VERSION "HNNBNNNYNNNNNNNNNNNNNNNNNNNNNNNNNNNNNNNNNN/4/%%%/4/'%**4NNN///"

NS_ :

BS_:

BU_: BAP_Tester BMS_NV_12V Gateway_Max Klima

BO_ 64 Airbag_01: 8 Gateway_Max
 SG_ Airbag_01_CRC : 0|8@1+ (1,0) [0|255] ""  Klima
 SG_ Airbag_01_BZ : 8|4@1+ (1,0) [0|15] ""  Klima
 SG_ AB_RGS_Anst : 12|4@1+ (1.0,0.0) [0.0|15] ""  Vector__XXX
 SG_ AB_Front_Crash : 16|1@1+ (1.0,0.0) [0.0|1] ""  Vector__XXX
 SG_ AB_Heck_Crash : 17|1@1+ (1.0,0.0) [0.0|1] ""  Vector__XXX
 SG_ AB_SF_Crash : 18|1@1+ (1.0,0.0) [0.0|1] ""  Vector__XXX
 SG_ AB_SB_Crash : 19|1@1+ (1.0,0.0) [0.0|1] ""  Vector__XXX
 SG_ AB_Rollover_Crash : 20|1@1+ (1.0,0.0) [0.0|1] ""  Vector__XXX
 SG_ AB_Crash_Int : 21|3@1+ (1.0,0.0) [0.0|7] ""  Klima
 SG_ AB_Lampe : 24|1@1+ (1.0,0.0) [0.0|1] ""  Vector__XXX
 SG_ AB_Deaktiviert : 25|1@1+ (1.0,0.0) [0.0|1] ""  Vector__XXX
 SG_ AB_VB_deaktiviert : 26|1@1+ (1.0,0.0) [0.0|1] ""  Vector__XXX
 SG_ AB_Systemfehler : 27|1@1+ (1.0,0.0) [0.0|1] ""  Vector__XXX
 SG_ AB_Diagnose : 28|1@1+ (1.0,0.0) [0.0|1] ""  Vector__XXX
 SG_ AB_Stellgliedtest : 29|1@1+ (1.0,0.0) [0.0|1] ""  Klima
 SG_ AB_Erh_Auf_VB : 30|2@1+ (1.0,0.0) [0.0|3] ""  Vector__XXX
 SG_ AB_Gurtwarn_VF : 32|1@1+ (1.0,0.0) [0.0|1] ""  Vector__XXX
 SG_ AB_Gurtwarn_VB : 33|1@1+ (1.0,0.0) [0.0|1] ""  Vector__XXX
 SG_ AB_Anzeige_Fussg : 34|2@1+ (1.0,0.0) [0.0|3] ""  Vector__XXX
 SG_ AB_Texte_AKS : 36|2@1+ (1.0,0.0) [0.0|3] ""  Vector__XXX
 SG_ AB_PAO_Leuchte_Anf : 38|1@1+ (1.0,0.0) [0.0|1] ""  Vector__XXX
 SG_ AB_MKB_gueltig : 39|1@1+ (1.0,0.0) [0.0|1] ""  Vector__XXX
 SG_ AB_MKB_Anforderung : 40|1@1+ (1.0,0.0) [0.0|1] ""  Vector__XXX
 SG_ AB_Versorgungsspannung : 41|1@1+ (1.0,0.0) [0.0|1] ""  Vector__XXX
 SG_ AB_Deaktivierung_HV : 42|3@1+ (1.0,0.0) [0.0|7] ""  Klima
 SG_ AB_EDR_Trigger : 45|2@1+ (1.0,0.0) [0.0|3] ""  Vector__XXX
 SG_ AB_Belegung_VF : 47|2@1+ (1.0,0.0) [0.0|3] ""  Klima
 SG_ AB_Gurtschloss_FA_ext : 49|3@1+ (1.0,0.0) [0.0|7] ""  Vector__XXX
 SG_ AB_Gurtschloss_FA_ext_aktiv : 52|1@1+ (1.0,0.0) [0.0|1] ""  Vector__XXX
 SG_ AB_eCS_Error : 53|1@1+ (1.0,0.0) [0.0|1] ""  Vector__XXX
 SG_ ASM_Masterzeit_02 : 56|8@1+ (0.04,0) [0.00|10.16] "Unit_Secon"  Vector__XXX

BO_ 1312 Airbag_02: 8 Gateway_Max
 SG_ Airbag_02_CRC : 0|8@1+ (1,0) [0|255] ""  Vector__XXX
 SG_ Airbag_02_BZ : 8|4@1+ (1,0) [0|15] ""  Vector__XXX
 SG_ LoGeWa_Event_Kombiwarnung : 12|4@1+ (1.0,0.0) [0.0|15] ""  Vector__XXX
 SG_ AB_Anforderung_eCall : 16|1@1+ (1.0,0.0) [0.0|1] ""  Vector__XXX
 SG_ AB_Anprall_Seite_Beifahrer : 17|1@1+ (1.0,0.0) [0.0|1] ""  Vector__XXX
 SG_ AB_Anprall_Rollover : 18|1@1+ (1.0,0.0) [0.0|1] ""  Vector__XXX
 SG_ AB_Anprall_FGS : 19|1@1+ (1.0,0.0) [0.0|1] ""  Vector__XXX
 SG_ AB_Anprall_Front_Beifahrer : 20|1@1+ (1.0,0.0) [0.0|1] ""  Vector__XXX
 SG_ AB_Anprall_Front_Fahrer : 21|1@1+ (1.0,0.0) [0.0|1] ""  Vector__XXX
 SG_ AB_Anprall_Heck_Beifahrer : 22|1@1+ (1.0,0.0) [0.0|1] ""  Vector__XXX
 SG_ AB_Anprall_Heck_Fahrer : 23|1@1+ (1.0,0.0) [0.0|1] ""  Vector__XXX
 SG_ AB_Wickelklappung_Reihe2_MI : 24|2@1+ (1.0,0.0) [0.0|3] ""  Vector__XXX
 SG_ AB_Belegung_VB : 26|2@1+ (1.0,0.0) [0.0|3] ""  Klima
 SG_ AB_Abschaltanf_SIH_BF : 28|1@1+ (1.0,0.0) [0.0|1] ""  Klima
 SG_ AB_Anprall_Seite_Fahrer : 29|1@1+ (1.0,0.0) [0.0|1] ""  Vector__XXX
 SG_ SC_PAO_Schriftzug_Anf : 30|2@1+ (1.0,0.0) [0.0|3] ""  Vector__XXX
 SG_ SC_PAO_ON_Anf : 32|2@1+ (1.0,0.0) [0.0|3] ""  Vector__XXX
 SG_ SC_PAO_OFF_Anf : 34|2@1+ (1.0,0.0) [0.0|3] ""  Vector__XXX
 SG_ AB_Crashschwere : 36|3@1+ (1.0,0.0) [0.0|7] ""  Vector__XXX
 SG_ AB_Anforderung_USM : 39|1@1+ (1.0,0.0) [0.0|1] ""  Vector__XXX
 SG_ AB_Gurtschloss_FA : 40|2@1+ (1.0,0.0) [0.0|3] ""  Klima
 SG_ AB_Gurtschloss_BF : 42|2@1+ (1.0,0.0) [0.0|3] ""  Klima
 SG_ AB_Gurtschloss_Reihe2_FA : 44|2@1+ (1.0,0.0) [0.0|3] ""  Klima
 SG_ AB_Gurtschloss_Reihe2_MI : 46|2@1+ (1.0,0.0) [0.0|3] ""  Klima
 SG_ AB_Gurtschloss_Reihe2_BF : 48|2@1+ (1.0,0.0) [0.0|3] ""  Klima
 SG_ AB_Gurtschloss_Reihe3_FA : 50|2@1+ (1.0,0.0) [0.0|3] ""  Klima
 SG_ AB_Gurtschloss_Reihe3_MI : 52|2@1+ (1.0,0.0) [0.0|3] ""  Klima
 SG_ AB_Gurtschloss_Reihe3_BF : 54|2@1+ (1.0,0.0) [0.0|3] ""  Klima
 SG_ AB_Sitzpos_Sens_FA : 56|2@1+ (1.0,0.0) [0.0|3] ""  Vector__XXX
 SG_ AB_Sitzpos_Sens_BF : 58|2@1+ (1.0,0.0) [0.0|3] ""  Vector__XXX
 SG_ AB_Wickelklappung_Reihe2_BF : 60|2@1+ (1.0,0.0) [0.0|3] ""  Vector__XXX
 SG_ AB_Wickelklappung_Reihe2_FA : 62|2@1+ (1.0,0.0) [0.0|3] ""  Vector__XXX

BO_ 1349 Airbag_04: 8 Gateway_Max
 SG_ Airbag_04_CRC : 0|8@1+ (1,0) [0|255] ""  Vector__XXX
 SG_ Airbag_04_BZ : 8|4@1+ (1,0) [0|15] ""  Vector__XXX
 SG_ AB_Anprall_Front : 12|1@1+ (1.0,0.0) [0.0|1] ""  Vector__XXX
 SG_ AB_Anprall_Heck : 13|1@1+ (1.0,0.0) [0.0|1] ""  Vector__XXX
 SG_ AB_Gurtwarn_Reihe4_FA : 14|2@1+ (1.0,0.0) [0.0|3] ""  Vector__XXX
 SG_ AB_Gurtwarn_Reihe4_BF : 16|2@1+ (1.0,0.0) [0.0|3] ""  Vector__XXX
 SG_ AB_Gurtwarn_Reihe4_MI : 18|2@1+ (1.0,0.0) [0.0|3] ""  Vector__XXX
 SG_ AB_Gurtwarn_Reihe2_FA : 20|2@1+ (1.0,0.0) [0.0|3] ""  Klima
 SG_ AB_Gurtwarn_Reihe2_BF : 22|2@1+ (1.0,0.0) [0.0|3] ""  Klima
 SG_ AbstWarn_MV_FAS_Fkt_Status : 24|2@1+ (1.0,0.0) [0.0|3] ""  Vector__XXX
 SG_ WarnBrems_Charisma_Status : 26|2@1+ (1.0,0.0) [0.0|3] ""  Vector__XXX
 SG_ WarnBrems_Charisma_FahrPr : 28|4@1+ (1.0,0.0) [0.0|15] ""  Vector__XXX
 SG_ AB_Gurtwarn_Reihe2_MI : 32|2@1+ (1.0,0.0) [0.0|3] ""  Klima
 SG_ AB_Gurtwarn_Reihe3_FA : 34|2@1+ (1.0,0.0) [0.0|3] ""  Vector__XXX
 SG_ AB_Gurtwarn_Reihe3_MI : 36|2@1+ (1.0,0.0) [0.0|3] ""  Vector__XXX
 SG_ AB_Gurtwarn_Reihe3_BF : 38|2@1+ (1.0,0.0) [0.0|3] ""  Vector__XXX
 SG_ LGI_FAS_Fkt_Status : 40|2@1+ (1.0,0.0) [0.0|3] ""  Vector__XXX
 SG_ PreCrash_FAS_Fkt_Status : 42|3@1+ (1.0,0.0) [0.0|7] ""  Vector__XXX
 SG_ AB_Belegung_VF_ext : 45|3@1+ (1.0,0.0) [0.0|7] ""  Klima
 SG_ AB_SBR_hinten_verbau : 48|2@1+ (1.0,0.0) [0.0|3] ""  Klima
 SG_ AB_Belegung_VF_ext_aktiv : 50|1@1+ (1.0,0.0) [0.0|1] ""  Vector__XXX
 SG_ AWV_Einstellung_System_ASG : 51|1@1+ (1.0,0.0) [0.0|1] ""  Vector__XXX
 SG_ AWV_Einstellung_Warnung_ASG : 52|3@1+ (1.0,0.0) [0.0|7] ""  Vector__XXX
 SG_ SC_PreSense_Modus_Warnung_NV : 55|3@1+ (1.0,0.0) [0.0|7] ""  Vector__XXX
 SG_ SC_PreSense_Modus_Warnung_MV : 58|3@1+ (1.0,0.0) [0.0|7] ""  Vector__XXX
 SG_ SC_PreSense_Modus_System_MV : 61|1@1+ (1.0,0.0) [0.0|1] ""  Vector__XXX
 SG_ SC_PreSense_Modus_System_NV : 62|1@1+ (1.0,0.0) [0.0|1] ""  Vector__XXX
 SG_ SC_PreSense_Modus_System_KAS : 63|1@1+ (1.0,0.0) [0.0|1] ""  Vector__XXX

BO_ 2536726528 BAP_ClimateDiag_ASG_01: 8 Gateway_Max
 SG_ BAP_ClimateDiag_ASG_01_Header : 0|64@1+ (1.0,0.0) [0.0|18446744073709551615] ""  Klima

BO_ 2536726544 BAP_ClimateDiag_FSG_01: 8 Klima
 SG_ BAP_ClimateDiag_FSG_01_Header : 0|64@1+ (1.0,0.0) [0.0|18446744073709551615] ""  Gateway_Max

BO_ 2536767264 BAP_Debug_Cmd: 8 BAP_Tester
 SG_ BAP_Debug_Cmd : 0|16@1+ (1.0,0.0) [0.0|65535] ""  Klima

BO_ 2536767280 BAP_Debug_Data: 8 Klima
 SG_ BAP_Debug_Data : 0|64@1+ (1.0,0.0) [0.0|18446744073709551615] ""  BAP_Tester

BO_ 2536702208 BAP_Klima1_ASG_01: 8 Gateway_Max
 SG_ BAP_Klima1_ASG_01_Header : 0|64@1+ (1.0,0.0) [0.0|18446744073709551615] ""  Klima

BO_ 2536702224 BAP_Klima1_FSG_01: 8 Klima
 SG_ BAP_Klima1_FSG_01_Header : 0|64@1+ (1.0,0.0) [0.0|18446744073709551615] ""  Gateway_Max

BO_ 2536702464 BAP_Klima2_ASG_01: 8 Gateway_Max
 SG_ BAP_Klima2_ASG_01_Header : 0|64@1+ (1.0,0.0) [0.0|18446744073709551615] ""  Klima

BO_ 2536702466 BAP_Klima2_ASG_03: 8 Gateway_Max
 SG_ BAP_Klima2_ASG_03_Header : 0|8@1+ (1.0,0.0) [0.0|255] ""  Klima

BO_ 2536702468 BAP_Klima2_ASG_05: 8 Gateway_Max
 SG_ BAP_Klima2_ASG_05_Header : 0|64@1+ (1.0,0.0) [0.0|18446744073709551615] ""  Klima

BO_ 2536702480 BAP_Klima2_FSG_01: 8 Klima
 SG_ BAP_Klima2_FSG_01_Header : 0|8@1+ (1.0,0.0) [0.0|255] ""  Gateway_Max

BO_ 2536718848 BAP_KlimaMaster_ASG_01: 8 Gateway_Max
 SG_ BAP_KlimaMaster_ASG_01_Header : 0|8@1+ (1,0) [0|255] "Unit_None"  Klima

BO_ 2536718849 BAP_KlimaMaster_ASG_02: 8 Gateway_Max
 SG_ BAP_KlimaMaster_ASG_02_Header : 0|8@1+ (1,0) [0|255] "Unit_None"  Klima

BO_ 2536718850 BAP_KlimaMaster_ASG_03: 8 Gateway_Max
 SG_ BAP_KlimaMaster_ASG_03_Header : 0|8@1+ (1,0) [0|255] "Unit_None"  Klima

BO_ 2536718851 BAP_KlimaMaster_ASG_04: 8 Gateway_Max
 SG_ BAP_KlimaMaster_ASG_04_Header : 0|8@1+ (1,0) [0|255] "Unit_None"  Klima

BO_ 2536718864 BAP_KlimaMaster_FSG_01: 8 Klima
 SG_ BAP_KlimaMaster_FSG_01_Header : 0|8@1+ (1,0) [0|255] "Unit_None"  Gateway_Max

BO_ 1626 BCM_01: 8 Gateway_Max
 SG_ BCM_Bremsbelag_Sensor : 12|1@1+ (1.0,0.0) [0.0|1] ""  Vector__XXX
 SG_ BCM_Bremsfluessigkeit_Sensor : 13|1@1+ (1.0,0.0) [0.0|1] ""  Vector__XXX
 SG_ BCM1_Licht_Warn : 14|1@1+ (1.0,0.0) [0.0|1] ""  Vector__XXX
 SG_ BCM_Waschwasser_Sensor : 15|1@1+ (1.0,0.0) [0.0|1] ""  Vector__XXX
 SG_ BCM_Kuehlmittel_Sensor : 16|1@1+ (1.0,0.0) [0.0|1] ""  Vector__XXX
 SG_ BCM1_Kl_15_HW_erkannt : 17|1@1+ (1.0,0.0) [0.0|1] ""  Vector__XXX
 SG_ BCM1_Kl_15_Sig_HW_erkannt : 18|1@1+ (1.0,0.0) [0.0|1] ""  Vector__XXX
 SG_ BCM_Kuehlmittel_Sensor_02 : 19|1@1+ (1.0,0.0) [0.0|1] ""  Vector__XXX
 SG_ BCM1_Hinweis_Lichtnachlauf : 20|1@1+ (1.0,0.0) [0.0|1] ""  Vector__XXX
 SG_ BCM_Offroad_Taste : 21|1@1+ (1.0,0.0) [0.0|1] ""  Vector__XXX
 SG_ BCM_Charisma_Taste2 : 22|1@1+ (1.0,0.0) [0.0|1] ""  Vector__XXX
 SG_ BCM_Hybrid_StSt_Taste_Fehler : 23|1@1+ (1.0,0.0) [0.0|1] ""  Vector__XXX
 SG_ BCM_Hybrid_StartStopp_Taste : 24|1@1+ (1.0,0.0) [0.0|1] ""  Vector__XXX
 SG_ BCM1_Warnblink_Taster : 25|1@1+ (1.0,0.0) [0.0|1] ""  Vector__XXX
 SG_ BCM1_Valet_Parking_Taster : 26|1@1+ (1.0,0.0) [0.0|1] ""  Vector__XXX
 SG_ BCM1_LDS_Stellung : 27|3@1+ (1.0,0.0) [0.0|7] ""  Vector__XXX
 SG_ BCM1_Rueckfahrlicht_Schalter : 30|1@1+ (1.0,0.0) [0.0|1] ""  Klima
 SG_ BCM1_MH_Schalter : 31|1@1+ (1.0,0.0) [0.0|1] ""  Vector__XXX
 SG_ BCM1_MH_WIV_Schalter : 32|1@1+ (1.0,0.0) [0.0|1] ""  Vector__XXX
 SG_ BCM_Eco_Charisma_Taste : 33|1@1+ (1.0,0.0) [0.0|1] ""  Vector__XXX
 SG_ BCM1_NV_Taster : 34|1@1+ (1.0,0.0) [0.0|1] ""  Vector__XXX
 SG_ BCM1_AFS_Lampe : 35|1@1+ (1.0,0.0) [0.0|1] ""  Vector__XXX
 SG_ BCM1_Reisemodus_Texte : 36|2@1+ (1.0,0.0) [0.0|3] ""  Vector__XXX
 SG_ BCM1_Lichtwarn_Texte : 38|2@1+ (1.0,0.0) [0.0|3] ""  Vector__XXX
 SG_ Gong_TFL_Umschaltung : 40|1@1+ (1.0,0.0) [0.0|1] ""  Vector__XXX
 SG_ BCM_ValetTaster_Fkts_LED : 42|1@1+ (1.0,0.0) [0.0|1] ""  Vector__XXX
 SG_ LRH_Taster : 43|1@1+ (1.0,0.0) [0.0|1] ""  Vector__XXX
 SG_ APS_Tongeber_defekt : 44|1@1+ (1.0,0.0) [0.0|1] ""  Vector__XXX
 SG_ BCM1_EasyEntry_Status : 45|1@1+ (1.0,0.0) [0.0|1] ""  Vector__XXX
 SG_ BCM1_Lenksaeule_aktiv : 46|1@1+ (1.0,0.0) [0.0|1] ""  Vector__XXX
 SG_ BCM1_Spannungs_Anf : 47|2@1+ (1.0,0.0) [0.0|3] ""  Vector__XXX
 SG_ DWA_Alarmquelle : 49|5@1+ (1.0,0.0) [0.0|31] ""  Vector__XXX
 SG_ DWA_Einschraenkung : 54|1@1+ (1.0,0.0) [0.0|1] ""  Vector__XXX
 SG_ BCM_HBFS_EOE_aktiv : 56|1@1+ (1.0,0.0) [0.0|1] ""  Vector__XXX
 SG_ BCM_HFS_EOE_aktiv : 57|1@1+ (1.0,0.0) [0.0|1] ""  Vector__XXX
 SG_ BCM_Anf_AAW_MoLaWa : 58|2@1+ (1.0,0.0) [0.0|3] ""  Vector__XXX
 SG_ BCM_Handbremse_Hinweis : 60|1@1+ (1.0,0.0) [0.0|1] ""  Vector__XXX
 SG_ BCM_Waehlhebel_P_Hinweis : 61|1@1+ (1.0,0.0) [0.0|1] ""  Vector__XXX
 SG_ BCM1_Fahrlicht_Hinweis : 62|1@1+ (1.0,0.0) [0.0|1] ""  Vector__XXX
 SG_ BCM_HDF_betaetigt : 63|1@1+ (1.0,0.0) [0.0|1] ""  Vector__XXX

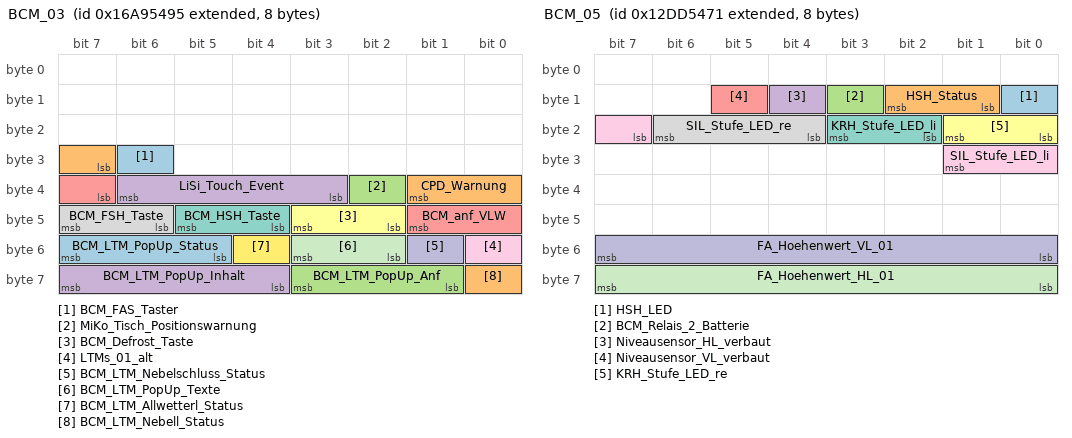
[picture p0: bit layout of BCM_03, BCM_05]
BO_ 2527679637 BCM_03: 8 Gateway_Max
 SG_ BCM_FAS_Taster : 30|1@1+ (1.0,0.0) [0.0|1] ""  Vector__XXX
 SG_ CPD_Warnung : 31|3@1+ (1.0,0.0) [0.0|7] ""  Vector__XXX
 SG_ MiKo_Tisch_Positionswarnung : 34|1@1+ (1.0,0.0) [0.0|1] ""  Vector__XXX
 SG_ LiSi_Touch_Event : 35|4@1+ (1.0,0.0) [0.0|15] ""  Vector__XXX
 SG_ BCM_anf_VLW : 39|3@1+ (1.0,0.0) [0.0|7] ""  Vector__XXX
 SG_ BCM_Defrost_Taste : 42|2@1+ (1.0,0.0) [0.0|3] ""  Klima
 SG_ BCM_HSH_Taste : 44|2@1+ (1.0,0.0) [0.0|3] ""  Klima
 SG_ BCM_FSH_Taste : 46|2@1+ (1.0,0.0) [0.0|3] ""  Klima
 SG_ LTMs_01_alt : 48|1@1+ (1.0,0.0) [0.0|1] ""  Klima
 SG_ BCM_LTM_Nebelschluss_Status : 49|1@1+ (1.0,0.0) [0.0|1] ""  Vector__XXX
 SG_ BCM_LTM_PopUp_Texte : 50|2@1+ (1.0,0.0) [0.0|3] ""  Vector__XXX
 SG_ BCM_LTM_Allwetterl_Status : 52|1@1+ (1.0,0.0) [0.0|1] ""  Vector__XXX
 SG_ BCM_LTM_PopUp_Status : 53|3@1+ (1.0,0.0) [0.0|7] ""  Vector__XXX
 SG_ BCM_LTM_Nebell_Status : 56|1@1+ (1.0,0.0) [0.0|1] ""  Vector__XXX
 SG_ BCM_LTM_PopUp_Anf : 57|3@1+ (1.0,0.0) [0.0|7] ""  Vector__XXX
 SG_ BCM_LTM_PopUp_Inhalt : 60|4@1+ (1.0,0.0) [0.0|15] ""  Vector__XXX

BO_ 2463978609 BCM_05: 8 Gateway_Max
 SG_ HSH_LED : 8|1@1+ (1.0,0.0) [0.0|1] ""  Vector__XXX
 SG_ HSH_Status : 9|2@1+ (1.0,0.0) [0.0|3] ""  Klima
 SG_ BCM_Relais_2_Batterie : 11|1@1+ (1.0,0.0) [0.0|1] ""  Vector__XXX
 SG_ Niveausensor_HL_verbaut : 12|1@1+ (1.0,0.0) [0.0|1] ""  Vector__XXX
 SG_ Niveausensor_VL_verbaut : 13|1@1+ (1.0,0.0) [0.0|1] ""  Vector__XXX
 SG_ KRH_Stufe_LED_re : 16|2@1+ (1.0,0.0) [0.0|3] ""  Klima
 SG_ KRH_Stufe_LED_li : 18|2@1+ (1.0,0.0) [0.0|3] ""  Klima
 SG_ SIL_Stufe_LED_re : 20|3@1+ (1.0,0.0) [0.0|7] ""  Klima
 SG_ SIL_Stufe_LED_li : 23|3@1+ (1.0,0.0) [0.0|7] ""  Klima
 SG_ FA_Hoehenwert_VL_01 : 48|8@1+ (0.4,0) [0.0|100.0] "Unit_PerCent"  Vector__XXX
 SG_ FA_Hoehenwert_HL_01 : 56|8@1+ (0.4,0) [0.0|100.0] "Unit_PerCent"  Vector__XXX

BO_ 1635 BEM_02: 8 Gateway_Max
 SG_ NVEM_Abschaltstufe : 0|2@1+ (1.0,0.0) [0.0|3] ""  Klima
 SG_ BEM_STH_Zielzeit : 3|4@1+ (5,0) [0|60] "Unit_Minut"  Klima
 SG_ BEM_MMI_Vorwarnung : 7|1@1+ (1.0,0.0) [0.0|1] ""  Vector__XXX
 SG_ BEM_HL_Kontingentierung : 8|6@1+ (50,-1000) [-1000|1000] "Unit_Watt"  Vector__XXX
 SG_ NVEM_Freigabe_ZusBatt_Laden : 14|1@1+ (1.0,0.0) [0.0|1] ""  Vector__XXX
 SG_ NVEM_Anf_SD_schalten : 15|1@1+ (1.0,0.0) [0.0|1] ""  Vector__XXX
 SG_ BEM_Generatordiagnose : 16|2@1+ (1.0,0.0) [0.0|3] ""  Vector__XXX
 SG_ BEM_Red_Innengeblaese : 18|2@1+ (1.0,0.0) [0.0|3] ""  Klima
 SG_ BEM_STH_Einschaltverbot : 20|1@1+ (1.0,0.0) [0.0|1] ""  Klima
 SG_ BEM_HL_Regelung_Status : 21|3@1+ (1.0,0.0) [0.0|7] ""  Vector__XXX
 SG_ BEM_Ladezustand : 24|4@1+ (10,0) [0|100] "Unit_PerCent"  Vector__XXX
 SG_ BEM_Batteriediagnose : 28|3@1+ (1.0,0.0) [0.0|7] ""  Vector__XXX
 SG_ MIB_Stromsparmodus : 31|1@1+ (1.0,0.0) [0.0|1] ""  Vector__XXX
 SG_ BEM_DFM : 32|5@1+ (3.225,0.025) [0.025|100.000] ""  Vector__XXX
 SG_ BEM_REK_aktiv : 37|1@1+ (1.0,0.0) [0.0|1] ""  Vector__XXX
 SG_ BEM_EMLIN_ungueltig : 38|1@1+ (1.0,0.0) [0.0|1] ""  Vector__XXX
 SG_ BEM_Batt_Ab : 39|1@1+ (1.0,0.0) [0.0|1] ""  Vector__XXX
 SG_ BEM_UBDM : 40|8@1+ (0.05,5) [5.05|17.70] "Unit_Volt"  Vector__XXX
 SG_ BEM_UGenSoll : 48|6@1+ (0.1,10.6) [10.6|16.0] "Unit_Volt"  Vector__XXX
 SG_ BEM_Anf_KL15_schalten : 54|2@1+ (1.0,0.0) [0.0|3] ""  Vector__XXX
 SG_ NVEM_Batterie_Service : 56|2@1+ (1.0,0.0) [0.0|3] ""  Vector__XXX
 SG_ NVEM_Freigabe_OnlineUpdate : 58|1@1+ (1.0,0.0) [0.0|1] ""  Vector__XXX
 SG_ NVEM_Freigabe_ORU4 : 59|2@1+ (1.0,0.0) [0.0|3] ""  Vector__XXX
 SG_ NVEM_Verbraucherabsch_Anz : 61|1@1+ (1.0,0.0) [0.0|1] ""  Vector__XXX

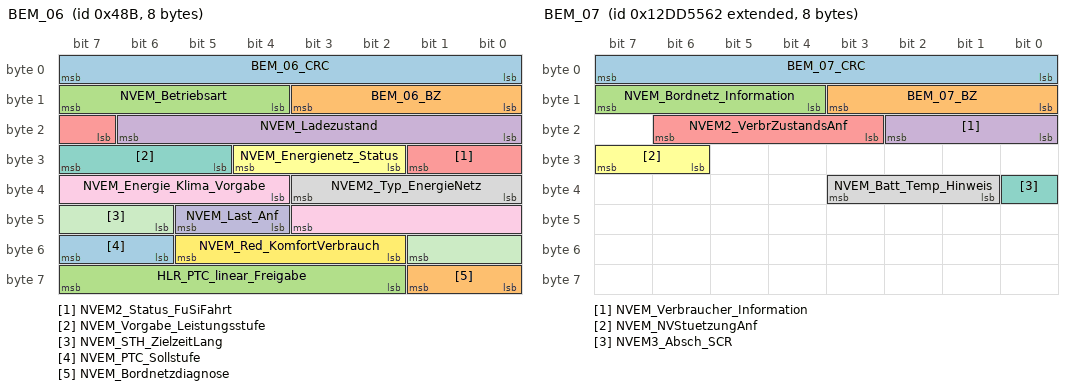
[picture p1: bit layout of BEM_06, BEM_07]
BO_ 1163 BEM_06: 8 Gateway_Max
 SG_ BEM_06_CRC : 0|8@1+ (1,0) [0|255] ""  Vector__XXX
 SG_ BEM_06_BZ : 8|4@1+ (1,0) [0|15] ""  Vector__XXX
 SG_ NVEM_Betriebsart : 12|4@1+ (1.0,0.0) [0.0|15] ""  Vector__XXX
 SG_ NVEM_Ladezustand : 16|7@1+ (1,0) [0|100] "Unit_PerCent"  Vector__XXX
 SG_ NVEM2_Status_FuSiFahrt : 23|3@1+ (1.0,0.0) [0.0|7] ""  Vector__XXX
 SG_ NVEM_Energienetz_Status : 26|3@1+ (1.0,0.0) [0.0|7] ""  Vector__XXX
 SG_ NVEM_Vorgabe_Leistungsstufe : 29|3@1+ (1.0,0.0) [0.0|7] ""  Vector__XXX
 SG_ NVEM2_Typ_EnergieNetz : 32|4@1+ (1.0,0.0) [0.0|15] ""  Vector__XXX
 SG_ NVEM_Energie_Klima_Vorgabe : 36|8@1+ (10,0) [0|2530] "Unit_WattHour"  Vector__XXX
 SG_ NVEM_Last_Anf : 44|2@1+ (1.0,0.0) [0.0|3] ""  Klima
 SG_ NVEM_STH_ZielzeitLang : 46|4@1+ (10,0) [0|120] "Unit_Minut"  Klima
 SG_ NVEM_Red_KomfortVerbrauch : 50|4@1+ (1.0,0.0) [0.0|15] ""  Vector__XXX
 SG_ NVEM_PTC_Sollstufe : 54|2@1+ (1.0,0.0) [0.0|3] ""  Vector__XXX
 SG_ NVEM_Bordnetzdiagnose : 56|2@1+ (1.0,0.0) [0.0|3] ""  Vector__XXX
 SG_ HLR_PTC_linear_Freigabe : 58|6@1+ (50,0) [0|3100] "Unit_Watt"  Vector__XXX

BO_ 2463978850 BEM_07: 8 Gateway_Max
 SG_ BEM_07_CRC : 0|8@1+ (1,0) [0|255] ""  Vector__XXX
 SG_ BEM_07_BZ : 8|4@1+ (1,0) [0|15] ""  Vector__XXX
 SG_ NVEM_Bordnetz_Information : 12|4@1+ (1.0,0.0) [0.0|15] ""  Vector__XXX
 SG_ NVEM_Verbraucher_Information : 16|3@1+ (1.0,0.0) [0.0|7] ""  Vector__XXX
 SG_ NVEM2_VerbrZustandsAnf : 19|4@1+ (1.0,0.0) [0.0|15] ""  Klima
 SG_ NVEM_NVStuetzungAnf : 30|2@1+ (1.0,0.0) [0.0|3] ""  Vector__XXX
 SG_ NVEM3_Absch_SCR : 32|1@1+ (1.0,0.0) [0.0|1] ""  Vector__XXX
 SG_ NVEM_Batt_Temp_Hinweis : 33|3@1+ (1.0,0.0) [0.0|7] ""  Vector__XXX

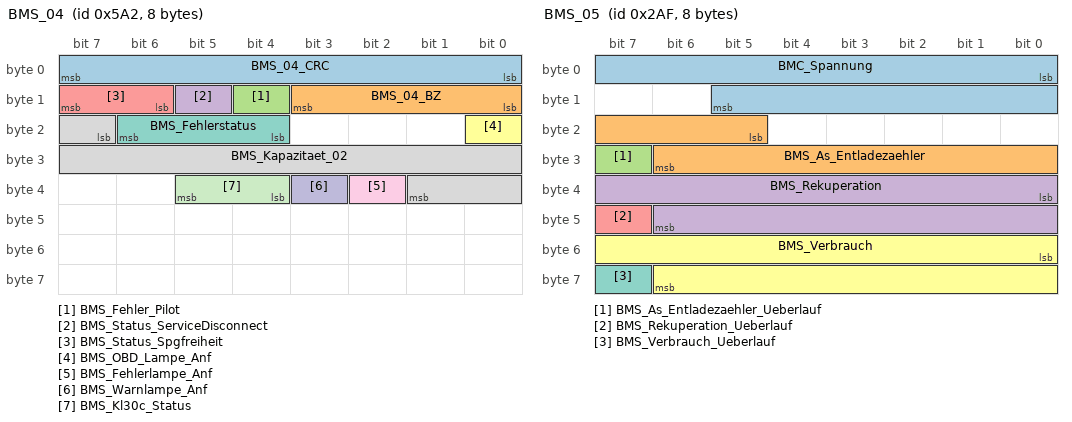
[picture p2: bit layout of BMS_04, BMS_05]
BO_ 1442 BMS_04: 8 Vector__XXX
 SG_ BMS_04_CRC : 0|8@1+ (1,0) [0|255] ""  Gateway_Max
 SG_ BMS_04_BZ : 8|4@1+ (1,0) [0|15] ""  Gateway_Max
 SG_ BMS_Fehler_Pilot : 12|1@1+ (1.0,0.0) [0.0|1] ""  Gateway_Max
 SG_ BMS_Status_ServiceDisconnect : 13|1@1+ (1.0,0.0) [0.0|1] ""  Gateway_Max
 SG_ BMS_Status_Spgfreiheit : 14|2@1+ (1.0,0.0) [0.0|3] ""  Gateway_Max
 SG_ BMS_OBD_Lampe_Anf : 16|1@1+ (1.0,0.0) [0.0|1] ""  Gateway_Max
 SG_ BMS_Fehlerstatus : 20|3@1+ (1.0,0.0) [0.0|7] ""  Gateway_Max
 SG_ BMS_Kapazitaet_02 : 23|11@1+ (0.2,0) [0.0|409.2] "Unit_AmperHour"  Gateway_Max
 SG_ BMS_Fehlerlampe_Anf : 34|1@1+ (1.0,0.0) [0.0|1] ""  Gateway_Max
 SG_ BMS_Warnlampe_Anf : 35|1@1+ (1.0,0.0) [0.0|1] ""  Gateway_Max
 SG_ BMS_Kl30c_Status : 36|2@1+ (1.0,0.0) [0.0|3] ""  Gateway_Max

BO_ 1450 BMS_04_SOK_Signatur: 8 Vector__XXX
 SG_ SOK_BMS_04_Signatur : 0|64@1+ (1,0) [1|18446744073709551615] "Unit_None"  Gateway_Max

BO_ 687 BMS_05: 8 Vector__XXX
 SG_ BMC_Spannung : 0|14@1+ (0.0625,0) [0.0000|1023.7500] "Unit_Volt"  Gateway_Max
 SG_ BMS_As_Entladezaehler : 21|10@1+ (1,0) [0|1023] "Unit_AmperSecon"  Gateway_Max
 SG_ BMS_As_Entladezaehler_Ueberlauf : 31|1@1+ (1.0,0.0) [0.0|1] ""  Gateway_Max
 SG_ BMS_Rekuperation : 32|15@1+ (10,0) [0|327670] "Unit_WattSecond"  Gateway_Max
 SG_ BMS_Rekuperation_Ueberlauf : 47|1@1+ (1.0,0.0) [0.0|1] ""  Gateway_Max
 SG_ BMS_Verbrauch : 48|15@1+ (10,0) [0|327670] "Unit_WattSecond"  Gateway_Max
 SG_ BMS_Verbrauch_Ueberlauf : 63|1@1+ (1.0,0.0) [0.0|1] ""  Gateway_Max

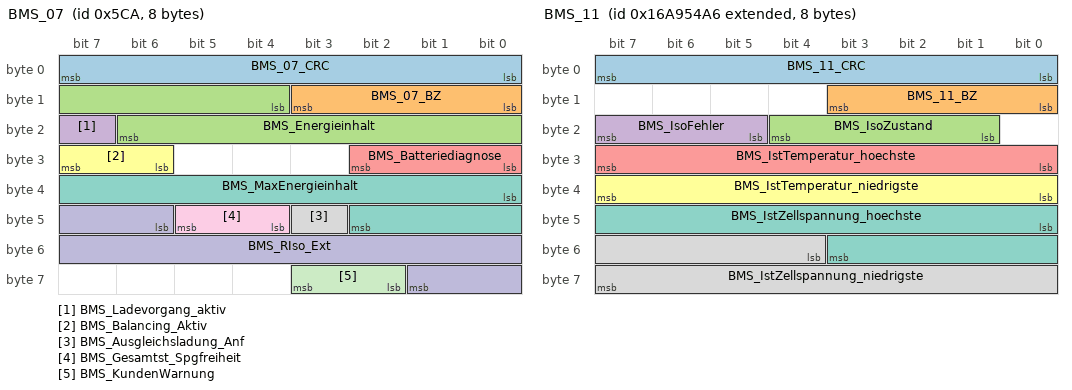
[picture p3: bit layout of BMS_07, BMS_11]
BO_ 1482 BMS_07: 8 Vector__XXX
 SG_ BMS_07_CRC : 0|8@1+ (1,0) [0|255] ""  Gateway_Max
 SG_ BMS_07_BZ : 8|4@1+ (1,0) [0|15] ""  Gateway_Max
 SG_ BMS_Energieinhalt : 12|11@1+ (50,0) [0|102250] "Unit_WattHour"  Gateway_Max
 SG_ BMS_Ladevorgang_aktiv : 23|1@1+ (1.0,0.0) [0.0|1] ""  Gateway_Max
 SG_ BMS_Batteriediagnose : 24|3@1+ (1.0,0.0) [0.0|7] ""  Gateway_Max
 SG_ BMS_Balancing_Aktiv : 30|2@1+ (1.0,0.0) [0.0|3] ""  Gateway_Max
 SG_ BMS_MaxEnergieinhalt : 32|11@1+ (50,0) [0|102250] "Unit_WattHour"  Gateway_Max
 SG_ BMS_Ausgleichsladung_Anf : 43|1@1+ (1.0,0.0) [0.0|1] ""  Gateway_Max
 SG_ BMS_Gesamtst_Spgfreiheit : 44|2@1+ (1.0,0.0) [0.0|3] ""  Gateway_Max
 SG_ BMS_RIso_Ext : 46|12@1+ (5,0) [0|20465] "Unit_KiloOhm"  Gateway_Max
 SG_ BMS_KundenWarnung : 58|2@1+ (1.0,0.0) [0.0|3] ""  Gateway_Max,Klima

BO_ 2527679654 BMS_11: 8 Vector__XXX
 SG_ BMS_11_CRC : 0|8@1+ (1,0) [0|255] ""  Gateway_Max
 SG_ BMS_11_BZ : 8|4@1+ (1,0) [0|15] ""  Gateway_Max
 SG_ BMS_IsoZustand : 17|4@1+ (1.0,0.0) [0.0|15] ""  Gateway_Max
 SG_ BMS_IsoFehler : 21|3@1+ (1.0,0.0) [0.0|7] ""  Gateway_Max
 SG_ BMS_IstTemperatur_hoechste : 24|8@1+ (0.5,-40) [-40.0|86.0] "Unit_DegreCelsi"  Gateway_Max
 SG_ BMS_IstTemperatur_niedrigste : 32|8@1+ (0.5,-40) [-40.0|86.0] "Unit_DegreCelsi"  Gateway_Max
 SG_ BMS_IstZellspannung_hoechste : 40|12@1+ (1,1000) [1000|5091] "Unit_MilliVolt"  Gateway_Max
 SG_ BMS_IstZellspannung_niedrigste : 52|12@1+ (1,1000) [1000|5091] "Unit_MilliVolt"  Gateway_Max

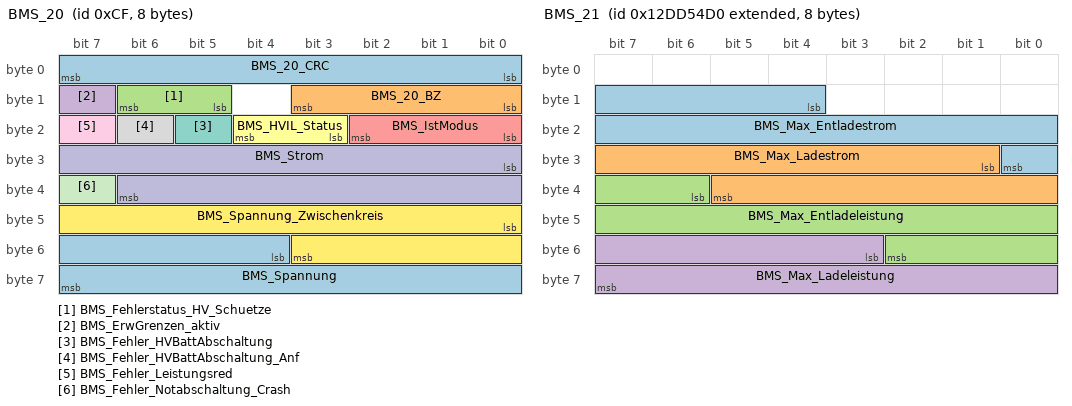
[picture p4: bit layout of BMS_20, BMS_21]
BO_ 207 BMS_20: 8 Vector__XXX
 SG_ BMS_20_CRC : 0|8@1+ (1,0) [0|255] ""  Gateway_Max
 SG_ BMS_20_BZ : 8|4@1+ (1,0) [0|15] ""  Gateway_Max
 SG_ BMS_Fehlerstatus_HV_Schuetze : 13|2@1+ (1.0,0.0) [0.0|3] ""  Gateway_Max
 SG_ BMS_ErwGrenzen_aktiv : 15|1@1+ (1.0,0.0) [0.0|1] ""  Gateway_Max
 SG_ BMS_IstModus : 16|3@1+ (1.0,0.0) [0.0|7] ""  Gateway_Max
 SG_ BMS_HVIL_Status : 19|2@1+ (1.0,0.0) [0.0|3] ""  Gateway_Max
 SG_ BMS_Fehler_HVBattAbschaltung : 21|1@1+ (1.0,0.0) [0.0|1] ""  Gateway_Max
 SG_ BMS_Fehler_HVBattAbschaltung_Anf : 22|1@1+ (1.0,0.0) [0.0|1] ""  Gateway_Max
 SG_ BMS_Fehler_Leistungsred : 23|1@1+ (1.0,0.0) [0.0|1] ""  Gateway_Max
 SG_ BMS_Strom : 24|15@1+ (0.1,-1630) [-1630.0|1630.0] "Unit_Amper"  Gateway_Max
 SG_ BMS_Fehler_Notabschaltung_Crash : 39|1@1+ (1.0,0.0) [0.0|1] ""  Gateway_Max
 SG_ BMS_Spannung_Zwischenkreis : 40|12@1+ (0.5,-1000) [-1000.0|1000.0] "Unit_Volt"  Gateway_Max
 SG_ BMS_Spannung : 52|12@1+ (0.25,0) [0.00|1000.00] "Unit_Volt"  Gateway_Max,Klima

BO_ 2463978704 BMS_21: 8 Vector__XXX
 SG_ BMS_Max_Entladestrom : 12|13@1+ (0.2,0) [0.0|1630.0] "Unit_Amper"  Gateway_Max
 SG_ BMS_Max_Ladestrom : 25|13@1+ (0.2,0) [0.0|1630.0] "Unit_Amper"  Gateway_Max
 SG_ BMS_Max_Entladeleistung : 38|13@1+ (100,0) [0|818000] "Unit_Watt"  Gateway_Max
 SG_ BMS_Max_Ladeleistung : 51|13@1+ (100,0) [0|818000] "Unit_Watt"  Gateway_Max

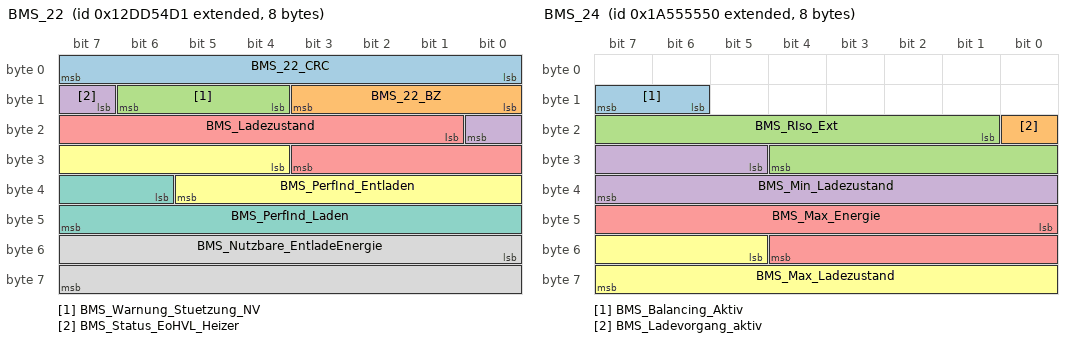
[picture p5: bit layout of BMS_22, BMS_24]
BO_ 2463978705 BMS_22: 8 Vector__XXX
 SG_ BMS_22_CRC : 0|8@1+ (1,0) [0|255] ""  Gateway_Max
 SG_ BMS_22_BZ : 8|4@1+ (1,0) [0|15] ""  Gateway_Max
 SG_ BMS_Warnung_Stuetzung_NV : 12|3@1+ (1.0,0.0) [0.0|7] ""  Gateway_Max
 SG_ BMS_Status_EoHVL_Heizer : 15|2@1+ (1.0,0.0) [0.0|3] ""  Gateway_Max
 SG_ BMS_Ladezustand : 17|11@1+ (0.05,0) [0.00|100.00] "Unit_PerCent"  Gateway_Max
 SG_ BMS_PerfInd_Entladen : 28|10@1+ (0.2,0) [0.0|200.0] "Unit_PerCent"  Gateway_Max
 SG_ BMS_PerfInd_Laden : 38|10@1+ (0.2,0) [0.0|200.0] "Unit_PerCent"  Gateway_Max
 SG_ BMS_Nutzbare_EntladeEnergie : 48|16@1+ (5,0) [0|327400] "Unit_WattHour"  Gateway_Max

BO_ 2589283664 BMS_24: 8 Vector__XXX
 SG_ BMS_Balancing_Aktiv : 14|2@1+ (1.0,0.0) [0.0|3] ""  Gateway_Max
 SG_ BMS_Ladevorgang_aktiv : 16|1@1+ (1.0,0.0) [0.0|1] ""  Gateway_Max
 SG_ BMS_RIso_Ext : 17|12@1+ (5,0) [0|20465] "Unit_KiloOhm"  Gateway_Max
 SG_ BMS_Min_Ladezustand : 29|11@1+ (0.05,0) [0.00|100.00] "Unit_PerCent"  Gateway_Max
 SG_ BMS_Max_Energie : 40|13@1+ (40,0) [0|327400] "Unit_WattHour"  Gateway_Max
 SG_ BMS_Max_Ladezustand : 53|11@1+ (0.05,0) [0.00|100.00] "Unit_PerCent"  Gateway_Max

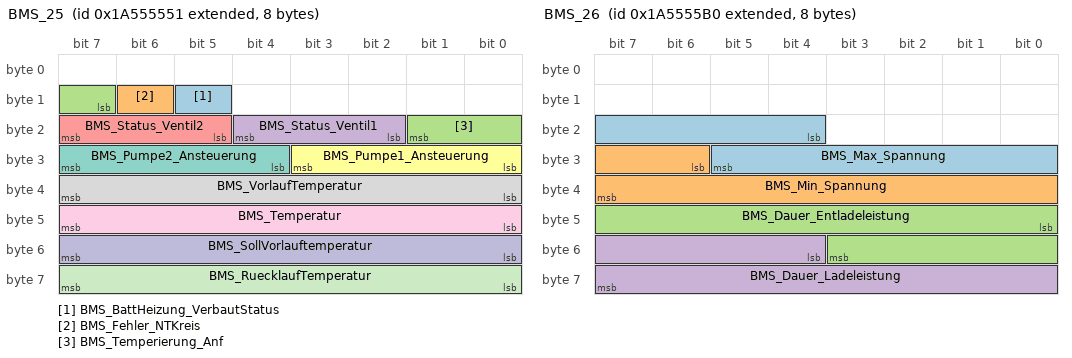
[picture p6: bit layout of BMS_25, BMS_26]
BO_ 2589283665 BMS_25: 8 Vector__XXX
 SG_ BMS_BattHeizung_VerbautStatus : 13|1@1+ (1.0,0.0) [0.0|1] ""  Gateway_Max
 SG_ BMS_Fehler_NTKreis : 14|1@1+ (1.0,0.0) [0.0|1] ""  Gateway_Max
 SG_ BMS_Temperierung_Anf : 15|3@1+ (1.0,0.0) [0.0|7] ""  Gateway_Max,Klima
 SG_ BMS_Status_Ventil1 : 18|3@1+ (1.0,0.0) [0.0|7] ""  Gateway_Max,Klima
 SG_ BMS_Status_Ventil2 : 21|3@1+ (1.0,0.0) [0.0|7] ""  Gateway_Max,Klima
 SG_ BMS_Pumpe1_Ansteuerung : 24|4@1+ (10,0) [0|100] "Unit_PerCent"  Gateway_Max,Klima
 SG_ BMS_Pumpe2_Ansteuerung : 28|4@1+ (10,0) [0|100] "Unit_PerCent"  Gateway_Max,Klima
 SG_ BMS_VorlaufTemperatur : 32|8@1+ (0.5,-40) [-40.0|86.0] "Unit_DegreCelsi"  Gateway_Max,Klima
 SG_ BMS_Temperatur : 40|8@1+ (0.5,-40) [-40.0|86.5] "Unit_DegreCelsi"  Gateway_Max,Klima
 SG_ BMS_SollVorlauftemperatur : 48|8@1+ (0.5,-40) [-40.0|86.5] "Unit_DegreCelsi"  Gateway_Max,Klima
 SG_ BMS_RuecklaufTemperatur : 56|8@1+ (0.5,-40) [-40.0|86.0] "Unit_DegreCelsi"  Gateway_Max,Klima

BO_ 2589283760 BMS_26: 8 Vector__XXX
 SG_ BMS_Max_Spannung : 20|10@1+ (1,0) [0|1000] "Unit_Volt"  Gateway_Max
 SG_ BMS_Min_Spannung : 30|10@1+ (1,0) [0|1000] "Unit_Volt"  Gateway_Max
 SG_ BMS_Dauer_Entladeleistung : 40|12@1+ (200,0) [0|818000] "Unit_Watt"  Gateway_Max
 SG_ BMS_Dauer_Ladeleistung : 52|12@1+ (200,0) [0|818000] "Unit_Watt"  Gateway_Max

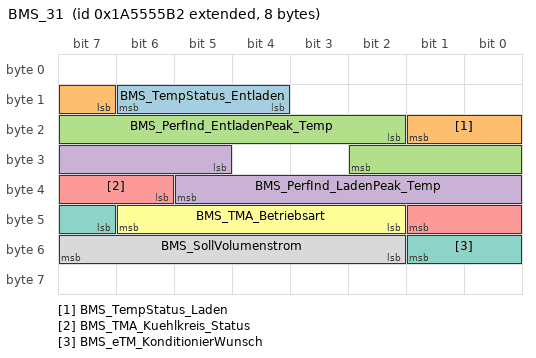
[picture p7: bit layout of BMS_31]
BO_ 2589283762 BMS_31: 8 Vector__XXX
 SG_ BMS_TempStatus_Entladen : 12|3@1+ (1.0,0.0) [0.0|7] ""  Gateway_Max
 SG_ BMS_TempStatus_Laden : 15|3@1+ (1.0,0.0) [0.0|7] ""  Gateway_Max
 SG_ BMS_PerfInd_EntladenPeak_Temp : 18|9@1+ (0.2,0) [0.0|100.0] "Unit_PerCent"  Gateway_Max
 SG_ BMS_PerfInd_LadenPeak_Temp : 29|9@1+ (0.2,0) [0.0|100.0] "Unit_PerCent"  Gateway_Max
 SG_ BMS_TMA_Kuehlkreis_Status : 38|4@1+ (1.0,0.0) [0.0|15] ""  Gateway_Max
 SG_ BMS_TMA_Betriebsart : 42|5@1+ (1.0,0.0) [0.0|31] ""  Gateway_Max
 SG_ BMS_eTM_KonditionierWunsch : 47|3@1+ (1.0,0.0) [0.0|7] ""  Gateway_Max
 SG_ BMS_SollVolumenstrom : 50|6@1+ (1,0) [0|61] "Unit_LiterPerMinut"  Gateway_Max

BO_ 2331595856 BMS_34: 32 Vector__XXX
 SG_ BMS_UBE : 16|16@1+ (5,-7400) [-7400|320000] "Unit_WattHour"  Gateway_Max
 SG_ BMS_UBE_T : 32|16@1+ (5,-7400) [-7400|320000] "Unit_WattHour"  Gateway_Max
 SG_ BMS_Max_UBE : 48|16@1+ (5,-7400) [-7400|320000] "Unit_WattHour"  Gateway_Max
 SG_ BMS_Nennspannung : 64|11@1+ (0.5,0) [0.0|1000.0] "Unit_Volt"  Gateway_Max
 SG_ BMS_DC_Ladeschuetze_Ist : 75|3@1+ (1.0,0.0) [0.0|7] ""  Gateway_Max
 SG_ BMS_Hauptschuetze_Ist : 78|3@1+ (1.0,0.0) [0.0|7] ""  Gateway_Max
 SG_ BMS_UBE_Indikator : 81|11@1+ (0.05,0) [0.00|100.00] "Unit_PerCent"  Gateway_Max
 SG_ BMS_UBE_Indik_last_update_km : 92|20@1+ (1,0) [0|1000000] "Unit_KiloMeter"  Gateway_Max
 SG_ BMS_Last_Chg_adeq_SOCswing_Day : 112|5@1+ (1,0) [1|31] "Unit_Day"  Gateway_Max
 SG_ BMS_Last_Chg_adeq_SOCswing_Month : 117|4@1+ (1,0) [1|12] "Unit_Month"  Gateway_Max
 SG_ BMS_Last_Chg_adeq_SOCswing_Year : 121|7@1+ (1,2000) [2001|2127] "Unit_Year"  Gateway_Max
 SG_ BMS_EnergieVorhalt : 128|16@1+ (0.1,0) [0.0|6400.0] "Unit_KiloWattHour"  Gateway_Max
 SG_ BMS_Range_Indikator : 144|11@1+ (0.05,0) [0.00|100.00] "Unit_PerCent"  Gateway_Max
 SG_ SOK_BMS_34_Signatur : 192|64@1+ (1,0) [1|18446744073709551615] "Unit_None"  Gateway_Max

CM_ "EVCANFD_V14.09F Generated by BusNet_NG_Produktiv 9.25.5";
CM_ BU_ Klima "Klima im MQBw_Baseline";

CM_ BO_ 1635 "DLC=8 ab D4 gültig";

CM_ SG_ 64 AB_Anzeige_Fussg "Anzeige für ausgelöste Fussgängerschutz-Aktuatorik";
CM_ SG_ 64 AB_Belegung_VF "Belegungserkennung vorne Fahrer.";
CM_ SG_ 64 AB_Crash_Int "Crash_Intensität_1 = fahrzeugabhängige Reaktionen im Crash
Crash_Intensität_2 = fahrzeugabhängige Reaktionen im Crash
Crash_Intensität_3 = fahrzeugabhängige Reaktionen im Crash

Die jeweiligen fahrzeugabhängigen Reaktionen im Crash sind in einem separ";
CM_ SG_ 64 AB_Deaktiviert "Airbag oder Gurtstraffer wurden per Anpassung deaktiviert: Aktualisierung erst nach Selbsttest";
CM_ SG_ 64 AB_Deaktivierung_HV "Deaktivierung des HV-Systems und der HV-Teilnehmer im Crash (u.a. Hybrid- und Elektrofahrzeuge)";
CM_ SG_ 64 AB_Diagnose "Airbag in Diagnose";
CM_ SG_ 64 AB_eCS_Error "Signal zur Anforderung der Anzeige von Störungen im System der elektrischen Gurtverriegelung";
CM_ SG_ 64 AB_EDR_Trigger "Triggerbedingung zur dezentralen Aufzeichnung unfallrelevanter Daten im Event Data Recorder";
CM_ SG_ 64 AB_Erh_Auf_VB "Der Fahrer soll bei einem Statuswechsel des Beifahrerairbags (ausgelöst durch die Beifahrerinsassenerkennung oder den Schlüsselschloßschalter) aufmerksam gemacht werden durch eine Anzeige im Kombi. Nur Audi: gültig für: AB2 (4-Türer AU352), B7, C6, D3";
CM_ SG_ 64 AB_Front_Crash "Bit wird bei Überschreitung der Gurtstraffer-, US- und RdW-Schwelle gesetzt";
CM_ SG_ 64 AB_Gurtschloss_FA_ext "Das Ergebnis der Basisfunktion 'Plausibilisierung Gurtschloss' des Verlassenskonzepts wird im Signal dargestellt.";
CM_ SG_ 64 AB_Gurtschloss_FA_ext_aktiv "Über dieses Signal wird signalisiert ob die Erweiterte Gurtdiagnose (Ergebnis wird im Signal AB_Gurtschloss_FA_ext dargestellt) aktiviert oder deaktiviert ist.";
CM_ SG_ 64 AB_Gurtwarn_VB "Beifahrer hat Gurt nicht gesteckt, Anzeige im Kombi";
CM_ SG_ 64 AB_Gurtwarn_VF "Fahrer hat Gurt nicht gesteckt, Anzeige im Kombi";
CM_ SG_ 64 AB_Heck_Crash "Wird für alle neu anlaufenden Projekte umgesetzt: AB8.4, Audi8/VW8";
CM_ SG_ 64 AB_Lampe "Sicherheitswarnlampe im Kombi wird vom Airbag-SG angesteuert; Zustand der Lampe wird auf dem CAN-Bus ausgegeben (auch Blinkinformation).";
CM_ SG_ 64 AB_MKB_Anforderung "Anforderung Multi-Kollisions-Bremsung";
CM_ SG_ 64 AB_MKB_gueltig "Multi-Kollisions-Bremsung im Airbag freigeschaltet";
CM_ SG_ 64 AB_PAO_Leuchte_Anf "Anforderung an die Passenger-Airbag-Off Leuchte in der Dachkonsole (ein / aus), Einsatz nur bei PAG";
CM_ SG_ 64 AB_RGS_Anst "PreCrash-Ansteuerung reversibler Gurtstraffer (Aktivierung und Kraftniveau)

10xx = deaktiviert";
CM_ SG_ 64 AB_Rollover_Crash "Wird im B6/B7 Cabrio und New Beetle Cabrio bedient. ";
CM_ SG_ 64 AB_SB_Crash "Z.Zt. nur in Verbindung mit Crash-Intensität >= 100b (Kraftstoffpumpenabschaltung) verwendet.
";
CM_ SG_ 64 AB_SF_Crash "Z.Zt. nur in Verbindung mit Crash-Intensität >= 100b (Kraftstoffpumpenabschaltung) verwendet.";
CM_ SG_ 64 AB_Stellgliedtest "Information, ob Airbag im Stellgliedtest ist, um eine Notrufauflösung beim Stellgliedtest zu verhindern";
CM_ SG_ 64 AB_Systemfehler "Systemfehler Ggf. wird Warnlampe dauernd eingeschaltet.";
CM_ SG_ 64 AB_Texte_AKS "Textanzeige für pyrotechnische Auslösung der aktiven Kopfstütze (AKS)";
CM_ SG_ 64 AB_VB_deaktiviert "Als Option vorgehalten, Beifahrerairbag wurden per Schlüsselschalter oder Insassenerkennung deaktiviert";
CM_ SG_ 64 AB_Versorgungsspannung "Übertragung der Plausibilitätsinformation Kl.15-Last vs. Kl.15-CAN.
Bedienung im Fall Kl.15-Last 'EIN' und Kl.15-CAN 'AUS' mit Ausgabe Warnung/Akustik im Kombi.";
CM_ SG_ 64 Airbag_01_CRC "Für MLB:
'Berechnung siehe Lastenheft 'Kommunikationsabsicherung für FlexRay und CAN''

Ab MQB und MLBevo:
'Berechnung siehe Lastenheft 'End-to-End Kommunikationsabsicherung''

Endwerte siehe Begleitdokument 'S-PDU Kennungsfolgen'";
CM_ SG_ 64 ASM_Masterzeit_02 "Masterzeit für alle ASM Sender";

CM_ SG_ 1312 AB_Abschaltanf_SIH_BF "Die Insassenerkennung auf der Beifahrerseite fordert bei Übertemperatur eine Abschaltung der Sitzheizung an. Die Übertemperatur kann bei niederohmigen Nebenschlüssen der Sitzheizungsmatte als Folge von zu hohem resultierenden Strom auftreten.";
CM_ SG_ 1312 AB_Anforderung_eCall "Trigger für Car2X Steuergerät das ein eCall Ereignis erkannt wurde.";
CM_ SG_ 1312 AB_Anforderung_USM "Trigger für Gateway (OBDC) und MIB/MMI, dass ein USM-Ereignis erkannt wurde.";
CM_ SG_ 1312 AB_Anprall_FGS "Uebermittlung der Lage einer Kollision, Fussgaengerschutz-Aktorik";
CM_ SG_ 1312 AB_Anprall_Front_Beifahrer "Uebermittlung der Lage einer Kollision, Anprallzone Front Beifahrerseite";
CM_ SG_ 1312 AB_Anprall_Front_Fahrer "Uebermittlung der Lage einer Kollision, Anprallzone Front Fahrerseite";
CM_ SG_ 1312 AB_Anprall_Heck_Beifahrer "Uebermittlung der Lage einer Kollision, Anprallzone Beifahrerseite hinten";
CM_ SG_ 1312 AB_Anprall_Heck_Fahrer "Uebermittlung der Lage einer Kollision, Anprallzone Fahrerseite hinten";
CM_ SG_ 1312 AB_Anprall_Rollover "Uebermittlung der Lage einer Kollision, Rollover erkannt";
CM_ SG_ 1312 AB_Anprall_Seite_Beifahrer "Uebermittlung der Lage einer Kollision, Anprallzone Beifahrerseite Seite";
CM_ SG_ 1312 AB_Anprall_Seite_Fahrer "Uebermittlung der Lage einer Kollision, Anprallzone Fahrerseite Seite";
CM_ SG_ 1312 AB_Belegung_VB "Belegungserkennung vorne Beifahrer. Wird in US-Steuergeräten über Bladder-Matte bedient, optional bei RdW, falls SBE_EuroNCAP entschieden wird.";
CM_ SG_ 1312 AB_Crashschwere "Übermittlung der Crashschwere an das Gateway (OBDC)";
CM_ SG_ 1312 AB_Gurtschloss_BF "Gurtschlossstatus Beifahrerseite";
CM_ SG_ 1312 AB_Gurtschloss_FA "Gurtschlosstatatus Fahrerseite";
CM_ SG_ 1312 AB_Gurtschloss_Reihe2_BF "Gurtschlossstatus 2. Reihe Beifahrerseite,  Mehrausstattung";
CM_ SG_ 1312 AB_Gurtschloss_Reihe2_FA "Gurtschlossstatus 2. Reihe Fahrerseite, Mehrausstattung";
CM_ SG_ 1312 AB_Gurtschloss_Reihe2_MI "Gurtschlossstatus 2. Reihe Mitte,  Mehrausstattung";
CM_ SG_ 1312 AB_Gurtschloss_Reihe3_BF "Gurtschlossstatus 3. Reihe Beifahrerseite,  Mehrausstattung";
CM_ SG_ 1312 AB_Gurtschloss_Reihe3_FA "Gurtschlossstatus 3. Reihe Fahrerseite,  Mehrausstattung";
CM_ SG_ 1312 AB_Gurtschloss_Reihe3_MI "Gurtschlossstatus 3. Reihe Mitte,  Mehrausstattung";
CM_ SG_ 1312 AB_Sitzpos_Sens_BF "Ausgabe Sitzposition Beifahrer";
CM_ SG_ 1312 AB_Sitzpos_Sens_FA "Ausgabe Sitzposition Fahrer";
CM_ SG_ 1312 AB_Wickelklappung_Reihe2_BF "Status Wickelklappung 2. Reihe Beifahrerseite, Mehrausstattung";
CM_ SG_ 1312 AB_Wickelklappung_Reihe2_FA "Status Wickelklappung 2. Reihe Fahrerseite, Mehrausstattung";
CM_ SG_ 1312 AB_Wickelklappung_Reihe2_MI "Status Wickelklappung 2. Reihe Mitte, Mehrausstattung";
CM_ SG_ 1312 Airbag_02_CRC "Für MLB:
'Berechnung siehe Lastenheft 'Kommunikationsabsicherung für FlexRay und CAN''

Ab MQB und MLBevo:
'Berechnung siehe Lastenheft 'End-to-End Kommunikationsabsicherung''

Endwerte siehe Begleitdokument 'S-PDU Kennungsfolgen'";
CM_ SG_ 1312 LoGeWa_Event_Kombiwarnung "Event für Kombiwarnung";
CM_ SG_ 1312 SC_PAO_OFF_Anf "Sollwert für LED 'OFF' in Anzeige Passenger Airbag On/Off";
CM_ SG_ 1312 SC_PAO_ON_Anf "Sollwert für LED 'ON' in Anzeige Passenger Airbag On/Off";
CM_ SG_ 1312 SC_PAO_Schriftzug_Anf "Sollwert für LED 'PASSENGER AIRBAG' in Anzeige Passenger Airbag On/Off";

CM_ SG_ 1349 AB_Anprall_Front "Uebermittlung der Lage einer Kollision, Anprallzone Front";
CM_ SG_ 1349 AB_Anprall_Heck "Uebermittlung der Lage einer Kollision, Anprallzone Heck";
CM_ SG_ 1349 AB_Belegung_VF_ext "Das Signal kommuniziert den Status des Sitzbelegsensors Fahrer incl. dauerhafter Zustände mit Signalqualität ASIL A.";
CM_ SG_ 1349 AB_Belegung_VF_ext_aktiv "Kennzeichnet aktive Funktion 'Erweiterte Sitzbelegdiagnose' für Signal AB_Belegung_VF_ext";
CM_ SG_ 1349 AB_Gurtwarn_Reihe2_BF "Status Gurtwarnung 2. Sitzreihe Beifahrerseite";
CM_ SG_ 1349 AB_Gurtwarn_Reihe2_FA "Status Gurtwarnung 2. Sitzreihe Fahrerseite";
CM_ SG_ 1349 AB_Gurtwarn_Reihe2_MI "Status Gurtwarnung 2. Sitzreihe Mitte";
CM_ SG_ 1349 AB_Gurtwarn_Reihe3_BF "Status Gurtwarnung 3. Sitzreihe Beifahrerseite";
CM_ SG_ 1349 AB_Gurtwarn_Reihe3_FA "Status Gurtwarnung 3. Sitzreihe Fahrerseite";
CM_ SG_ 1349 AB_Gurtwarn_Reihe3_MI "Status Gurtwarnung 3. Sitzreihe Mitte";
CM_ SG_ 1349 AB_Gurtwarn_Reihe4_BF "Status Gurtwarnung 4. Sitzreihe Beifahrerseite";
CM_ SG_ 1349 AB_Gurtwarn_Reihe4_FA "Status Gurtwarnung 4. Sitzreihe Fahrerseite";
CM_ SG_ 1349 AB_Gurtwarn_Reihe4_MI "Status Gurtwarnung 4. Sitzreihe Mitte";
CM_ SG_ 1349 AB_SBR_hinten_verbau "Verbauinformation Sitzbelegungssensor hinten (2. und 3. Sitzreihe)";
CM_ SG_ 1349 AbstWarn_MV_FAS_Fkt_Status "FAS-ProfileMaster Iststatus der Kundenfunktion";
CM_ SG_ 1349 Airbag_04_BZ "4bit Botschaftszähler, wird mit jeder Sendebotschaft inkrementiert";
CM_ SG_ 1349 Airbag_04_CRC "Für MLB:
Berechnung siehe Lastenheft 'Kommunikationsabsicherung für FlexRay und CAN'
Ab MQB und MLBevo:
Berechnung siehe Lastenheft 'End-to-End Kommunikationsabsicherung'

Endwerte siehe Begleitdokument 'S-PDU Kennungsfolgen'";
CM_ SG_ 1349 AWV_Einstellung_System_ASG "Signal zur Realisierung des BAP-Koordinators";
CM_ SG_ 1349 AWV_Einstellung_Warnung_ASG "Signal zur Realisierung des BAP-Koordinators";
CM_ SG_ 1349 LGI_FAS_Fkt_Status "FAS-ProfileMaster Iststatus der Kundenfunktion (LGI: Lokale Gefahreninformation)";
CM_ SG_ 1349 PreCrash_FAS_Fkt_Status "FAS-ProfileMaster Iststatus der Kundenfunktion";
CM_ SG_ 1349 SC_PreSense_Modus_System_KAS "BAP-Kommunikation zum Kreuzungsassistent";
CM_ SG_ 1349 SC_PreSense_Modus_System_MV "Signal zur Realisierung der BAP-Kommunikation für PreSense";
CM_ SG_ 1349 SC_PreSense_Modus_System_NV "Signal zur Realisierung der BAP-Kommunikation für PreSense";
CM_ SG_ 1349 SC_PreSense_Modus_Warnung_MV "Signal zur Realisierung der BAP-Kommunikation für PreSense";
CM_ SG_ 1349 SC_PreSense_Modus_Warnung_NV "Signal zur Realisierung der BAP-Kommunikation für PreSense";
CM_ SG_ 1349 WarnBrems_Charisma_FahrPr "Aktuell eingestelltes Fahrprogramm der Funktion Warn- und/oder Notbremsfunktion";
CM_ SG_ 1349 WarnBrems_Charisma_Status "Verfügbarkeit der Funktion Warn- und/oder Notbremsfunktion für die Ansteuerung durch den Charisma-Koordinator.";

CM_ SG_ 2536726528 BAP_ClimateDiag_ASG_01_Header "Climate-Diagnose Anzeigesteuergerät";

CM_ SG_ 2536726544 BAP_ClimateDiag_FSG_01_Header "Climate-Diagnose Funktionssteuergerät";

CM_ SG_ 2536702208 BAP_Klima1_ASG_01_Header "BAP_Klima1_ASG_01";

CM_ SG_ 2536702224 BAP_Klima1_FSG_01_Header "BAP-Klima1_FSG_01";

CM_ SG_ 2536702464 BAP_Klima2_ASG_01_Header "BAP_Klima2_ASG_01";

CM_ SG_ 2536702468 BAP_Klima2_ASG_05_Header "Klima2 Anzeigesteuergerät 5";

CM_ SG_ 2536718848 BAP_KlimaMaster_ASG_01_Header "KlimaMaster Anzeigesteuergeraet1";

CM_ SG_ 2536718849 BAP_KlimaMaster_ASG_02_Header "KlimaMaster Anzeigesteuergeraet2";

CM_ SG_ 2536718850 BAP_KlimaMaster_ASG_03_Header "KlimaMaster Anzeigesteuergeraet3";

CM_ SG_ 2536718851 BAP_KlimaMaster_ASG_04_Header "KlimaMaster Anzeigesteuergeraet4";

CM_ SG_ 2536718864 BAP_KlimaMaster_FSG_01_Header "KlimaMaster Funktionssteuergeraet";

CM_ SG_ 1626 APS_Tongeber_defekt "Status APS-Tongeber zur HMI-Ansteuerng der RCTA-Funktion";
CM_ SG_ 1626 BCM1_AFS_Lampe "Ansteuerung der AFS-Fehlermeldung im Kombi";
CM_ SG_ 1626 BCM1_EasyEntry_Status "Status EasyEntry für Lenksäule (wird auch von IVB verwendet)";
CM_ SG_ 1626 BCM1_Fahrlicht_Hinweis "Signal zum Kombi um den Hinweis 'Bitte Fahrlicht einschalten' anzufordern";
CM_ SG_ 1626 BCM1_Hinweis_Lichtnachlauf "Signal dient der Anzeige eines aktiven Lichtnachlaufes beim automatischen Abschalten der Klemme S und Klemme 15. Der Lichtnachlauf wird gestartet, wenn die Klemme 15 bei aktivem Fahrlicht deaktiviert wird.";
CM_ SG_ 1626 BCM1_Kl_15_HW_erkannt "Erkennung Klemme 15 (Hardware) vom BCM1
";
CM_ SG_ 1626 BCM1_Kl_15_Sig_HW_erkannt "Erkennung Klemme 15 Signal (Hardware) vom BCM1";
CM_ SG_ 1626 BCM1_LDS_Stellung "Das Signal wird vom AFS / LWR Steuergerät empfangen und dient der Verifizierung der Lichtdrehschalterstellung. Intelligente Lichtfunktionen wie dyn. KL und gleitende Leuchtweite (GLW) nur bei LDS = 'AUTO'.";
CM_ SG_ 1626 BCM1_Lenksaeule_aktiv "Lenksaeulenverstellung aktiv";
CM_ SG_ 1626 BCM1_Licht_Warn "Lichtwarnung";
CM_ SG_ 1626 BCM1_Lichtwarn_Texte "Anforderung von Lichtwarnungen vom BCM1 zum Kombi
MLB: nur Werte 0..2";
CM_ SG_ 1626 BCM1_MH_Schalter "Motorhaubenkontakt";
CM_ SG_ 1626 BCM1_MH_WIV_Schalter "Bewerteter Motorhaubenkontakt fuer WIV";
CM_ SG_ 1626 BCM1_NV_Taster "BCM1_NV_Taster gibt an, ob der NightVision-Taster im Lichtdrehschalter-Modul aktuell betaetigt wird.";
CM_ SG_ 1626 BCM1_Reisemodus_Texte "Ansteuerung der Reisemodus-Texte im Kombi";
CM_ SG_ 1626 BCM1_Rueckfahrlicht_Schalter "Rückfahrlichtschalter
ab MQB/ MLBevo: Die Ganginformation wird unentprellt übertragen, im AT-Getriebe wird evtl. kurzzeitig der R-Gang angezeigt. Eine Entprellung muß im Empfänger erfolgen (typisch 400ms).";
CM_ SG_ 1626 BCM1_Spannungs_Anf "Forderung des BCM1-SG's zur Spannungsanhebung.";
CM_ SG_ 1626 BCM1_Valet_Parking_Taster "Valet Parking Taster ";
CM_ SG_ 1626 BCM1_Warnblink_Taster "Warnblinktaster";
CM_ SG_ 1626 BCM_Anf_AAW_MoLaWa "Signal zur Anforderung der Antrieb-Aktiv-Warnung und Motorlaufwarnung. Die Berechnung erfolgt im BCM. Die Ausgabe der Warnungen wird vom Kombiinstrument realisiert";
CM_ SG_ 1626 BCM_Bremsbelag_Sensor "Sensorsignal der Stromschleife  für Bremsbelagverschleiß aktuell, entstört, unbewertet";
CM_ SG_ 1626 BCM_Bremsfluessigkeit_Sensor "Kontaktsignal des Sensorschalters für die Bremsflüssigkeitsreserve aktuell, entstört, unbewertet";
CM_ SG_ 1626 BCM_Charisma_Taste2 "Betätigung der Charisma-Taste 2";
CM_ SG_ 1626 BCM_Eco_Charisma_Taste "Betätigung Taster ECO alias BlueKey oder Charisma";
CM_ SG_ 1626 BCM_Handbremse_Hinweis "Infotext fuer das Kombiinstrument zur Oeffnung der elektr. Heckklappe.";
CM_ SG_ 1626 BCM_HBFS_EOE_aktiv "Elektrisch-Oeffnen-Motor aktiv";
CM_ SG_ 1626 BCM_HDF_betaetigt "Betätigung Taster für Heckdeckelfernentriegelung in Mittelkonsole";
CM_ SG_ 1626 BCM_HFS_EOE_aktiv "Elektrisch-Oeffnen-Motor aktiv";
CM_ SG_ 1626 BCM_Hybrid_StartStopp_Taste "Betaetigung Taster 'Hybrid' oder alternativ Taster 'Start/Stopp Deaktivierung', je nach Verbau";
CM_ SG_ 1626 BCM_Hybrid_StSt_Taste_Fehler "Fehlerflag, wenn Tasterdiagnose im BCM für den StSt-Taster anschlägt.";
CM_ SG_ 1626 BCM_Kuehlmittel_Sensor "Signal der Sensorelektroden für die Kühlmittelreserve aktuell, entstört, bewertet (OK/Mangel)";
CM_ SG_ 1626 BCM_Kuehlmittel_Sensor_02 "Signal der zweiten Sensorelektroden für die Kühlmittelreserve aktuell, entstört, bewertet (OK/Mangel)";
CM_ SG_ 1626 BCM_Offroad_Taste "Betätigung der Offroad-Taste";
CM_ SG_ 1626 BCM_ValetTaster_Fkts_LED "Im MQB beschreibt das Signal nur den Zustand der Funktion Valet Parking (aktiv/ inaktiv)
Im MLBevo wird über das Signal zusätzlich die ValetTaster_Fkts_LED (an/ aus) gesteuert";
CM_ SG_ 1626 BCM_Waehlhebel_P_Hinweis "Infotext NAR für die Vorbedingung 'Waehlhebel in P' für Öffnen der Heckklappe über den Fahrerrauminnentaster.";
CM_ SG_ 1626 BCM_Waschwasser_Sensor "Signal der Sensorelektroden für die Waschwasserreserve aktuell, entstört, bewertet (OK/Mangel)";
CM_ SG_ 1626 DWA_Alarmquelle "Signalisiert den Auslösegrund der DWA";
CM_ SG_ 1626 DWA_Einschraenkung "Signalisiert Fehler der DWA";
CM_ SG_ 1626 Gong_TFL_Umschaltung "Aktivierung / Deaktivierung des TFL per Affengriff wird mit einem Gong im Kombi quittiert.";
CM_ SG_ 1626 LRH_Taster "Tasterbetätigung Lenkradheizung";

CM_ SG_ 2527679637 BCM_anf_VLW "Über dieses Signal wird die vom BCM errechnete Verlassenswarnung sowie die Meldung eines aktiven Rollfaehigkeitsmodus zur Ausgabe durch das Kombinstrument angefordert.";
CM_ SG_ 2527679637 BCM_Defrost_Taste "Defrost AN/AUS und Status";
CM_ SG_ 2527679637 BCM_FAS_Taster "Betätigung des FAS-Tasters Schalterleiste.";
CM_ SG_ 2527679637 BCM_FSH_Taste "Frontscheibenheizung AN/AUS und Status";
CM_ SG_ 2527679637 BCM_HSH_Taste "Heckscheibenheizung AN/AUS und Status";
CM_ SG_ 2527679637 BCM_LTM_Allwetterl_Status "Allwetterlicht Status zur Anzeige im Allwetterlicht-PopUp";
CM_ SG_ 2527679637 BCM_LTM_Nebell_Status "Nebellicht Status zur Anzeige im Nebellicht-PopUp";
CM_ SG_ 2527679637 BCM_LTM_Nebelschluss_Status "Nebelschlusslicht Status zur Anzeige im Nebelschlusslicht-PopUp";
CM_ SG_ 2527679637 BCM_LTM_PopUp_Anf "Anforderung der entsprechenden Anzeige im Kombi bei Aussenlichtsteuerung über LTM (LichtTastenModul)";
CM_ SG_ 2527679637 BCM_LTM_PopUp_Inhalt "Definition Inhalt des PopUps zur Aussenlichtbedienung";
CM_ SG_ 2527679637 BCM_LTM_PopUp_Status "Auswahl der aktiven Aussenlichtfunktion im LTM PopUp";
CM_ SG_ 2527679637 BCM_LTM_PopUp_Texte "Anforderung Kombi-Texte bei Bedienung Aussenlicht über LTM (LichtTastenModul)";
CM_ SG_ 2527679637 CPD_Warnung "Ansteuerung einer Warnung im Kombi/ iID mit Ton oder ohne Ton durch die Fkt. ChildPresenceDetection";
CM_ SG_ 2527679637 LiSi_Touch_Event "Touch_Events für Informationen einer Funktionsauslösung auf der LiSi, welches dann für bspw. ein akustiches Signal zentral umgesetzt werden können.";
CM_ SG_ 2527679637 LTMs_01_alt "Veraltet-Bit für den LIN-Frame LTMs_01";
CM_ SG_ 2527679637 MiKo_Tisch_Positionswarnung "Positionswarnung des Tisches in der Mittelkonsole";

CM_ SG_ 2463978609 BCM_Relais_2_Batterie "Zeigt den Zustand des vom BCM bzw KFG angesteuerten Laderelais einer verbauten 2. Batterie an";
CM_ SG_ 2463978609 FA_Hoehenwert_HL_01 "Aktueller Höhenwert (Rohwerte) Hinten Links; ungefiltertes Signal
Einheit, Offset und Faktor sind abhänig von 'FA_Hoehenwert_kalibriert'";
CM_ SG_ 2463978609 FA_Hoehenwert_VL_01 "Aktueller Höhenwert (Rohwerte) Vorne Links; ungefiltertes Signal
Einheit, Offset und Faktor sind abhänig von 'FA_Hoehenwert_kalibriert'";
CM_ SG_ 2463978609 HSH_LED "LED Ansteuerung Heckscheibenheizung";
CM_ SG_ 2463978609 HSH_Status "Status Heckscheibenheizung
";
CM_ SG_ 2463978609 KRH_Stufe_LED_li "Statusmeldung Kopfraumheizung links";
CM_ SG_ 2463978609 KRH_Stufe_LED_re "Statusmeldung Kopfraumheizung rechts";
CM_ SG_ 2463978609 Niveausensor_HL_verbaut "Signal wird gesetzt, wenn Niveausensor_hinten codiert wird.";
CM_ SG_ 2463978609 Niveausensor_VL_verbaut "Signal wird gesetzt, wenn Niveausensor_vorne codiert wird.";
CM_ SG_ 2463978609 SIL_Stufe_LED_li "Statusmeldung Sitzlüftung links";
CM_ SG_ 2463978609 SIL_Stufe_LED_re "Statusmeldung Sitzlüftung rechts";

CM_ SG_ 1635 BEM_Anf_KL15_schalten "Abschaltempfehlung bzw. Verhinderung der automatischen Abschaltung Kl15 durch das BCM";
CM_ SG_ 1635 BEM_Batt_Ab "Batterieverbindungskontrolle:
0x0: Batterie am Bordnetz
0x1: Batterie ab erkannt";
CM_ SG_ 1635 BEM_Batteriediagnose "Anzeige von Textwarnungen";
CM_ SG_ 1635 BEM_DFM "Generatorauslastungsgrad, vom Generator über LIN an das Gateway gesandt. Das Motorsteuergerät regelt auf dieses Signal die PTC, das Energiemanagement im BSG/BCM kalkuliert die Bordnetzauslastung";
CM_ SG_ 1635 BEM_EMLIN_ungueltig "Energie-Lin - Signale sind ungültig vom Slave Batteriedatenmodul oder Generator
0 = Signale gültig
1 = Signale ungültig";
CM_ SG_ 1635 BEM_Generatordiagnose "Ansteuerung Generatorwarnleuchte im Kombi
";
CM_ SG_ 1635 BEM_HL_Kontingentierung "Leistungskontingente für Heizsysteme";
CM_ SG_ 1635 BEM_HL_Regelung_Status "Status Regelung Heizleistung
";
CM_ SG_ 1635 BEM_Ladezustand "Ladezustand der Niedervoltbatterie
";
CM_ SG_ 1635 BEM_MMI_Vorwarnung "Anzeige Vorwarnung MMI-Abschaltung (Initialisierungswert aus EEprom)
";
CM_ SG_ 1635 BEM_Red_Innengeblaese "Reduzierung Innengebläse
";
CM_ SG_ 1635 BEM_REK_aktiv "Rekuperationsfreigabe vom Energiemanagement
0x0 = keine Rekuperationsfreigabe
0x1 = Rekuperationsfreigabe";
CM_ SG_ 1635 BEM_STH_Einschaltverbot "Einschränkung Standheizung/-lüftung durch BEM: Setzt der BEM das Bit, dann darf die Standheizung nicht mehr einschalten
(Die Standheizung muss aber nicht abschalten, sondern darf weiterbrennen)
(Initialisierungswert aus EEprom)
";
CM_ SG_ 1635 BEM_STH_Zielzeit "Maximal mögliche Zeit für den Standheizungsbetrieb, um die Startfähigkeit nicht zu gefährden";
CM_ SG_ 1635 BEM_UBDM "Batteriespannung, gemessen vom Batteriedatenmodul";
CM_ SG_ 1635 BEM_UGenSoll "Sollspannungsvorgabe an den Generator, beinhaltet temperaturoptimierte Batterieladung und Rekuperation";
CM_ SG_ 1635 MIB_Stromsparmodus "Signal beschreibt die Aktivierung für den Stromsparmodus beim MIB.
Bei AUS (= 0) gibt es keine weitere Anforderung an die MIB-Komponenten.
Bei EIN (= 1) werden alle MIB Komponenten in einen Stromsparmodus versetzt.";
CM_ SG_ 1635 NVEM_Abschaltstufe "Abschaltstufe aus dem Ruheenergiemanagement
Maßnahmen des Empfängers werden im QLAH Ruhestrommanagement definiert";
CM_ SG_ 1635 NVEM_Anf_SD_schalten "Anforderung Nachlauf für den Steckdosenbetrieb
Initialisierungswert aus EEprom";
CM_ SG_ 1635 NVEM_Batterie_Service "Anforderung einer Batterie-Service - Anzeige / Anforderung an die Werkstatt über MOD";
CM_ SG_ 1635 NVEM_Freigabe_OnlineUpdate "Freigabe für Online-Update durch Energiemanagement";
CM_ SG_ 1635 NVEM_Freigabe_ORU4 "Bestätigung oder Ablehnung eines konkreten, angefragten Online Updates durch das Energiemanagements";
CM_ SG_ 1635 NVEM_Freigabe_ZusBatt_Laden "NVEM gibt die Freigabe zum Schließen des Laderelais im Ruhebetrieb (z.B. bei Verwendung eines Ladegerätes)";
CM_ SG_ 1635 NVEM_Verbraucherabsch_Anz "Information über eine Verbraucherbschaltung durch das Energiemanagement";

CM_ SG_ 1163 BEM_06_BZ "4bit Botschaftszähler, wird mit jeder Sendebotschaft inkrementiert";
CM_ SG_ 1163 BEM_06_CRC "Für MLB:
Berechnung siehe Lastenheft 'Kommunikationsabsicherung für FlexRay und CAN'
Ab MQB und MLBevo:
Berechnung siehe Lastenheft 'End-to-End Kommunikationsabsicherung'

Endwerte siehe Begleitdokument 'S-PDU Kennungsfolgen'";
CM_ SG_ 1163 HLR_PTC_linear_Freigabe "Freigabe des EEM für den linearen PTC-Zuheizer";
CM_ SG_ 1163 NVEM2_Status_FuSiFahrt "Status sicherheitsrelevante Diagnosen NVEM";
CM_ SG_ 1163 NVEM2_Typ_EnergieNetz "Identifizierte NV-Energiearchitektur";
CM_ SG_ 1163 NVEM_Betriebsart "Betriebsart des Niedervolt - Energiemanagements";
CM_ SG_ 1163 NVEM_Bordnetzdiagnose "Wird vom NVEM im NV-Netz ein Bordnetz-Fehler erkannt, so soll dies zu einer mehrstufigen Anzeige führen.";
CM_ SG_ 1163 NVEM_Energie_Klima_Vorgabe "NVEM-Energievorgabe für Klima-Vorkonditionierung";
CM_ SG_ 1163 NVEM_Energienetz_Status "NVEM kommuniziert abgesichert den Zustand des Energienetzes.";
CM_ SG_ 1163 NVEM_Ladezustand "Ladezustand des NV-Hauptspeichers.";
CM_ SG_ 1163 NVEM_Last_Anf "Das NVEM fordert für die Batteriediagnose einen Lastimpuls vom Fahrzeug an, der durch kontrollierte Verbraucherzuschaltungen (z. B. Aktivierung Heckscheibenheizung) generiert wird";
CM_ SG_ 1163 NVEM_PTC_Sollstufe "Vorgabe des BEM an das BCM zur Aktivierung der geforderten PTC - Stufe.
Das MSG kopiert dies auf das Signal MO_PTC_Status";
CM_ SG_ 1163 NVEM_Red_KomfortVerbrauch "Master - SubMaster Kommunikation";
CM_ SG_ 1163 NVEM_STH_ZielzeitLang "Energetisch erlaubte Betriebszeit im Zielzeitkonzept für Standheizungen mit 2 Stunden Laufzeit";
CM_ SG_ 1163 NVEM_Vorgabe_Leistungsstufe "Ermittelte Leistungsstufe der Energiequelle";

CM_ SG_ 2463978850 BEM_07_BZ "4bit Botschaftszähler, wird mit jeder Sendebotschaft inkrementiert";
CM_ SG_ 2463978850 BEM_07_CRC "Für MLB:
Berechnung siehe Lastenheft 'Kommunikationsabsicherung für FlexRay und CAN'
Ab MQB und MLBevo:
Berechnung siehe Lastenheft 'End-to-End Kommunikationsabsicherung'

Endwerte siehe Begleitdokument 'S-PDU Kennungsfolgen'";
CM_ SG_ 2463978850 NVEM2_VerbrZustandsAnf "Dieses Signal soll bei FuSi-relevanten Energienotsituationen die Reaktion bei den Nichtdynamischen Verbrauchern auslösen.";
CM_ SG_ 2463978850 NVEM3_Absch_SCR "Abschaltung der SCR-Heizung durch das NVEM bei energetisch kritischen Zuständen.";
CM_ SG_ 2463978850 NVEM_Batt_Temp_Hinweis "Anforderung Kühlungsunterstützung der NV - Batterie";
CM_ SG_ 2463978850 NVEM_Bordnetz_Information "Informationsanzeigen zum 12V - Bordnetz";
CM_ SG_ 2463978850 NVEM_NVStuetzungAnf "Aktivierung / Deaktivierung Primärenergieversorger";
CM_ SG_ 2463978850 NVEM_Verbraucher_Information "Mit diesem Signal löst Das NVM eine Anzeige bzgl. einer bevorstehenden oder erfolgten Verbraucherabschaltung aus";

CM_ SG_ 1442 BMS_04_CRC "Für MLB:
'Berechnung siehe Lastenheft 'Kommunikationsabsicherung für FlexRay und CAN''

Ab MQB und MLBevo:
'Berechnung siehe Lastenheft 'End-to-End Kommunikationsabsicherung''

Endwerte siehe Begleitdokument 'S-PDU Kennungsfolgen'";
CM_ SG_ 1442 BMS_Fehler_Pilot "Signalisiert den Status der Pilotlinie BMS.";
CM_ SG_ 1442 BMS_Fehlerlampe_Anf "Anforderung der roten Hybrid-Warnlampe im Kombi";
CM_ SG_ 1442 BMS_Fehlerstatus "aktueller Fehlerstatus der Batterie";
CM_ SG_ 1442 BMS_Kapazitaet_02 "Nutzbare Kapazität der Batterie,
oder alterungsabhängige absolute Gesamtkapazität der Batterie.

Projektabhängig kann die Kapazität auf das nutzbare SOC-Fenster (zwischen oberer und unterer SOC-Grenze) bezogen sein, wobei sich dieses SOC-Fenster alteru";
CM_ SG_ 1442 BMS_Kl30c_Status "Stecker-Zustand des Service-Disconnect (Klemme 30c)";
CM_ SG_ 1442 BMS_OBD_Lampe_Anf "Anforderung MIL (MalfunctionIndicationLamp) von BMS (Motorsteuergerät reicht diese Info an Kombi weiter).";
CM_ SG_ 1442 BMS_Status_ServiceDisconnect "Status des Service Disconnect, ob dieser gesteckt oder gezogen ist.
Abhängigkeiten zu anderen Signalen: BMS_Fehler_Sicherung und BMS_Fehler_Pilot";
CM_ SG_ 1442 BMS_Status_Spgfreiheit "0=Init (ohne Funktion)
1=BMS Zwischenkreis spannungsfrei (U_Zwkr < 20V)
2=BMS Zwischenkreis nicht spannungsfrei (U_Zwkr >/= 25V, Hysterese)
3=Fehler (z.B. Fehler in der Sensorik)";
CM_ SG_ 1442 BMS_Warnlampe_Anf "Anforderung der gelben Hybrid-Warnlampe im Kombi";

CM_ SG_ 1450 SOK_BMS_04_Signatur "Signatur im Rahmen der durch SOK geschützen Broadcast-Kommunikation

Geschützte Funktion: OBD-Malfunction Indicator Light (MIL)
Geschützte PDU: BMS_04";

CM_ SG_ 687 BMC_Spannung "actual voltage of the battery / Momentanwert: Batteriespannung";
CM_ SG_ 687 BMS_As_Entladezaehler "Signal zur Berechnung des Lastprofils durch die RWB";
CM_ SG_ 687 BMS_As_Entladezaehler_Ueberlauf "Wird beim ersten Überlauf von BMS_As_Entladezahler auf 1 gesetzt. Reset über KL15-Wechsel";
CM_ SG_ 687 BMS_Rekuperation "Zähler: Anzeigesignal: Energiezufuhr in die HV-Batterie (Reku). Darf nicht durch Laden der Batterie bedatet werden";
CM_ SG_ 687 BMS_Rekuperation_Ueberlauf "Rekuperationleistungssignal BMS_Rekuperation mindest 1x übergelaufen";
CM_ SG_ 687 BMS_Verbrauch "Zähler: Energieentnahme aus der HV-Batterie";
CM_ SG_ 687 BMS_Verbrauch_Ueberlauf "Verbrauchssignal mindest 1x übergelaufen";

CM_ SG_ 1482 BMS_07_CRC "Für MLB:
'Berechnung siehe Lastenheft 'Kommunikationsabsicherung für FlexRay und CAN''

Ab MQB und MLBevo:
'Berechnung siehe Lastenheft 'End-to-End Kommunikationsabsicherung''

Endwerte siehe Begleitdokument 'S-PDU Kennungsfolgen'";
CM_ SG_ 1482 BMS_Ausgleichsladung_Anf "BMS wünscht eine Ausgleichsladung
Flag derzeit ungenutzt, da BalancingModus im Detail noch nicht geklärt.";
CM_ SG_ 1482 BMS_Balancing_Aktiv "Signal zeigt an, ob mindestens eine Zelle der HV Batterie balanciert wird";
CM_ SG_ 1482 BMS_Batteriediagnose "Anzeige von Textwarnungen";
CM_ SG_ 1482 BMS_Energieinhalt "aktuell nutzbarer Energieinhalt der HV-Batterie
(bezogen auf ein definiertes mittleres Belastungsprofil)";
CM_ SG_ 1482 BMS_Gesamtst_Spgfreiheit "0 = Funktion nicht aktiviert
1 = HV-System spannungsfrei (U_Zwkr von BMS, LE und Ladegerät < 20V, DCLadestecker nicht gesteckt und Service Disconnect entriegelt)
2 = HV-System nicht spannungsfrei (U_Zwkr von BMS, LE und Ladegerät >= 20V, Ladestecker ges";
CM_ SG_ 1482 BMS_KundenWarnung "Kundenwarnung und Ersatzreaktionen aufgrund von Batteriebrandgefahr";
CM_ SG_ 1482 BMS_Ladevorgang_aktiv "Signalisiert aktiven Ladevorgang, Ladegerät und DC/DC aktiv.
Signal bleibt nach Kl.15 ein aktiv, bis ESP_Stillstandsflag gelöscht.

Abhängigkeit zu BMS_Energieinhalt";
CM_ SG_ 1482 BMS_MaxEnergieinhalt "maximaler nutzbarer Energieinhalt der HV-Batterie (bezogen auf Last KBI_RWDS_Lastprofil bei SOC=100%)
Abhängig von KBI_RWDS_Lastprofil";
CM_ SG_ 1482 BMS_RIso_Ext "Minimum des Isolationswiderstands zwischen Batteriegehäuse und HV+ bzw. Batteriegehäuse und HV- bei geschlossenen Schützen (externe Iso Messung)";

CM_ SG_ 2527679654 BMS_11_BZ "4bit Botschaftszähler, wird mit jeder Sendebotschaft inkrementiert";
CM_ SG_ 2527679654 BMS_11_CRC "Für MLB:
Berechnung siehe Lastenheft 'Kommunikationsabsicherung für FlexRay und CAN'
Ab MQB und MLBevo:
Berechnung siehe Lastenheft 'End-to-End Kommunikationsabsicherung'

Endwerte siehe Begleitdokument 'S-PDU Kennungsfolgen'";
CM_ SG_ 2527679654 BMS_IsoFehler "Ergebnis der Isolationsmessung des BMS";
CM_ SG_ 2527679654 BMS_IsoZustand "Ergebnis des aktuellen/letzten Isolations-Meßzyklus: Messung läuft; Messung Batterie-intern oder Gesamtsystem; gemessener Wert unterschreitet Schwelle 1 / Schwelle 2.";
CM_ SG_ 2527679654 BMS_IstTemperatur_hoechste "aktuell höchste Temperatur in der Batterie";
CM_ SG_ 2527679654 BMS_IstTemperatur_niedrigste "aktuell niedrigsteTemperatur in der Batterie";
CM_ SG_ 2527679654 BMS_IstZellspannung_hoechste "höchster Wert aller Zellspannungen im BMS";
CM_ SG_ 2527679654 BMS_IstZellspannung_niedrigste "niedrigster Wert aller Zellspannungen im BMS";

CM_ SG_ 207 BMS_20_BZ "4bit Botschaftszähler, wird mit jeder Sendebotschaft inkrementiert";
CM_ SG_ 207 BMS_20_CRC "Für MLB:
Berechnung siehe Lastenheft 'Kommunikationsabsicherung für FlexRay und CAN'
Ab MQB und MLBevo:
Berechnung siehe Lastenheft 'End-to-End Kommunikationsabsicherung'

Endwerte siehe Begleitdokument 'S-PDU Kennungsfolgen'";
CM_ SG_ 207 BMS_ErwGrenzen_aktiv "die aktuellen Stromgrenzen der HV-Batterie sind zum Start des Verbrennungsmotors aufgeweitet / Bestätigung der Anforderung";
CM_ SG_ 207 BMS_Fehler_HVBattAbschaltung "Fehler: Fehlerzustand, erfordert das Öffnen der Batterieschütze
interner Batteriefehler, Batterieschütze ohne Vorankündigung durch das BMS geöffnet";
CM_ SG_ 207 BMS_Fehler_HVBattAbschaltung_Anf "Fehler: Fehlerzustand, erfordert das Öffnen der Batterieschütze
interner Batteriefehler; Vorankündigung eines bevorstehenden Öffnens der Batterieschütze durch das BMS";
CM_ SG_ 207 BMS_Fehler_Leistungsred "Fehler: Leistungsfähigkeit der Batterie ist eingeschränkt (z.B. aufgrund des Ausfalls von Sensoren oder des Lüfters)";
CM_ SG_ 207 BMS_Fehler_Notabschaltung_Crash "Fehler: Sicherheitskritischer Fehler (Crash-Erkennung)
Batterieschütze sind bereits geöffnet / werden sofort geöffnet
Signal wird direkt vom EMS gelesen und initiiert einen AKS des PWR und eine aktive Entladung des Zwischenkreises";
CM_ SG_ 207 BMS_Fehlerstatus_HV_Schuetze "Fehlerstatus der HV-Schütze, Verschweißt-Erkennung";
CM_ SG_ 207 BMS_HVIL_Status "Signalstatus HVIL/Pilotlinie";
CM_ SG_ 207 BMS_IstModus "Aktueller Betriebsmodus der Batterie
0: Standby; Schuetze geoeffnet; Kommunikation aktiv
1: Hauptschuetze geschlossen / HV-Netz aktiviert / normaler Fahrbetrieb
2: projektabhaengig belegt (z.B. Balancing, erweitertes DC-Schnelladen)
3: externes Laden ";
CM_ SG_ 207 BMS_Spannung "Aktuelle Spannung der Batterie.
Innerhalb der Batterie an den Zellmodulen gemessen, also _vor_ den Schützen und der Sicherung.";
CM_ SG_ 207 BMS_Spannung_Zwischenkreis "Aktuelle Spannung an den Batterie-HV-Anschlüssen; Abgang der Batterie zum Zwischenkreis / HV-Bordnetz / zur Leistungselektronik.";
CM_ SG_ 207 BMS_Strom "Aktueller Strom der Batterie.
Stromrichtung: Ladestrom wird mit positiven, Entladestrom mit negativen Werten angegeben.";

CM_ SG_ 2463978704 BMS_Max_Entladeleistung "Maximale Leistung, mit der die Batterie momentan belastet werden darf. 
Kurze Überschwinger aufgrund dynamischen Verhalten des Reglers sind nach Absprache möglich, aber
hierbei muss unbedingt auch der maximale Entladestrom berücksichtigt werden.";
CM_ SG_ 2463978704 BMS_Max_Entladestrom "Zwingend einzuhaltender Grenzwert für den Entladestrom der Batterie.
Darf aus Bauteilschutzgründen nicht überschritten werden.
Aus Lebensdauersicht muss zusätzlich die Leistungsgrenze eingehalten werden.";
CM_ SG_ 2463978704 BMS_Max_Ladeleistung "Maximale Leistung, mit der die Batterie aktuell geladen werden darf. 
Kurze Überschwinger aufgrund dynamischen Verhalten des Reglers sind nach Absprache möglich, aber
hierbei muss unbedingt auch der maximale Ladestrom berücksichtigt werden.";
CM_ SG_ 2463978704 BMS_Max_Ladestrom "Zwingend einzuhaltender Grenzwert für den Ladestrom der Batterie.
Darf aus Bauteilschutzgründen nicht überschritten werden.
Aus Lebensdauersicht muss zusätzlich die Leistungs- und SOC-Grenze eingehalten werden.";

CM_ SG_ 2463978705 BMS_22_BZ "4bit Botschaftszähler, wird mit jeder Sendebotschaft inkrementiert";
CM_ SG_ 2463978705 BMS_22_CRC "Für MLB:
Berechnung siehe Lastenheft 'Kommunikationsabsicherung für FlexRay und CAN'
Ab MQB und MLBevo:
Berechnung siehe Lastenheft 'End-to-End Kommunikationsabsicherung'

Endwerte siehe Begleitdokument 'S-PDU Kennungsfolgen'";
CM_ SG_ 2463978705 BMS_Ladezustand "Aktueller Ladezustand (SOC) der Batterie. 
Es handelt sich NICHT um den dem Fahrer angezeigten Füllstand der Batterie, sondern um den technisch ermittelten, batterie-internen Ladezustand, bezogen auf die Brutto-Kapazität der Batterie.";
CM_ SG_ 2463978705 BMS_Nutzbare_EntladeEnergie "Aktuelle, verbleibende Energiemenge, die noch aus der Batterie entladen werden kann.
Diese hängt in erster Linie vom aktuellen Ladezustand der Batterie ab.

Projektabhängig kann die Energiemenge noch vom variablen SOC-Fenster, dem Alterungszustand, dem";
CM_ SG_ 2463978705 BMS_PerfInd_Entladen "Leistungsindikation in Entladerichtung.
Der Bereich 100...200% beschreibt die verbleibende Reserve, bis ein Derating der maximalen Entladeleistungsgrenze eintritt.
Werte von 0 bis 100% beschreiben, auf welchen Teil der potentiell möglichen maximalen Ent";
CM_ SG_ 2463978705 BMS_PerfInd_Laden "Leistungsindikation in Laderichtung.
Der Bereich 100...200% beschreibt die verbleibende Reserve, bis ein Derating der maximalen Ladeleistungsgrenze eintritt.
Werte von 0 bis 100% beschreiben, auf welchen Teil der potentiell möglichen maximalen Ladeleist";
CM_ SG_ 2463978705 BMS_Status_EoHVL_Heizer "Status Erkennung offener HV-Leitung (EoHVL) / offene Steckverbindung zum HV-Batterieheizer (PTC):
0=Init
1=Keine offene HV-Leitung erkannt
2=offene HV-Leitung erkannt
3=Fehler";
CM_ SG_ 2463978705 BMS_Warnung_Stuetzung_NV "Warnung an das Energiemanagement zur Verfügbarkeit der sicherheitsrelevanten NV-Stützung.

Bei Stuetzung_iO kann die HV-Batterie zum aktuellen Zeitpunkt für die vorgegebene Dauer die notwendige Leistung/Energie zur Stützung des NV-Systems zur Verfügung ";

CM_ SG_ 2589283664 BMS_Balancing_Aktiv "Signal zeigt an, ob mindestens eine Zelle der HV Batterie balanciert wird";
CM_ SG_ 2589283664 BMS_Ladevorgang_aktiv "Signalisiert aktiven Ladevorgang, Ladegerät und DC/DC aktiv.
Signal bleibt nach Kl.15 ein aktiv, bis ESP_Stillstandsflag gelöscht.

Abhängigkeit zu BMS_Energieinhalt";
CM_ SG_ 2589283664 BMS_Max_Energie "Nutzbarer maximaler Entlade-Energieinhalt der vollgeladenen Batterie. 

Projektabhängig kann der Energiewert vom variablen SOC-Fenster (zwischen oberer und unterer SOC-Grenze), dem Alterungszustand, dem aktuellen Lastprofil sowie der Temperatur abhängen";
CM_ SG_ 2589283664 BMS_Max_Ladezustand "Obere Ladezustandsgrenze für das SOC-Fenster in der Betriebsstrategie. 
Der Wert kann sich über Lebensdauer und Alterung des Batteriesystems ändern; 
Erreicht der Wert 'BMS_Ladezustand' den hier übertragenen Wert, darf die Batterie nicht weiter geladen ";
CM_ SG_ 2589283664 BMS_Min_Ladezustand "Untere Ladezustandsgrenze für das SOC-Fenster in der Betriebsstrategie. 
Der Wert kann sich über Lebensdauer und Alterung des Batteriesystems ändern; 
Erreicht der Wert 'BMS_Ladezustand' nach unten hin den hier übertragenen Wert, darf die Batterie nicht";
CM_ SG_ 2589283664 BMS_RIso_Ext "Minimum des Isolationswiderstands zwischen Batteriegehäuse und HV+ bzw. Batteriegehäuse und HV- bei geschlossenen Schützen (externe Iso Messung)";

CM_ SG_ 2589283665 BMS_BattHeizung_VerbautStatus "Verbausignalisierung der optionalen HV-Batterieheizung";
CM_ SG_ 2589283665 BMS_Fehler_NTKreis "Fehler im NTKreis, HV-Batterie wird nicht klimatisiert
(Fehler, Fehlerfrei) ";
CM_ SG_ 2589283665 BMS_Pumpe1_Ansteuerung "Ansteuerung der Batterie-Kühlmittelpumpe.
0% = Pumpe abgeschaltet
100% = Pumpe maximal angesteuert";
CM_ SG_ 2589283665 BMS_Pumpe2_Ansteuerung "Ansteuerung einer zweiten Kühlmittelpumpe.
Projektabhängig für Systeme, die seitens Batterie zwei Pumpen ansteuern.
0% = Pumpe abgeschaltet
100% = Pumpe maximal angesteuert";
CM_ SG_ 2589283665 BMS_RuecklaufTemperatur "Aktueller Messwert der Kühlmittel-Rücklauftemperatur
am Kühlmittel-Auslass des Batteriesystems.";
CM_ SG_ 2589283665 BMS_SollVorlauftemperatur "Soll_Vorlauftemperatur_Kühlmedium in °C";
CM_ SG_ 2589283665 BMS_Status_Ventil1 "Status Ventil; wassergekühltes Batteriesystem.
Batteriekreis-Absperrventil.

nicht-angesteuert = Batterie im kleinen Kühlkreislauf, abgetrennt vom restlichen Kühlsystem
angesteuert = Batterie eingeschleift in großen Kühlkreislauf (Niedertemperatur-Küh";
CM_ SG_ 2589283665 BMS_Status_Ventil2 "Status des zweiten Ventils; wassergekühltes Batteriesystem.
Für Systeme, wo die Batterie ein zweites Ventil ansteuert.
Belegung projektabhängig.

nicht-angesteuert = großer Kühlkreislauf (Niedertemperatur-Kühlkreis) abgetrennt vom Batteriesystem oder ";
CM_ SG_ 2589283665 BMS_Temperatur "battery temperature / Momentanwert: Temperatur der Traktionsbatterie";
CM_ SG_ 2589283665 BMS_Temperierung_Anf "Temperierungsbedarf der HV-Batterie";
CM_ SG_ 2589283665 BMS_VorlaufTemperatur "Aktueller Messwert der Kühlmittel-Vorlauftemperatur
am Kühlmittel-Einlass des Batteriesystems.";

CM_ SG_ 2589283760 BMS_Dauer_Entladeleistung "ist die aktuelle Dauer-Leistungsfähigkeit der Batterie. 
Wenn dieser Wert überschritten wird, kann ein zeitliches Derating der maximalen Leistungsgrenzen stattfindet. Die Dauerleistung ändert sich mit Batterietemperatur und Ladezustand.";
CM_ SG_ 2589283760 BMS_Dauer_Ladeleistung "ist die aktuelle Dauer-Leistungsfähigkeit der Batterie. 
Wenn dieser Wert überschritten wird, kann ein zeitliches Derating der maximalen Leistungsgrenzen stattfindet. Die Dauerleistung ändert sich mit Batterietemperatur und Ladezustand.";
CM_ SG_ 2589283760 BMS_Max_Spannung "Maximal erlaubte Batteriespannung, zwingend einzuhaltender Grenzwert";
CM_ SG_ 2589283760 BMS_Min_Spannung "Minimal erlaubte Batteriespannung, zwingend einzuhaltender Grenzwert";

CM_ SG_ 2589283762 BMS_eTM_KonditionierWunsch "Über dieses Signal teilt die HV-Batterie mit, daß sie gerne über den NT-Kreis gekühlt oder geheizt werden möchte. Die potentielle Umsetzbarkeit dieses Konditionierungswunsches muß über ein CAN-Signal von der Antriebssteuerung bestätigt werden, bevor die H";
CM_ SG_ 2589283762 BMS_PerfInd_EntladenPeak_Temp "Peformanceindikator für temperaturabhängige Leistungsreduzierung beim Entladen 
(bezogen auf Peakleistung entsprechend des SOCs bei Wohlfühltemperatur)";
CM_ SG_ 2589283762 BMS_PerfInd_LadenPeak_Temp "Peformanceindikator für temperaturabhängige Leistungsreduzierung beim Laden 
(bezogen auf Peakleistung entsprechend des SOCs bei Wohlfühltemperatur)";
CM_ SG_ 2589283762 BMS_SollVolumenstrom "Soll Volumenstrom für Kühlkreislauf Batterie";
CM_ SG_ 2589283762 BMS_TempStatus_Entladen "Signalisiert den Temperaturzustand der Batterie aufgrund dessen eine evt. Leistungseinschränkung beim Entladen besteht.";
CM_ SG_ 2589283762 BMS_TempStatus_Laden "Signalisiert den Temperaturzustand der Batterie aufgrund dessen eine evt. Leistungseinschränkung beim Laden besteht.";
CM_ SG_ 2589283762 BMS_TMA_Betriebsart "Interne Betriebsart des Batterie-Thermomanagements.
0 = Klimatisierung abgeschaltet
1 = für 'normalen' Fahrbetrieb aktiv
2 = Vorkonditionierung auf Schnelladung während Fahrt
3 = reduzierte Klimatisierung im AC-Laden
4 = maximale Klimatisierung im DC";
CM_ SG_ 2589283762 BMS_TMA_Kuehlkreis_Status "HVBat meldet den seitens Batterie gerade aktiven Zustand des Kühlkreises/Kühlsystems.
0 = Batterieklimatisierung abgeschaltet, Pumpe abgeschaltet. Ventilstellung im 2-Kreis-Betrieb, so daß NT-Kreis weiterhin betrieben werden kann.
1 = Umwälzbetrieb, the";

CM_ SG_ 2331595856 BMS_DC_Ladeschuetze_Ist "Status der DC-Ladeschütze der HV-Batterie";
CM_ SG_ 2331595856 BMS_EnergieVorhalt "Energievorhalt der Batterie (z.B. als Alterungsreserve), welcher nicht in der aktuellen Betriebsstrategie verwendet werden kann, aber zur Kompensation der Alterung genutzt werden kann.";
CM_ SG_ 2331595856 BMS_Hauptschuetze_Ist "Status der Hauptschütze der HV-Batterie";
CM_ SG_ 2331595856 BMS_Last_Chg_adeq_SOCswing_Day "Zeitpunkt (Tag) des letzten, für die UBE_Indikator-Berechnung adäquaten  Ladehubs (aktuelle Forderung: >50% SOC)";
CM_ SG_ 2331595856 BMS_Last_Chg_adeq_SOCswing_Month "Zeitpunkt (Monat) des letzten, für die UBE_Indikator-Berechnung adäquaten  Ladehubs (aktuelle Forderung: >50% SOC)";
CM_ SG_ 2331595856 BMS_Last_Chg_adeq_SOCswing_Year "Zeitpunkt (Jahr) des letzten, für die UBE_Indikator-Berechnung adäquaten  Ladehubs (aktuelle Forderung: >50% SOC)";
CM_ SG_ 2331595856 BMS_Max_UBE "BMS_UBE bei BMS_Ladezustand = BMS_Max_Ladezustand. Das Verhältnis BMS_UBE/BMS_UBE_Max ergibt den energetischen Kunden-SOC (ohne Berücksichtigung eventueller Anzeigereserven)";
CM_ SG_ 2331595856 BMS_Nennspannung "Nennspannung der HV Batterie (Nennspannung der Zelle nach PV8450 multipliziert mal Anzahl in Serie geschalteter Zellen)";
CM_ SG_ 2331595856 BMS_Range_Indikator "Der Range-Indikator gibt das Verhältnis der aktuellen maximalen Reichweite zur maximalen Reichweite eines Neufahrzeugs wieder. Da die Reichweite primär von der UBE abhängt, wird dieser Wert im BMS berechnet.";
CM_ SG_ 2331595856 BMS_UBE "„Usable Battery Energy“ = Nutzbare Entladeenergie der HV Batterie vom aktuellen Ladezustand bis zum Ende des elektrischen Fahrens unter Annahme von Homologationsbedingungen (Lastprofil, Temperatur). Ein negativer Wert bedeutet, dass der aktuelle Ladezusta";
CM_ SG_ 2331595856 BMS_UBE_Indik_last_update_km "Strecke seit letzter Aktualisierung des UBE-Indikators. Ausgabe in der Einheit [km]";
CM_ SG_ 2331595856 BMS_UBE_Indikator "Der UBE Indikator gibt das Verhältnis der aktuellen maximalen UBE (BMS_Max_UBE) zur maximalen UBE einer neuen HV Batterie wieder.";
CM_ SG_ 2331595856 BMS_UBE_T "Gleiche Bedeutung wie das Signal BMS_UBE unter Berücksichtigung der aktuellen Batterietemperatur. Eine Temperaturänderung wird nicht angenommen.
Dieses Signal kann zum Beispiel verwendet werden, um eine Restenergie der HV Batterie zu berechnen.";
CM_ SG_ 2331595856 SOK_BMS_34_Signatur "Signatur im Rahmen der durch SOK geschützen Broadcast-Kommunikation

Geschützte Funktion: UBE-Indikator
Geschützte PDU: BMS_34";

BA_DEF_  "DBName" STRING;
BA_DEF_  "GenNWMApBusSleep" STRING;
BA_DEF_  "GenNWMApCanNormal" STRING;
BA_DEF_  "GenNWMApCanOff" STRING;
BA_DEF_  "GenNWMApCanOn" STRING;
BA_DEF_  "GenNWMApCanSleep" STRING;
BA_DEF_  "GenNWMApCanWakeUp" STRING;
BA_DEF_  "GenNWMGotoMode_Awake" STRING;
BA_DEF_  "GenNWMGotoMode_BusSleep" STRING;
BA_DEF_  "GenNWMSleepTime" INT 0 1000000;
BA_DEF_  "GenNWMTalkNM" STRING;
BA_DEF_  "Manufacturer" STRING;
BA_DEF_  "NmhBaseAddress" HEX 0 536870911;
BA_DEF_  "NmhMessageCount" INT 0 1024;
BA_DEF_  "NmType" STRING;
BA_DEF_  "VAGTP20_SetupMessageCount" INT 0 255;
BA_DEF_  "VAGTP20_SetupStartAddress" HEX 0 2047;
BA_DEF_  "VersionDay" INT 1 31;
BA_DEF_  "VersionMonth" INT 1 12;
BA_DEF_  "VersionWeek" INT 1 52;
BA_DEF_  "VersionYear" INT 0 99;
BA_DEF_  "VersionNumber" INT 0 65535;
BA_DEF_  "BusType" STRING;
BA_DEF_  "Baudrate" INT 1 1000000;
BA_DEF_  "BaudrateCANFD" INT 1 16000000;
BA_DEF_  "NmhTimeoutTimer" INT 0 65535;
BA_DEF_  "NmhWaitBusSleepTimer" INT 0 65535;
BA_DEF_  "NmhPrepareBusSleepTimer" INT 0 65535;
BA_DEF_  "NmhLongTimer" INT 0 65535;
BA_DEF_  "NmhNStart" INT 0 255;
BA_DEF_ BU_  "GenNodAutoGenDsp" ENUM "No", "Yes";
BA_DEF_ BU_  "GenNodAutoGenSnd" ENUM "No", "Yes";
BA_DEF_ BU_  "GenNodSleepTime" INT 0 1000000;
BA_DEF_ BU_  "ILUsed" ENUM "No", "Yes";
BA_DEF_ BU_  "ECUVariantDefault" ENUM "No", "Yes";
BA_DEF_ BU_  "ECUVariantGroup" STRING;
BA_DEF_ BU_  "NodeLayerModules" STRING;
BA_DEF_ BU_  "NmhNode" ENUM "No", "Yes";
BA_DEF_ BU_  "NmNode" ENUM "No", "Yes";
BA_DEF_ BU_  "SamplePointMin" FLOAT 50.0 99.9;
BA_DEF_ BU_  "SamplePointMax" FLOAT 50.0 99.9;
BA_DEF_ BU_  "SyncJumpWidthMin" FLOAT 0.0 50.0;
BA_DEF_ BU_  "SyncJumpWidthMax" FLOAT 0.0 50.0;
BA_DEF_ BU_  "SyncJumpWidthCANFDMin" FLOAT 0.0 50.0;
BA_DEF_ BU_  "SyncJumpWidthCANFDMax" FLOAT 0.0 50.0;
BA_DEF_ BU_  "SamplePointCANFDMin" FLOAT 50.0 99.9;
BA_DEF_ BU_  "SamplePointCANFDMax" FLOAT 50.0 99.9;
BA_DEF_ BU_  "SSPOffsetCANFDMin" FLOAT 50.0 99.9;
BA_DEF_ BU_  "SSPOffsetCANFDMax" FLOAT 50.0 99.9;
BA_DEF_ BU_  "TimeQuantaMin" INT 4 257;
BA_DEF_ BU_  "TimeQuantaMax" INT 4 257;
BA_DEF_ BU_  "TimeQuantaCANFDMin" INT 4 257;
BA_DEF_ BU_  "TimeQuantaCANFDMax" INT 4 257;
BA_DEF_REL_ BU_SG_REL_  "GenSigTimeoutTime" INT 0 65535;
BA_DEF_ BO_  "DiagRequest" ENUM "No", "Yes";
BA_DEF_ BO_  "DiagResponse" ENUM "No", "Yes";
BA_DEF_ BO_  "DiagState" ENUM "No", "Yes";
BA_DEF_ BO_  "GenMsgChkConstant" HEX 0 4095;
BA_DEF_ BO_  "GenMsgCycleTime" INT 0 65535;
BA_DEF_ BO_  "GenMsgCycleTimeFast" INT 0 65535;
BA_DEF_ BO_  "GenMsgDelayTime" INT 0 100000;
BA_DEF_ BO_  "GenMsgILSupport" ENUM "No", "Yes";
BA_DEF_ BO_  "GenMsgNrOfRepetition" INT 0 100;
BA_DEF_ BO_  "GenMsgPDUConstants" STRING;
BA_DEF_ BO_  "GenMsgSendType" ENUM "Cyclic", "not_used", "not_used", "not_used", "not_used", "not_used", "not_used", "IfActive", "NoMsgSendType";
BA_DEF_ BO_  "GenMsgStartDelayTime" INT 0 100000;
BA_DEF_ BO_  "NmMessage" ENUM "No", "Yes";
BA_DEF_ BO_  "NmhMessage" ENUM "No", "Yes";
BA_DEF_ BO_  "MsgType" ENUM "Application", "NM ", "NMH", "TP2.0", "ISO-TP ", "BAP", "EID", "KS", "XCP_PRE_CONFIGURED", "XCP_RUNTIME_CONFIGURED";
BA_DEF_ BO_  "VAGTP20_API" HEX 0 255;
BA_DEF_ BO_  "VAGTP20_DynConnection" ENUM "No", "Yes";
BA_DEF_ BO_  "VAGTP20_DynSetup" ENUM "No", "Yes";
BA_DEF_ BO_  "VAGTP20_StatConnection" ENUM "No", "Yes";
BA_DEF_ BO_  "CANFD_BRS" ENUM "0", "1";
BA_DEF_ BO_  "VFrameFormat" ENUM "StandardCAN", "ExtendedCAN", "reserved", "reserved", "reserved", "reserved", "reserved", "reserved", "reserved", "reserved", "reserved", "reserved", "reserved", "reserved", "StandardCAN_FD", "ExtendedCAN_FD";
BA_DEF_ SG_  "GenSigActiveRepetitions" INT -2147483648 2147483647;
BA_DEF_ SG_  "GenSigInactiveValue" INT -2147483648 2147483647;
BA_DEF_ SG_  "GenSigSendType" ENUM "Cyclic", "OnWrite", "OnWriteWithRepetition", "OnChange", "OnChangeWithRepetition", "IfActive", "IfActiveWithRepetition", "NoSigSendType", "OnChangeAndIfActive", "OnChangeAndIfActiveWithRepetition";
BA_DEF_ SG_  "GenSigStartValue" INT -2147483648 2147483647;
BA_DEF_ SG_  "NWM-WakeupAllowed" ENUM "No", "Yes";
BA_DEF_ SG_  "GenSigFuncType" ENUM "NoFunction", "MsgCounter", "CRC-8", "XOR", "XOR-2", "DatedBit", "SW-Kl15", "CHK", "Constant", "Protocol", "CRC-8-SAE_J1850", "CRC-32", "DataLength", "DataID", "MsgCounter16", "SOK-Signatur", "Cluster";
BA_DEF_ SG_  "GenSigSwitchedByIgnition" ENUM "No", "Yes";
BA_DEF_ SG_  "Fehlerwert" HEX 0 2147483647;
BA_DEF_ SG_  "GenSigMissingSourceValue" HEX 0 2147483647;
BA_DEF_DEF_  "DBName" "";
BA_DEF_DEF_  "GenNWMApBusSleep" "";
BA_DEF_DEF_  "GenNWMApCanNormal" "";
BA_DEF_DEF_  "GenNWMApCanOff" "";
BA_DEF_DEF_  "GenNWMApCanOn" "";
BA_DEF_DEF_  "GenNWMApCanSleep" "";
BA_DEF_DEF_  "GenNWMApCanWakeUp" "";
BA_DEF_DEF_  "GenNWMGotoMode_Awake" "";
BA_DEF_DEF_  "GenNWMGotoMode_BusSleep" "";
BA_DEF_DEF_  "GenNWMSleepTime" 0;
BA_DEF_DEF_  "GenNWMTalkNM" "";
BA_DEF_DEF_  "Manufacturer" "";
BA_DEF_DEF_  "NmhBaseAddress" 0;
BA_DEF_DEF_  "NmhMessageCount" 1;
BA_DEF_DEF_  "NmType" "None";
BA_DEF_DEF_  "VAGTP20_SetupMessageCount" 0;
BA_DEF_DEF_  "VAGTP20_SetupStartAddress" 0;
BA_DEF_DEF_  "VersionDay" 12;
BA_DEF_DEF_  "VersionMonth" 6;
BA_DEF_DEF_  "VersionWeek" 24;
BA_DEF_DEF_  "VersionYear" 23;
BA_DEF_DEF_  "VersionNumber" 0;
BA_DEF_DEF_  "BusType" "";
BA_DEF_DEF_  "Baudrate" 500000;
BA_DEF_DEF_  "BaudrateCANFD" 2000000;
BA_DEF_DEF_  "NmhTimeoutTimer" 0;
BA_DEF_DEF_  "NmhWaitBusSleepTimer" 0;
BA_DEF_DEF_  "NmhPrepareBusSleepTimer" 0;
BA_DEF_DEF_  "NmhLongTimer" 0;
BA_DEF_DEF_  "NmhNStart" 0;
BA_DEF_DEF_  "GenNodAutoGenDsp" "Yes";
BA_DEF_DEF_  "GenNodAutoGenSnd" "Yes";
BA_DEF_DEF_  "GenNodSleepTime" 0;
BA_DEF_DEF_  "ILUsed" "Yes";
BA_DEF_DEF_  "ECUVariantDefault" "Yes";
BA_DEF_DEF_  "ECUVariantGroup" "";
BA_DEF_DEF_  "NodeLayerModules" "";
BA_DEF_DEF_  "NmhNode" "Yes";
BA_DEF_DEF_  "NmNode" "No";
BA_DEF_DEF_  "SamplePointMin" 75;
BA_DEF_DEF_  "SamplePointMax" 75;
BA_DEF_DEF_  "SyncJumpWidthMin" 50;
BA_DEF_DEF_  "SyncJumpWidthMax" 50;
BA_DEF_DEF_  "SyncJumpWidthCANFDMin" 50;
BA_DEF_DEF_  "SyncJumpWidthCANFDMax" 50;
BA_DEF_DEF_  "SamplePointCANFDMin" 75;
BA_DEF_DEF_  "SamplePointCANFDMax" 75;
BA_DEF_DEF_  "SSPOffsetCANFDMin" 75;
BA_DEF_DEF_  "SSPOffsetCANFDMax" 75;
BA_DEF_DEF_  "TimeQuantaMin" 160;
BA_DEF_DEF_  "TimeQuantaMax" 160;
BA_DEF_DEF_  "TimeQuantaCANFDMin" 40;
BA_DEF_DEF_  "TimeQuantaCANFDMax" 40;
BA_DEF_DEF_REL_  "GenSigTimeoutTime" 0;
BA_DEF_DEF_  "DiagRequest" "No";
BA_DEF_DEF_  "DiagResponse" "No";
BA_DEF_DEF_  "DiagState" "No";
BA_DEF_DEF_  "GenMsgChkConstant" 0;
BA_DEF_DEF_  "GenMsgCycleTime" 0;
BA_DEF_DEF_  "GenMsgCycleTimeFast" 0;
BA_DEF_DEF_  "GenMsgDelayTime" 0;
BA_DEF_DEF_  "GenMsgILSupport" "No";
BA_DEF_DEF_  "GenMsgNrOfRepetition" 0;
BA_DEF_DEF_  "GenMsgPDUConstants" "";
BA_DEF_DEF_  "GenMsgSendType" "NoMsgSendType";
BA_DEF_DEF_  "GenMsgStartDelayTime" 0;
BA_DEF_DEF_  "NmMessage" "No";
BA_DEF_DEF_  "NmhMessage" "No";
BA_DEF_DEF_  "MsgType" "Application";
BA_DEF_DEF_  "VAGTP20_API" 0;
BA_DEF_DEF_  "VAGTP20_DynConnection" "No";
BA_DEF_DEF_  "VAGTP20_DynSetup" "No";
BA_DEF_DEF_  "VAGTP20_StatConnection" "No";
BA_DEF_DEF_  "CANFD_BRS" "1";
BA_DEF_DEF_  "VFrameFormat" "StandardCAN";
BA_DEF_DEF_  "GenSigActiveRepetitions" 0;
BA_DEF_DEF_  "GenSigInactiveValue" 0;
BA_DEF_DEF_  "GenSigSendType" "NoSigSendType";
BA_DEF_DEF_  "GenSigStartValue" 0;
BA_DEF_DEF_  "NWM-WakeupAllowed" "No";
BA_DEF_DEF_  "GenSigFuncType" "NoFunction";
BA_DEF_DEF_  "GenSigSwitchedByIgnition" "Yes";
BA_DEF_DEF_  "Fehlerwert" 0;
BA_DEF_DEF_  "GenSigMissingSourceValue" 0;
BA_  "DBName" "EVCANFD";
BA_  "GenNWMApBusSleep" "NMIndNetSDN()";
BA_  "GenNWMApCanNormal" "apCanNormal()";
BA_  "GenNWMApCanOff" "NMIndnetOff()";
BA_  "GenNWMApCanOn" "NMIndnetOn()";
BA_  "GenNWMApCanSleep" "apCanSleep()";
BA_  "GenNWMApCanWakeUp" "apCanWakeUp()";
BA_  "GenNWMGotoMode_Awake" "Nmh_ReqNetOn()";
BA_  "GenNWMGotoMode_BusSleep" "Nmh_ReqNetOff()";
BA_  "GenNWMSleepTime" 4000;
BA_  "GenNWMTalkNM" "Nmh_ReqNetOn()";
BA_  "Manufacturer" "VAG";
BA_  "NmhBaseAddress" 452984832;
BA_  "NmhMessageCount" 1024;
BA_  "NmType" "NM-High";
BA_  "VAGTP20_SetupMessageCount" 128;
BA_  "VAGTP20_SetupStartAddress" 512;
BA_  "VersionNumber" 9;
BA_  "BusType" "CAN FD";
BA_  "NmhTimeoutTimer" 1000;
BA_  "NmhWaitBusSleepTimer" 750;
BA_  "NmhPrepareBusSleepTimer" 500;
BA_  "NmhLongTimer" 200;
BA_  "NmhNStart" 20;
BA_ "GenNodSleepTime" BU_ BAP_Tester 4000;
BA_ "ECUVariantGroup" BU_ BAP_Tester "BAP";
BA_ "NmhNode" BU_ BAP_Tester 0;
BA_ "SamplePointMin" BU_ BAP_Tester 80;
BA_ "SamplePointMax" BU_ BAP_Tester 80;
BA_ "SyncJumpWidthMin" BU_ BAP_Tester 16;
BA_ "SyncJumpWidthMax" BU_ BAP_Tester 16;
BA_ "SyncJumpWidthCANFDMin" BU_ BAP_Tester 6;
BA_ "SyncJumpWidthCANFDMax" BU_ BAP_Tester 6;
BA_ "SamplePointCANFDMin" BU_ BAP_Tester 70;
BA_ "SamplePointCANFDMax" BU_ BAP_Tester 70;
BA_ "SSPOffsetCANFDMin" BU_ BAP_Tester 70;
BA_ "SSPOffsetCANFDMax" BU_ BAP_Tester 70;
BA_ "TimeQuantaMin" BU_ BAP_Tester 80;
BA_ "TimeQuantaMax" BU_ BAP_Tester 80;
BA_ "TimeQuantaCANFDMin" BU_ BAP_Tester 20;
BA_ "TimeQuantaCANFDMax" BU_ BAP_Tester 20;
BA_ "GenNodSleepTime" BU_ BMS_NV_12V 4000;
BA_ "NodeLayerModules" BU_ BMS_NV_12V "NMHigh.DLL";
BA_ "SamplePointMin" BU_ BMS_NV_12V 80;
BA_ "SamplePointMax" BU_ BMS_NV_12V 80;
BA_ "SyncJumpWidthMin" BU_ BMS_NV_12V 16;
BA_ "SyncJumpWidthMax" BU_ BMS_NV_12V 16;
BA_ "SyncJumpWidthCANFDMin" BU_ BMS_NV_12V 6;
BA_ "SyncJumpWidthCANFDMax" BU_ BMS_NV_12V 6;
BA_ "SamplePointCANFDMin" BU_ BMS_NV_12V 70;
BA_ "SamplePointCANFDMax" BU_ BMS_NV_12V 70;
BA_ "SSPOffsetCANFDMin" BU_ BMS_NV_12V 70;
BA_ "SSPOffsetCANFDMax" BU_ BMS_NV_12V 70;
BA_ "TimeQuantaMin" BU_ BMS_NV_12V 80;
BA_ "TimeQuantaMax" BU_ BMS_NV_12V 80;
BA_ "TimeQuantaCANFDMin" BU_ BMS_NV_12V 20;
BA_ "TimeQuantaCANFDMax" BU_ BMS_NV_12V 20;
BA_ "GenNodSleepTime" BU_ Gateway_Max 4000;
BA_ "ECUVariantGroup" BU_ Gateway_Max "Gateway";
BA_ "NodeLayerModules" BU_ Gateway_Max "NMHigh.DLL";
BA_ "SamplePointMin" BU_ Gateway_Max 80;
BA_ "SamplePointMax" BU_ Gateway_Max 80;
BA_ "SyncJumpWidthMin" BU_ Gateway_Max 16;
BA_ "SyncJumpWidthMax" BU_ Gateway_Max 16;
BA_ "SyncJumpWidthCANFDMin" BU_ Gateway_Max 6;
BA_ "SyncJumpWidthCANFDMax" BU_ Gateway_Max 6;
BA_ "SamplePointCANFDMin" BU_ Gateway_Max 70;
BA_ "SamplePointCANFDMax" BU_ Gateway_Max 70;
BA_ "SSPOffsetCANFDMin" BU_ Gateway_Max 70;
BA_ "SSPOffsetCANFDMax" BU_ Gateway_Max 70;
BA_ "TimeQuantaMin" BU_ Gateway_Max 80;
BA_ "TimeQuantaMax" BU_ Gateway_Max 80;
BA_ "TimeQuantaCANFDMin" BU_ Gateway_Max 20;
BA_ "TimeQuantaCANFDMax" BU_ Gateway_Max 20;
BA_ "GenNodSleepTime" BU_ Klima 4000;
BA_ "NodeLayerModules" BU_ Klima "NMHigh.DLL";
BA_ "SamplePointMin" BU_ Klima 80;
BA_ "SamplePointMax" BU_ Klima 80;
BA_ "SyncJumpWidthMin" BU_ Klima 16;
BA_ "SyncJumpWidthMax" BU_ Klima 16;
BA_ "SyncJumpWidthCANFDMin" BU_ Klima 6;
BA_ "SyncJumpWidthCANFDMax" BU_ Klima 6;
BA_ "SamplePointCANFDMin" BU_ Klima 70;
BA_ "SamplePointCANFDMax" BU_ Klima 70;
BA_ "SSPOffsetCANFDMin" BU_ Klima 70;
BA_ "SSPOffsetCANFDMax" BU_ Klima 70;
BA_ "TimeQuantaMin" BU_ Klima 80;
BA_ "TimeQuantaMax" BU_ Klima 80;
BA_ "TimeQuantaCANFDMin" BU_ Klima 20;
BA_ "TimeQuantaCANFDMax" BU_ Klima 20;
BA_ "GenMsgChkConstant" BO_ 64 64;
BA_ "GenMsgCycleTime" BO_ 64 40;
BA_ "GenMsgCycleTimeFast" BO_ 64 10;
BA_ "GenMsgDelayTime" BO_ 64 10;
BA_ "GenMsgILSupport" BO_ 64 1;
BA_ "GenMsgNrOfRepetition" BO_ 64 5;
BA_ "GenMsgPDUConstants" BO_ 64 "0x40,0x40,0x40,0x40,0x40,0x40,0x40,0x40,0x40,0x40,0x40,0x40,0x40,0x40,0x40,0x40";
BA_ "GenMsgSendType" BO_ 64 0;
BA_ "VFrameFormat" BO_ 64 14;
BA_ "GenMsgChkConstant" BO_ 1312 68;
BA_ "GenMsgCycleTime" BO_ 1312 200;
BA_ "GenMsgDelayTime" BO_ 1312 20;
BA_ "GenMsgILSupport" BO_ 1312 1;
BA_ "GenMsgPDUConstants" BO_ 1312 "0x44,0x44,0x44,0x44,0x44,0x44,0x44,0x44,0x44,0x44,0x44,0x44,0x44,0x44,0x44,0x44";
BA_ "GenMsgSendType" BO_ 1312 0;
BA_ "VFrameFormat" BO_ 1312 14;
BA_ "GenMsgCycleTime" BO_ 1349 200;
BA_ "GenMsgDelayTime" BO_ 1349 40;
BA_ "GenMsgILSupport" BO_ 1349 1;
BA_ "GenMsgPDUConstants" BO_ 1349 "0x95,0x19,0xd1,0x36,0x89,0xd4,0x02,0x1e,0xb9,0x80,0xd0,0x22,0x8a,0xf4,0x15,0xb8";
BA_ "GenMsgSendType" BO_ 1349 0;
BA_ "VFrameFormat" BO_ 1349 14;
BA_ "GenMsgCycleTimeFast" BO_ 2536726528 80;
BA_ "GenMsgSendType" BO_ 2536726528 7;
BA_ "MsgType" BO_ 2536726528 5;
BA_ "VFrameFormat" BO_ 2536726528 15;
BA_ "GenMsgCycleTime" BO_ 2536726544 1000;
BA_ "GenMsgCycleTimeFast" BO_ 2536726544 50;
BA_ "GenMsgSendType" BO_ 2536726544 7;
BA_ "MsgType" BO_ 2536726544 5;
BA_ "VFrameFormat" BO_ 2536726544 15;
BA_ "MsgType" BO_ 2536767264 5;
BA_ "VFrameFormat" BO_ 2536767264 15;
BA_ "MsgType" BO_ 2536767280 5;
BA_ "VFrameFormat" BO_ 2536767280 15;
BA_ "GenMsgCycleTimeFast" BO_ 2536702208 80;
BA_ "GenMsgSendType" BO_ 2536702208 7;
BA_ "MsgType" BO_ 2536702208 5;
BA_ "VFrameFormat" BO_ 2536702208 15;
BA_ "GenMsgCycleTime" BO_ 2536702224 1000;
BA_ "GenMsgCycleTimeFast" BO_ 2536702224 50;
BA_ "GenMsgSendType" BO_ 2536702224 7;
BA_ "MsgType" BO_ 2536702224 5;
BA_ "VFrameFormat" BO_ 2536702224 15;
BA_ "GenMsgCycleTimeFast" BO_ 2536702464 80;
BA_ "GenMsgSendType" BO_ 2536702464 7;
BA_ "MsgType" BO_ 2536702464 5;
BA_ "VFrameFormat" BO_ 2536702464 15;
BA_ "GenMsgCycleTimeFast" BO_ 2536702466 80;
BA_ "GenMsgSendType" BO_ 2536702466 7;
BA_ "MsgType" BO_ 2536702466 5;
BA_ "VFrameFormat" BO_ 2536702466 15;
BA_ "GenMsgCycleTimeFast" BO_ 2536702468 80;
BA_ "GenMsgSendType" BO_ 2536702468 7;
BA_ "MsgType" BO_ 2536702468 5;
BA_ "VFrameFormat" BO_ 2536702468 15;
BA_ "GenMsgCycleTime" BO_ 2536702480 1000;
BA_ "GenMsgCycleTimeFast" BO_ 2536702480 50;
BA_ "GenMsgSendType" BO_ 2536702480 7;
BA_ "MsgType" BO_ 2536702480 5;
BA_ "VFrameFormat" BO_ 2536702480 15;
BA_ "GenMsgCycleTimeFast" BO_ 2536718848 80;
BA_ "GenMsgSendType" BO_ 2536718848 7;
BA_ "MsgType" BO_ 2536718848 5;
BA_ "VFrameFormat" BO_ 2536718848 15;
BA_ "GenMsgCycleTimeFast" BO_ 2536718849 80;
BA_ "GenMsgSendType" BO_ 2536718849 7;
BA_ "MsgType" BO_ 2536718849 5;
BA_ "VFrameFormat" BO_ 2536718849 15;
BA_ "GenMsgCycleTimeFast" BO_ 2536718850 80;
BA_ "GenMsgSendType" BO_ 2536718850 7;
BA_ "MsgType" BO_ 2536718850 5;
BA_ "VFrameFormat" BO_ 2536718850 15;
BA_ "GenMsgCycleTimeFast" BO_ 2536718851 80;
BA_ "GenMsgSendType" BO_ 2536718851 7;
BA_ "MsgType" BO_ 2536718851 5;
BA_ "VFrameFormat" BO_ 2536718851 15;
BA_ "GenMsgCycleTime" BO_ 2536718864 1000;
BA_ "GenMsgCycleTimeFast" BO_ 2536718864 50;
BA_ "GenMsgSendType" BO_ 2536718864 7;
BA_ "MsgType" BO_ 2536718864 5;
BA_ "VFrameFormat" BO_ 2536718864 15;
BA_ "GenMsgCycleTime" BO_ 1626 1000;
BA_ "GenMsgCycleTimeFast" BO_ 1626 100;
BA_ "GenMsgDelayTime" BO_ 1626 30;
BA_ "GenMsgILSupport" BO_ 1626 1;
BA_ "GenMsgNrOfRepetition" BO_ 1626 5;
BA_ "GenMsgSendType" BO_ 1626 0;
BA_ "VFrameFormat" BO_ 1626 14;
BA_ "GenMsgCycleTime" BO_ 2527679637 1000;
BA_ "GenMsgCycleTimeFast" BO_ 2527679637 100;
BA_ "GenMsgDelayTime" BO_ 2527679637 50;
BA_ "GenMsgILSupport" BO_ 2527679637 1;
BA_ "GenMsgNrOfRepetition" BO_ 2527679637 5;
BA_ "GenMsgSendType" BO_ 2527679637 0;
BA_ "VFrameFormat" BO_ 2527679637 15;
BA_ "GenMsgCycleTime" BO_ 2463978609 200;
BA_ "GenMsgDelayTime" BO_ 2463978609 20;
BA_ "GenMsgILSupport" BO_ 2463978609 1;
BA_ "GenMsgSendType" BO_ 2463978609 0;
BA_ "VFrameFormat" BO_ 2463978609 15;
BA_ "GenMsgCycleTime" BO_ 1635 100;
BA_ "GenMsgILSupport" BO_ 1635 1;
BA_ "GenMsgSendType" BO_ 1635 0;
BA_ "VFrameFormat" BO_ 1635 14;
BA_ "GenMsgCycleTime" BO_ 1163 100;
BA_ "GenMsgILSupport" BO_ 1163 1;
BA_ "GenMsgPDUConstants" BO_ 1163 "0x54,0xaf,0x8a,0xfb,0x0d,0x87,0x6a,0x0f,0x47,0x78,0x31,0x4f,0x35,0x28,0x82,0x6d";
BA_ "GenMsgSendType" BO_ 1163 0;
BA_ "VFrameFormat" BO_ 1163 14;
BA_ "GenMsgCycleTime" BO_ 2463978850 100;
BA_ "GenMsgILSupport" BO_ 2463978850 1;
BA_ "GenMsgPDUConstants" BO_ 2463978850 "0xaa,0xa9,0xe6,0xc5,0xc4,0x2b,0x0b,0x8e,0xfb,0x15,0xa4,0x64,0x1e,0x20,0x50,0x95";
BA_ "GenMsgSendType" BO_ 2463978850 0;
BA_ "VFrameFormat" BO_ 2463978850 15;
BA_ "GenMsgCycleTime" BO_ 1442 500;
BA_ "GenMsgCycleTimeFast" BO_ 1442 100;
BA_ "GenMsgDelayTime" BO_ 1442 20;
BA_ "GenMsgILSupport" BO_ 1442 1;
BA_ "GenMsgNrOfRepetition" BO_ 1442 5;
BA_ "GenMsgPDUConstants" BO_ 1442 "0xeb,0x4c,0x44,0xaf,0x21,0x8d,0x01,0x58,0xfa,0x93,0xdb,0x89,0x15,0x10,0x4a,0x61";
BA_ "GenMsgSendType" BO_ 1442 0;
BA_ "VFrameFormat" BO_ 1442 14;
BA_ "GenMsgCycleTime" BO_ 1450 500;
BA_ "GenMsgCycleTimeFast" BO_ 1450 100;
BA_ "GenMsgDelayTime" BO_ 1450 20;
BA_ "GenMsgSendType" BO_ 1450 0;
BA_ "VFrameFormat" BO_ 1450 14;
BA_ "GenMsgCycleTime" BO_ 687 50;
BA_ "GenMsgILSupport" BO_ 687 1;
BA_ "GenMsgSendType" BO_ 687 0;
BA_ "VFrameFormat" BO_ 687 14;
BA_ "GenMsgChkConstant" BO_ 1482 67;
BA_ "GenMsgCycleTime" BO_ 1482 500;
BA_ "GenMsgDelayTime" BO_ 1482 50;
BA_ "GenMsgILSupport" BO_ 1482 1;
BA_ "GenMsgPDUConstants" BO_ 1482 "0x43,0x43,0x43,0x43,0x43,0x43,0x43,0x43,0x43,0x43,0x43,0x43,0x43,0x43,0x43,0x43";
BA_ "GenMsgSendType" BO_ 1482 0;
BA_ "VFrameFormat" BO_ 1482 14;
BA_ "GenMsgCycleTime" BO_ 2527679654 200;
BA_ "GenMsgILSupport" BO_ 2527679654 1;
BA_ "GenMsgPDUConstants" BO_ 2527679654 "0x79,0xb9,0x67,0xad,0xd5,0xf7,0x70,0xaa,0x44,0x61,0x5a,0xdc,0x26,0xb4,0xd2,0xc3";
BA_ "GenMsgSendType" BO_ 2527679654 0;
BA_ "VFrameFormat" BO_ 2527679654 15;
BA_ "GenMsgCycleTime" BO_ 207 10;
BA_ "GenMsgILSupport" BO_ 207 1;
BA_ "GenMsgPDUConstants" BO_ 207 "0xee,0x80,0x6e,0x4e,0x29,0xc6,0x92,0xc0,0x65,0xaa,0x3a,0xa1,0x8f,0xcd,0xe6,0x90";
BA_ "GenMsgSendType" BO_ 207 0;
BA_ "VFrameFormat" BO_ 207 14;
BA_ "GenMsgCycleTime" BO_ 2463978704 100;
BA_ "GenMsgDelayTime" BO_ 2463978704 10;
BA_ "GenMsgILSupport" BO_ 2463978704 1;
BA_ "GenMsgSendType" BO_ 2463978704 0;
BA_ "VFrameFormat" BO_ 2463978704 15;
BA_ "GenMsgCycleTime" BO_ 2463978705 100;
BA_ "GenMsgILSupport" BO_ 2463978705 1;
BA_ "GenMsgPDUConstants" BO_ 2463978705 "0x9e,0xf9,0x68,0xc0,0xa0,0x93,0xbd,0xed,0xe4,0x99,0x88,0x28,0x07,0x0c,0x60,0x67";
BA_ "GenMsgSendType" BO_ 2463978705 0;
BA_ "VFrameFormat" BO_ 2463978705 15;
BA_ "GenMsgCycleTime" BO_ 2589283664 500;
BA_ "GenMsgILSupport" BO_ 2589283664 1;
BA_ "GenMsgSendType" BO_ 2589283664 0;
BA_ "VFrameFormat" BO_ 2589283664 15;
BA_ "GenMsgCycleTime" BO_ 2589283665 500;
BA_ "GenMsgILSupport" BO_ 2589283665 1;
BA_ "GenMsgSendType" BO_ 2589283665 0;
BA_ "VFrameFormat" BO_ 2589283665 15;
BA_ "GenMsgCycleTime" BO_ 2589283760 1000;
BA_ "GenMsgILSupport" BO_ 2589283760 1;
BA_ "GenMsgSendType" BO_ 2589283760 0;
BA_ "VFrameFormat" BO_ 2589283760 15;
BA_ "GenMsgCycleTime" BO_ 2589283762 500;
BA_ "GenMsgILSupport" BO_ 2589283762 1;
BA_ "GenMsgSendType" BO_ 2589283762 0;
BA_ "VFrameFormat" BO_ 2589283762 15;
BA_ "GenMsgCycleTime" BO_ 2331595856 100;
BA_ "GenMsgDelayTime" BO_ 2331595856 10;
BA_ "GenMsgILSupport" BO_ 2331595856 1;
BA_ "GenMsgSendType" BO_ 2331595856 0;
BA_ "VFrameFormat" BO_ 2331595856 15;
BA_ "GenSigSendType" SG_ 64 AB_Anzeige_Fussg 0;
BA_ "GenSigSwitchedByIgnition" SG_ 64 AB_Anzeige_Fussg 0;
BA_ "GenSigSendType" SG_ 64 AB_Belegung_VF 0;
BA_ "GenSigSwitchedByIgnition" SG_ 64 AB_Belegung_VF 0;
BA_ "Fehlerwert" SG_ 64 AB_Belegung_VF 1;
BA_ "GenSigSendType" SG_ 64 AB_Crash_Int 4;
BA_ "GenSigSwitchedByIgnition" SG_ 64 AB_Crash_Int 0;
BA_ "GenSigSendType" SG_ 64 AB_Deaktiviert 0;
BA_ "GenSigSwitchedByIgnition" SG_ 64 AB_Deaktiviert 0;
BA_ "GenSigSendType" SG_ 64 AB_Deaktivierung_HV 4;
BA_ "GenSigSwitchedByIgnition" SG_ 64 AB_Deaktivierung_HV 0;
BA_ "Fehlerwert" SG_ 64 AB_Deaktivierung_HV 7;
BA_ "GenSigSendType" SG_ 64 AB_Diagnose 0;
BA_ "GenSigSwitchedByIgnition" SG_ 64 AB_Diagnose 0;
BA_ "GenSigSendType" SG_ 64 AB_eCS_Error 0;
BA_ "GenSigSwitchedByIgnition" SG_ 64 AB_eCS_Error 0;
BA_ "GenSigSendType" SG_ 64 AB_EDR_Trigger 3;
BA_ "GenSigSwitchedByIgnition" SG_ 64 AB_EDR_Trigger 0;
BA_ "GenSigSendType" SG_ 64 AB_Erh_Auf_VB 0;
BA_ "GenSigSwitchedByIgnition" SG_ 64 AB_Erh_Auf_VB 0;
BA_ "GenSigSendType" SG_ 64 AB_Front_Crash 4;
BA_ "GenSigSwitchedByIgnition" SG_ 64 AB_Front_Crash 0;
BA_ "GenSigSendType" SG_ 64 AB_Gurtschloss_FA_ext 3;
BA_ "GenSigStartValue" SG_ 64 AB_Gurtschloss_FA_ext 6;
BA_ "GenSigSwitchedByIgnition" SG_ 64 AB_Gurtschloss_FA_ext 0;
BA_ "Fehlerwert" SG_ 64 AB_Gurtschloss_FA_ext 7;
BA_ "GenSigSendType" SG_ 64 AB_Gurtschloss_FA_ext_aktiv 0;
BA_ "GenSigSwitchedByIgnition" SG_ 64 AB_Gurtschloss_FA_ext_aktiv 0;
BA_ "GenSigSendType" SG_ 64 AB_Gurtwarn_VB 0;
BA_ "GenSigSwitchedByIgnition" SG_ 64 AB_Gurtwarn_VB 0;
BA_ "GenSigSendType" SG_ 64 AB_Gurtwarn_VF 0;
BA_ "GenSigSwitchedByIgnition" SG_ 64 AB_Gurtwarn_VF 0;
BA_ "GenSigSendType" SG_ 64 AB_Heck_Crash 4;
BA_ "GenSigSwitchedByIgnition" SG_ 64 AB_Heck_Crash 0;
BA_ "GenSigSendType" SG_ 64 AB_Lampe 0;
BA_ "GenSigStartValue" SG_ 64 AB_Lampe 1;
BA_ "GenSigSwitchedByIgnition" SG_ 64 AB_Lampe 0;
BA_ "GenSigSendType" SG_ 64 AB_MKB_Anforderung 4;
BA_ "GenSigSwitchedByIgnition" SG_ 64 AB_MKB_Anforderung 0;
BA_ "GenSigSendType" SG_ 64 AB_MKB_gueltig 0;
BA_ "GenSigSwitchedByIgnition" SG_ 64 AB_MKB_gueltig 0;
BA_ "GenSigSendType" SG_ 64 AB_PAO_Leuchte_Anf 0;
BA_ "GenSigStartValue" SG_ 64 AB_PAO_Leuchte_Anf 1;
BA_ "GenSigSwitchedByIgnition" SG_ 64 AB_PAO_Leuchte_Anf 0;
BA_ "GenSigSendType" SG_ 64 AB_RGS_Anst 3;
BA_ "GenSigStartValue" SG_ 64 AB_RGS_Anst 8;
BA_ "GenSigSwitchedByIgnition" SG_ 64 AB_RGS_Anst 0;
BA_ "GenSigSendType" SG_ 64 AB_Rollover_Crash 4;
BA_ "GenSigSwitchedByIgnition" SG_ 64 AB_Rollover_Crash 0;
BA_ "GenSigSendType" SG_ 64 AB_SB_Crash 4;
BA_ "GenSigSwitchedByIgnition" SG_ 64 AB_SB_Crash 0;
BA_ "GenSigSendType" SG_ 64 AB_SF_Crash 4;
BA_ "GenSigSwitchedByIgnition" SG_ 64 AB_SF_Crash 0;
BA_ "GenSigSendType" SG_ 64 AB_Stellgliedtest 0;
BA_ "GenSigSwitchedByIgnition" SG_ 64 AB_Stellgliedtest 0;
BA_ "GenSigSendType" SG_ 64 AB_Systemfehler 0;
BA_ "GenSigSwitchedByIgnition" SG_ 64 AB_Systemfehler 0;
BA_ "GenSigSendType" SG_ 64 AB_Texte_AKS 0;
BA_ "GenSigSwitchedByIgnition" SG_ 64 AB_Texte_AKS 0;
BA_ "GenSigSendType" SG_ 64 AB_VB_deaktiviert 0;
BA_ "GenSigStartValue" SG_ 64 AB_VB_deaktiviert 1;
BA_ "GenSigSwitchedByIgnition" SG_ 64 AB_VB_deaktiviert 0;
BA_ "GenSigSendType" SG_ 64 AB_Versorgungsspannung 0;
BA_ "GenSigSwitchedByIgnition" SG_ 64 AB_Versorgungsspannung 0;
BA_ "GenSigSendType" SG_ 64 Airbag_01_BZ 0;
BA_ "GenSigFuncType" SG_ 64 Airbag_01_BZ 1;
BA_ "GenSigSwitchedByIgnition" SG_ 64 Airbag_01_BZ 0;
BA_ "GenSigSendType" SG_ 64 Airbag_01_CRC 0;
BA_ "GenSigFuncType" SG_ 64 Airbag_01_CRC 2;
BA_ "GenSigSwitchedByIgnition" SG_ 64 Airbag_01_CRC 0;
BA_ "GenSigSendType" SG_ 64 ASM_Masterzeit_02 0;
BA_ "GenSigStartValue" SG_ 64 ASM_Masterzeit_02 255;
BA_ "GenSigSwitchedByIgnition" SG_ 64 ASM_Masterzeit_02 0;
BA_ "GenSigSendType" SG_ 1312 AB_Abschaltanf_SIH_BF 3;
BA_ "GenSigSendType" SG_ 1312 AB_Anforderung_eCall 0;
BA_ "GenSigSwitchedByIgnition" SG_ 1312 AB_Anforderung_eCall 0;
BA_ "GenSigSendType" SG_ 1312 AB_Anforderung_USM 0;
BA_ "GenSigSwitchedByIgnition" SG_ 1312 AB_Anforderung_USM 0;
BA_ "GenSigSendType" SG_ 1312 AB_Anprall_FGS 3;
BA_ "GenSigSendType" SG_ 1312 AB_Anprall_Front_Beifahrer 3;
BA_ "GenSigSendType" SG_ 1312 AB_Anprall_Front_Fahrer 3;
BA_ "GenSigSendType" SG_ 1312 AB_Anprall_Heck_Beifahrer 3;
BA_ "GenSigSendType" SG_ 1312 AB_Anprall_Heck_Fahrer 3;
BA_ "GenSigSendType" SG_ 1312 AB_Anprall_Rollover 3;
BA_ "GenSigSendType" SG_ 1312 AB_Anprall_Seite_Beifahrer 3;
BA_ "GenSigSendType" SG_ 1312 AB_Anprall_Seite_Fahrer 3;
BA_ "GenSigSendType" SG_ 1312 AB_Belegung_VB 0;
BA_ "GenSigSwitchedByIgnition" SG_ 1312 AB_Belegung_VB 0;
BA_ "Fehlerwert" SG_ 1312 AB_Belegung_VB 1;
BA_ "GenSigSendType" SG_ 1312 AB_Crashschwere 3;
BA_ "GenSigSwitchedByIgnition" SG_ 1312 AB_Crashschwere 0;
BA_ "Fehlerwert" SG_ 1312 AB_Crashschwere 7;
BA_ "GenSigSendType" SG_ 1312 AB_Gurtschloss_BF 3;
BA_ "GenSigStartValue" SG_ 1312 AB_Gurtschloss_BF 1;
BA_ "GenSigSwitchedByIgnition" SG_ 1312 AB_Gurtschloss_BF 0;
BA_ "GenSigSendType" SG_ 1312 AB_Gurtschloss_FA 3;
BA_ "GenSigStartValue" SG_ 1312 AB_Gurtschloss_FA 1;
BA_ "GenSigSwitchedByIgnition" SG_ 1312 AB_Gurtschloss_FA 0;
BA_ "GenSigSendType" SG_ 1312 AB_Gurtschloss_Reihe2_BF 3;
BA_ "GenSigStartValue" SG_ 1312 AB_Gurtschloss_Reihe2_BF 1;
BA_ "GenSigSwitchedByIgnition" SG_ 1312 AB_Gurtschloss_Reihe2_BF 0;
BA_ "GenSigSendType" SG_ 1312 AB_Gurtschloss_Reihe2_FA 3;
BA_ "GenSigStartValue" SG_ 1312 AB_Gurtschloss_Reihe2_FA 1;
BA_ "GenSigSwitchedByIgnition" SG_ 1312 AB_Gurtschloss_Reihe2_FA 0;
BA_ "GenSigSendType" SG_ 1312 AB_Gurtschloss_Reihe2_MI 3;
BA_ "GenSigStartValue" SG_ 1312 AB_Gurtschloss_Reihe2_MI 1;
BA_ "GenSigSwitchedByIgnition" SG_ 1312 AB_Gurtschloss_Reihe2_MI 0;
BA_ "GenSigSendType" SG_ 1312 AB_Gurtschloss_Reihe3_BF 3;
BA_ "GenSigStartValue" SG_ 1312 AB_Gurtschloss_Reihe3_BF 1;
BA_ "GenSigSwitchedByIgnition" SG_ 1312 AB_Gurtschloss_Reihe3_BF 0;
BA_ "GenSigSendType" SG_ 1312 AB_Gurtschloss_Reihe3_FA 3;
BA_ "GenSigStartValue" SG_ 1312 AB_Gurtschloss_Reihe3_FA 1;
BA_ "GenSigSwitchedByIgnition" SG_ 1312 AB_Gurtschloss_Reihe3_FA 0;
BA_ "GenSigSendType" SG_ 1312 AB_Gurtschloss_Reihe3_MI 3;
BA_ "GenSigStartValue" SG_ 1312 AB_Gurtschloss_Reihe3_MI 1;
BA_ "GenSigSwitchedByIgnition" SG_ 1312 AB_Gurtschloss_Reihe3_MI 0;
BA_ "GenSigSendType" SG_ 1312 AB_Sitzpos_Sens_BF 0;
BA_ "GenSigSwitchedByIgnition" SG_ 1312 AB_Sitzpos_Sens_BF 0;
BA_ "Fehlerwert" SG_ 1312 AB_Sitzpos_Sens_BF 1;
BA_ "GenSigSendType" SG_ 1312 AB_Sitzpos_Sens_FA 0;
BA_ "GenSigSwitchedByIgnition" SG_ 1312 AB_Sitzpos_Sens_FA 0;
BA_ "Fehlerwert" SG_ 1312 AB_Sitzpos_Sens_FA 1;
BA_ "GenSigSendType" SG_ 1312 AB_Wickelklappung_Reihe2_BF 3;
BA_ "GenSigStartValue" SG_ 1312 AB_Wickelklappung_Reihe2_BF 1;
BA_ "GenSigSwitchedByIgnition" SG_ 1312 AB_Wickelklappung_Reihe2_BF 0;
BA_ "GenSigSendType" SG_ 1312 AB_Wickelklappung_Reihe2_FA 3;
BA_ "GenSigStartValue" SG_ 1312 AB_Wickelklappung_Reihe2_FA 1;
BA_ "GenSigSwitchedByIgnition" SG_ 1312 AB_Wickelklappung_Reihe2_FA 0;
BA_ "GenSigSendType" SG_ 1312 AB_Wickelklappung_Reihe2_MI 3;
BA_ "GenSigStartValue" SG_ 1312 AB_Wickelklappung_Reihe2_MI 1;
BA_ "GenSigSwitchedByIgnition" SG_ 1312 AB_Wickelklappung_Reihe2_MI 0;
BA_ "GenSigSendType" SG_ 1312 Airbag_02_BZ 0;
BA_ "GenSigFuncType" SG_ 1312 Airbag_02_BZ 1;
BA_ "GenSigSwitchedByIgnition" SG_ 1312 Airbag_02_BZ 0;
BA_ "GenSigSendType" SG_ 1312 Airbag_02_CRC 0;
BA_ "GenSigFuncType" SG_ 1312 Airbag_02_CRC 2;
BA_ "GenSigSwitchedByIgnition" SG_ 1312 Airbag_02_CRC 0;
BA_ "GenSigSendType" SG_ 1312 LoGeWa_Event_Kombiwarnung 3;
BA_ "GenSigSwitchedByIgnition" SG_ 1312 LoGeWa_Event_Kombiwarnung 0;
BA_ "GenSigSendType" SG_ 1312 SC_PAO_OFF_Anf 3;
BA_ "GenSigSwitchedByIgnition" SG_ 1312 SC_PAO_OFF_Anf 0;
BA_ "GenSigSendType" SG_ 1312 SC_PAO_ON_Anf 3;
BA_ "GenSigSwitchedByIgnition" SG_ 1312 SC_PAO_ON_Anf 0;
BA_ "GenSigSendType" SG_ 1312 SC_PAO_Schriftzug_Anf 3;
BA_ "GenSigSwitchedByIgnition" SG_ 1312 SC_PAO_Schriftzug_Anf 0;
BA_ "GenSigSendType" SG_ 1349 AB_Anprall_Front 3;
BA_ "GenSigSwitchedByIgnition" SG_ 1349 AB_Anprall_Front 0;
BA_ "GenSigSendType" SG_ 1349 AB_Anprall_Heck 3;
BA_ "GenSigSwitchedByIgnition" SG_ 1349 AB_Anprall_Heck 0;
BA_ "GenSigSendType" SG_ 1349 AB_Belegung_VF_ext 3;
BA_ "GenSigStartValue" SG_ 1349 AB_Belegung_VF_ext 6;
BA_ "GenSigSwitchedByIgnition" SG_ 1349 AB_Belegung_VF_ext 0;
BA_ "Fehlerwert" SG_ 1349 AB_Belegung_VF_ext 7;
BA_ "GenSigSendType" SG_ 1349 AB_Belegung_VF_ext_aktiv 3;
BA_ "GenSigSwitchedByIgnition" SG_ 1349 AB_Belegung_VF_ext_aktiv 0;
BA_ "GenSigSendType" SG_ 1349 AB_Gurtwarn_Reihe2_BF 0;
BA_ "GenSigSwitchedByIgnition" SG_ 1349 AB_Gurtwarn_Reihe2_BF 0;
BA_ "GenSigSendType" SG_ 1349 AB_Gurtwarn_Reihe2_FA 0;
BA_ "GenSigSwitchedByIgnition" SG_ 1349 AB_Gurtwarn_Reihe2_FA 0;
BA_ "GenSigSendType" SG_ 1349 AB_Gurtwarn_Reihe2_MI 0;
BA_ "GenSigSwitchedByIgnition" SG_ 1349 AB_Gurtwarn_Reihe2_MI 0;
BA_ "GenSigSendType" SG_ 1349 AB_Gurtwarn_Reihe3_BF 0;
BA_ "GenSigSwitchedByIgnition" SG_ 1349 AB_Gurtwarn_Reihe3_BF 0;
BA_ "GenSigSendType" SG_ 1349 AB_Gurtwarn_Reihe3_FA 0;
BA_ "GenSigSwitchedByIgnition" SG_ 1349 AB_Gurtwarn_Reihe3_FA 0;
BA_ "GenSigSendType" SG_ 1349 AB_Gurtwarn_Reihe3_MI 0;
BA_ "GenSigSwitchedByIgnition" SG_ 1349 AB_Gurtwarn_Reihe3_MI 0;
BA_ "GenSigSendType" SG_ 1349 AB_Gurtwarn_Reihe4_BF 0;
BA_ "GenSigSwitchedByIgnition" SG_ 1349 AB_Gurtwarn_Reihe4_BF 0;
BA_ "GenSigSendType" SG_ 1349 AB_Gurtwarn_Reihe4_FA 0;
BA_ "GenSigSwitchedByIgnition" SG_ 1349 AB_Gurtwarn_Reihe4_FA 0;
BA_ "GenSigSendType" SG_ 1349 AB_Gurtwarn_Reihe4_MI 0;
BA_ "GenSigSwitchedByIgnition" SG_ 1349 AB_Gurtwarn_Reihe4_MI 0;
BA_ "GenSigSendType" SG_ 1349 AB_SBR_hinten_verbau 0;
BA_ "GenSigStartValue" SG_ 1349 AB_SBR_hinten_verbau 3;
BA_ "GenSigSwitchedByIgnition" SG_ 1349 AB_SBR_hinten_verbau 0;
BA_ "GenSigSendType" SG_ 1349 AbstWarn_MV_FAS_Fkt_Status 3;
BA_ "GenSigSwitchedByIgnition" SG_ 1349 AbstWarn_MV_FAS_Fkt_Status 0;
BA_ "Fehlerwert" SG_ 1349 AbstWarn_MV_FAS_Fkt_Status 3;
BA_ "GenSigSendType" SG_ 1349 Airbag_04_BZ 0;
BA_ "GenSigFuncType" SG_ 1349 Airbag_04_BZ 1;
BA_ "GenSigSwitchedByIgnition" SG_ 1349 Airbag_04_BZ 0;
BA_ "GenSigSendType" SG_ 1349 Airbag_04_CRC 0;
BA_ "GenSigFuncType" SG_ 1349 Airbag_04_CRC 2;
BA_ "GenSigSwitchedByIgnition" SG_ 1349 Airbag_04_CRC 0;
BA_ "GenSigSendType" SG_ 1349 AWV_Einstellung_System_ASG 3;
BA_ "GenSigSwitchedByIgnition" SG_ 1349 AWV_Einstellung_System_ASG 0;
BA_ "GenSigSendType" SG_ 1349 AWV_Einstellung_Warnung_ASG 3;
BA_ "GenSigSwitchedByIgnition" SG_ 1349 AWV_Einstellung_Warnung_ASG 0;
BA_ "GenSigSendType" SG_ 1349 LGI_FAS_Fkt_Status 3;
BA_ "GenSigSwitchedByIgnition" SG_ 1349 LGI_FAS_Fkt_Status 0;
BA_ "Fehlerwert" SG_ 1349 LGI_FAS_Fkt_Status 3;
BA_ "GenSigSendType" SG_ 1349 PreCrash_FAS_Fkt_Status 3;
BA_ "GenSigSwitchedByIgnition" SG_ 1349 PreCrash_FAS_Fkt_Status 0;
BA_ "Fehlerwert" SG_ 1349 PreCrash_FAS_Fkt_Status 3;
BA_ "GenSigSendType" SG_ 1349 SC_PreSense_Modus_System_KAS 3;
BA_ "GenSigSwitchedByIgnition" SG_ 1349 SC_PreSense_Modus_System_KAS 0;
BA_ "GenSigSendType" SG_ 1349 SC_PreSense_Modus_System_MV 3;
BA_ "GenSigSwitchedByIgnition" SG_ 1349 SC_PreSense_Modus_System_MV 0;
BA_ "GenSigSendType" SG_ 1349 SC_PreSense_Modus_System_NV 3;
BA_ "GenSigSwitchedByIgnition" SG_ 1349 SC_PreSense_Modus_System_NV 0;
BA_ "GenSigSendType" SG_ 1349 SC_PreSense_Modus_Warnung_MV 3;
BA_ "GenSigSwitchedByIgnition" SG_ 1349 SC_PreSense_Modus_Warnung_MV 0;
BA_ "GenSigSendType" SG_ 1349 SC_PreSense_Modus_Warnung_NV 3;
BA_ "GenSigSwitchedByIgnition" SG_ 1349 SC_PreSense_Modus_Warnung_NV 0;
BA_ "GenSigSendType" SG_ 1349 WarnBrems_Charisma_FahrPr 0;
BA_ "GenSigSendType" SG_ 1349 WarnBrems_Charisma_Status 0;
BA_ "GenSigSendType" SG_ 2536726528 BAP_ClimateDiag_ASG_01_Header 3;
BA_ "GenSigSwitchedByIgnition" SG_ 2536726528 BAP_ClimateDiag_ASG_01_Header 0;
BA_ "GenSigSendType" SG_ 2536726544 BAP_ClimateDiag_FSG_01_Header 3;
BA_ "GenSigSwitchedByIgnition" SG_ 2536726544 BAP_ClimateDiag_FSG_01_Header 0;
BA_ "GenSigSendType" SG_ 2536767264 BAP_Debug_Cmd 3;
BA_ "GenSigSwitchedByIgnition" SG_ 2536767264 BAP_Debug_Cmd 0;
BA_ "GenSigSendType" SG_ 2536767280 BAP_Debug_Data 3;
BA_ "GenSigSwitchedByIgnition" SG_ 2536767280 BAP_Debug_Data 0;
BA_ "GenSigSendType" SG_ 2536702208 BAP_Klima1_ASG_01_Header 3;
BA_ "GenSigSwitchedByIgnition" SG_ 2536702208 BAP_Klima1_ASG_01_Header 0;
BA_ "GenSigSendType" SG_ 2536702224 BAP_Klima1_FSG_01_Header 3;
BA_ "GenSigSwitchedByIgnition" SG_ 2536702224 BAP_Klima1_FSG_01_Header 0;
BA_ "GenSigSendType" SG_ 2536702464 BAP_Klima2_ASG_01_Header 3;
BA_ "GenSigSwitchedByIgnition" SG_ 2536702464 BAP_Klima2_ASG_01_Header 0;
BA_ "GenSigSendType" SG_ 2536702466 BAP_Klima2_ASG_03_Header 3;
BA_ "GenSigSwitchedByIgnition" SG_ 2536702466 BAP_Klima2_ASG_03_Header 0;
BA_ "GenSigSendType" SG_ 2536702468 BAP_Klima2_ASG_05_Header 3;
BA_ "GenSigSwitchedByIgnition" SG_ 2536702468 BAP_Klima2_ASG_05_Header 0;
BA_ "GenSigSendType" SG_ 2536702480 BAP_Klima2_FSG_01_Header 3;
BA_ "GenSigSwitchedByIgnition" SG_ 2536702480 BAP_Klima2_FSG_01_Header 0;
BA_ "GenSigSendType" SG_ 2536718848 BAP_KlimaMaster_ASG_01_Header 3;
BA_ "GenSigSwitchedByIgnition" SG_ 2536718848 BAP_KlimaMaster_ASG_01_Header 0;
BA_ "GenSigSendType" SG_ 2536718849 BAP_KlimaMaster_ASG_02_Header 3;
BA_ "GenSigSwitchedByIgnition" SG_ 2536718849 BAP_KlimaMaster_ASG_02_Header 0;
BA_ "GenSigSendType" SG_ 2536718850 BAP_KlimaMaster_ASG_03_Header 3;
BA_ "GenSigSwitchedByIgnition" SG_ 2536718850 BAP_KlimaMaster_ASG_03_Header 0;
BA_ "GenSigSendType" SG_ 2536718851 BAP_KlimaMaster_ASG_04_Header 3;
BA_ "GenSigSwitchedByIgnition" SG_ 2536718851 BAP_KlimaMaster_ASG_04_Header 0;
BA_ "GenSigSendType" SG_ 2536718864 BAP_KlimaMaster_FSG_01_Header 3;
BA_ "GenSigSwitchedByIgnition" SG_ 2536718864 BAP_KlimaMaster_FSG_01_Header 0;
BA_ "GenSigSendType" SG_ 1626 APS_Tongeber_defekt 3;
BA_ "GenSigSwitchedByIgnition" SG_ 1626 APS_Tongeber_defekt 0;
BA_ "GenSigSendType" SG_ 1626 BCM1_AFS_Lampe 3;
BA_ "GenSigSwitchedByIgnition" SG_ 1626 BCM1_AFS_Lampe 0;
BA_ "GenSigSendType" SG_ 1626 BCM1_EasyEntry_Status 3;
BA_ "GenSigSwitchedByIgnition" SG_ 1626 BCM1_EasyEntry_Status 0;
BA_ "GenSigSendType" SG_ 1626 BCM1_Fahrlicht_Hinweis 3;
BA_ "GenSigSwitchedByIgnition" SG_ 1626 BCM1_Fahrlicht_Hinweis 0;
BA_ "GenSigSendType" SG_ 1626 BCM1_Hinweis_Lichtnachlauf 3;
BA_ "GenSigSwitchedByIgnition" SG_ 1626 BCM1_Hinweis_Lichtnachlauf 0;
BA_ "GenSigSendType" SG_ 1626 BCM1_Kl_15_HW_erkannt 3;
BA_ "GenSigSwitchedByIgnition" SG_ 1626 BCM1_Kl_15_HW_erkannt 0;
BA_ "GenSigSendType" SG_ 1626 BCM1_Kl_15_Sig_HW_erkannt 3;
BA_ "GenSigSwitchedByIgnition" SG_ 1626 BCM1_Kl_15_Sig_HW_erkannt 0;
BA_ "GenSigSendType" SG_ 1626 BCM1_LDS_Stellung 3;
BA_ "GenSigSwitchedByIgnition" SG_ 1626 BCM1_LDS_Stellung 0;
BA_ "Fehlerwert" SG_ 1626 BCM1_LDS_Stellung 7;
BA_ "GenSigSendType" SG_ 1626 BCM1_Lenksaeule_aktiv 3;
BA_ "GenSigSwitchedByIgnition" SG_ 1626 BCM1_Lenksaeule_aktiv 0;
BA_ "GenSigSendType" SG_ 1626 BCM1_Licht_Warn 3;
BA_ "GenSigSwitchedByIgnition" SG_ 1626 BCM1_Licht_Warn 0;
BA_ "GenSigSendType" SG_ 1626 BCM1_Lichtwarn_Texte 3;
BA_ "GenSigSwitchedByIgnition" SG_ 1626 BCM1_Lichtwarn_Texte 0;
BA_ "GenSigSendType" SG_ 1626 BCM1_MH_Schalter 3;
BA_ "GenSigSwitchedByIgnition" SG_ 1626 BCM1_MH_Schalter 0;
BA_ "GenSigSendType" SG_ 1626 BCM1_MH_WIV_Schalter 3;
BA_ "GenSigSwitchedByIgnition" SG_ 1626 BCM1_MH_WIV_Schalter 0;
BA_ "GenSigSendType" SG_ 1626 BCM1_NV_Taster 0;
BA_ "GenSigSwitchedByIgnition" SG_ 1626 BCM1_NV_Taster 0;
BA_ "GenSigSendType" SG_ 1626 BCM1_Reisemodus_Texte 3;
BA_ "GenSigSwitchedByIgnition" SG_ 1626 BCM1_Reisemodus_Texte 0;
BA_ "GenSigSendType" SG_ 1626 BCM1_Rueckfahrlicht_Schalter 3;
BA_ "GenSigSwitchedByIgnition" SG_ 1626 BCM1_Rueckfahrlicht_Schalter 0;
BA_ "GenSigSendType" SG_ 1626 BCM1_Spannungs_Anf 3;
BA_ "GenSigSwitchedByIgnition" SG_ 1626 BCM1_Spannungs_Anf 0;
BA_ "GenSigSendType" SG_ 1626 BCM1_Valet_Parking_Taster 0;
BA_ "GenSigSwitchedByIgnition" SG_ 1626 BCM1_Valet_Parking_Taster 0;
BA_ "GenSigSendType" SG_ 1626 BCM1_Warnblink_Taster 3;
BA_ "GenSigSwitchedByIgnition" SG_ 1626 BCM1_Warnblink_Taster 0;
BA_ "GenSigSendType" SG_ 1626 BCM_Anf_AAW_MoLaWa 3;
BA_ "GenSigSwitchedByIgnition" SG_ 1626 BCM_Anf_AAW_MoLaWa 0;
BA_ "GenSigSendType" SG_ 1626 BCM_Bremsbelag_Sensor 3;
BA_ "GenSigSwitchedByIgnition" SG_ 1626 BCM_Bremsbelag_Sensor 0;
BA_ "GenSigSendType" SG_ 1626 BCM_Bremsfluessigkeit_Sensor 3;
BA_ "GenSigSwitchedByIgnition" SG_ 1626 BCM_Bremsfluessigkeit_Sensor 0;
BA_ "GenSigSendType" SG_ 1626 BCM_Charisma_Taste2 3;
BA_ "GenSigSwitchedByIgnition" SG_ 1626 BCM_Charisma_Taste2 0;
BA_ "GenSigSendType" SG_ 1626 BCM_Eco_Charisma_Taste 3;
BA_ "GenSigSwitchedByIgnition" SG_ 1626 BCM_Eco_Charisma_Taste 0;
BA_ "GenSigSendType" SG_ 1626 BCM_Handbremse_Hinweis 4;
BA_ "GenSigSwitchedByIgnition" SG_ 1626 BCM_Handbremse_Hinweis 0;
BA_ "GenSigSendType" SG_ 1626 BCM_HBFS_EOE_aktiv 4;
BA_ "GenSigSwitchedByIgnition" SG_ 1626 BCM_HBFS_EOE_aktiv 0;
BA_ "GenSigSendType" SG_ 1626 BCM_HDF_betaetigt 4;
BA_ "GenSigSwitchedByIgnition" SG_ 1626 BCM_HDF_betaetigt 0;
BA_ "GenSigSendType" SG_ 1626 BCM_HFS_EOE_aktiv 4;
BA_ "GenSigSwitchedByIgnition" SG_ 1626 BCM_HFS_EOE_aktiv 0;
BA_ "GenSigSendType" SG_ 1626 BCM_Hybrid_StartStopp_Taste 3;
BA_ "GenSigSwitchedByIgnition" SG_ 1626 BCM_Hybrid_StartStopp_Taste 0;
BA_ "GenSigSendType" SG_ 1626 BCM_Hybrid_StSt_Taste_Fehler 3;
BA_ "GenSigSwitchedByIgnition" SG_ 1626 BCM_Hybrid_StSt_Taste_Fehler 0;
BA_ "GenSigSendType" SG_ 1626 BCM_Kuehlmittel_Sensor 3;
BA_ "GenSigSwitchedByIgnition" SG_ 1626 BCM_Kuehlmittel_Sensor 0;
BA_ "GenSigSendType" SG_ 1626 BCM_Kuehlmittel_Sensor_02 3;
BA_ "GenSigSwitchedByIgnition" SG_ 1626 BCM_Kuehlmittel_Sensor_02 0;
BA_ "GenSigSendType" SG_ 1626 BCM_Offroad_Taste 3;
BA_ "GenSigSwitchedByIgnition" SG_ 1626 BCM_Offroad_Taste 0;
BA_ "GenSigSendType" SG_ 1626 BCM_ValetTaster_Fkts_LED 4;
BA_ "GenSigSwitchedByIgnition" SG_ 1626 BCM_ValetTaster_Fkts_LED 0;
BA_ "GenSigSendType" SG_ 1626 BCM_Waehlhebel_P_Hinweis 4;
BA_ "GenSigSwitchedByIgnition" SG_ 1626 BCM_Waehlhebel_P_Hinweis 0;
BA_ "GenSigSendType" SG_ 1626 BCM_Waschwasser_Sensor 3;
BA_ "GenSigSwitchedByIgnition" SG_ 1626 BCM_Waschwasser_Sensor 0;
BA_ "GenSigSendType" SG_ 1626 DWA_Alarmquelle 0;
BA_ "GenSigStartValue" SG_ 1626 DWA_Alarmquelle 30;
BA_ "GenSigSwitchedByIgnition" SG_ 1626 DWA_Alarmquelle 0;
BA_ "Fehlerwert" SG_ 1626 DWA_Alarmquelle 31;
BA_ "GenSigSendType" SG_ 1626 DWA_Einschraenkung 0;
BA_ "GenSigSwitchedByIgnition" SG_ 1626 DWA_Einschraenkung 0;
BA_ "Fehlerwert" SG_ 1626 DWA_Einschraenkung 1;
BA_ "GenSigSendType" SG_ 1626 Gong_TFL_Umschaltung 3;
BA_ "GenSigSwitchedByIgnition" SG_ 1626 Gong_TFL_Umschaltung 0;
BA_ "GenSigSendType" SG_ 1626 LRH_Taster 3;
BA_ "GenSigSwitchedByIgnition" SG_ 1626 LRH_Taster 0;
BA_ "GenSigSendType" SG_ 2527679637 BCM_anf_VLW 3;
BA_ "GenSigSwitchedByIgnition" SG_ 2527679637 BCM_anf_VLW 0;
BA_ "GenSigSendType" SG_ 2527679637 BCM_Defrost_Taste 3;
BA_ "GenSigStartValue" SG_ 2527679637 BCM_Defrost_Taste 3;
BA_ "GenSigSwitchedByIgnition" SG_ 2527679637 BCM_Defrost_Taste 0;
BA_ "Fehlerwert" SG_ 2527679637 BCM_Defrost_Taste 2;
BA_ "GenSigSendType" SG_ 2527679637 BCM_FAS_Taster 4;
BA_ "GenSigSwitchedByIgnition" SG_ 2527679637 BCM_FAS_Taster 0;
BA_ "GenSigSendType" SG_ 2527679637 BCM_FSH_Taste 3;
BA_ "GenSigStartValue" SG_ 2527679637 BCM_FSH_Taste 3;
BA_ "GenSigSwitchedByIgnition" SG_ 2527679637 BCM_FSH_Taste 0;
BA_ "Fehlerwert" SG_ 2527679637 BCM_FSH_Taste 2;
BA_ "GenSigSendType" SG_ 2527679637 BCM_HSH_Taste 3;
BA_ "GenSigStartValue" SG_ 2527679637 BCM_HSH_Taste 3;
BA_ "GenSigSwitchedByIgnition" SG_ 2527679637 BCM_HSH_Taste 0;
BA_ "Fehlerwert" SG_ 2527679637 BCM_HSH_Taste 2;
BA_ "GenSigSendType" SG_ 2527679637 BCM_LTM_Allwetterl_Status 3;
BA_ "GenSigSwitchedByIgnition" SG_ 2527679637 BCM_LTM_Allwetterl_Status 0;
BA_ "GenSigSendType" SG_ 2527679637 BCM_LTM_Nebell_Status 3;
BA_ "GenSigSwitchedByIgnition" SG_ 2527679637 BCM_LTM_Nebell_Status 0;
BA_ "GenSigSendType" SG_ 2527679637 BCM_LTM_Nebelschluss_Status 3;
BA_ "GenSigSwitchedByIgnition" SG_ 2527679637 BCM_LTM_Nebelschluss_Status 0;
BA_ "GenSigSendType" SG_ 2527679637 BCM_LTM_PopUp_Anf 3;
BA_ "GenSigSwitchedByIgnition" SG_ 2527679637 BCM_LTM_PopUp_Anf 0;
BA_ "GenSigSendType" SG_ 2527679637 BCM_LTM_PopUp_Inhalt 3;
BA_ "GenSigSwitchedByIgnition" SG_ 2527679637 BCM_LTM_PopUp_Inhalt 0;
BA_ "GenSigSendType" SG_ 2527679637 BCM_LTM_PopUp_Status 3;
BA_ "GenSigSwitchedByIgnition" SG_ 2527679637 BCM_LTM_PopUp_Status 0;
BA_ "GenSigSendType" SG_ 2527679637 BCM_LTM_PopUp_Texte 3;
BA_ "GenSigSwitchedByIgnition" SG_ 2527679637 BCM_LTM_PopUp_Texte 0;
BA_ "GenSigSendType" SG_ 2527679637 CPD_Warnung 3;
BA_ "GenSigSwitchedByIgnition" SG_ 2527679637 CPD_Warnung 0;
BA_ "GenSigSendType" SG_ 2527679637 LiSi_Touch_Event 3;
BA_ "GenSigSwitchedByIgnition" SG_ 2527679637 LiSi_Touch_Event 0;
BA_ "Fehlerwert" SG_ 2527679637 LiSi_Touch_Event 15;
BA_ "GenSigSendType" SG_ 2527679637 LTMs_01_alt 0;
BA_ "GenSigStartValue" SG_ 2527679637 LTMs_01_alt 1;
BA_ "GenSigFuncType" SG_ 2527679637 LTMs_01_alt 5;
BA_ "GenSigSwitchedByIgnition" SG_ 2527679637 LTMs_01_alt 0;
BA_ "GenSigSendType" SG_ 2527679637 MiKo_Tisch_Positionswarnung 3;
BA_ "GenSigSwitchedByIgnition" SG_ 2527679637 MiKo_Tisch_Positionswarnung 0;
BA_ "GenSigSendType" SG_ 2463978609 BCM_Relais_2_Batterie 3;
BA_ "GenSigSwitchedByIgnition" SG_ 2463978609 BCM_Relais_2_Batterie 0;
BA_ "GenSigSendType" SG_ 2463978609 FA_Hoehenwert_HL_01 3;
BA_ "GenSigStartValue" SG_ 2463978609 FA_Hoehenwert_HL_01 254;
BA_ "Fehlerwert" SG_ 2463978609 FA_Hoehenwert_HL_01 255;
BA_ "GenSigSendType" SG_ 2463978609 FA_Hoehenwert_VL_01 3;
BA_ "GenSigStartValue" SG_ 2463978609 FA_Hoehenwert_VL_01 254;
BA_ "Fehlerwert" SG_ 2463978609 FA_Hoehenwert_VL_01 255;
BA_ "GenSigSendType" SG_ 2463978609 HSH_LED 3;
BA_ "GenSigSwitchedByIgnition" SG_ 2463978609 HSH_LED 0;
BA_ "GenSigSendType" SG_ 2463978609 HSH_Status 0;
BA_ "GenSigSwitchedByIgnition" SG_ 2463978609 HSH_Status 0;
BA_ "GenSigSendType" SG_ 2463978609 KRH_Stufe_LED_li 3;
BA_ "GenSigSwitchedByIgnition" SG_ 2463978609 KRH_Stufe_LED_li 0;
BA_ "GenSigSendType" SG_ 2463978609 KRH_Stufe_LED_re 3;
BA_ "GenSigSwitchedByIgnition" SG_ 2463978609 KRH_Stufe_LED_re 0;
BA_ "GenSigSendType" SG_ 2463978609 Niveausensor_HL_verbaut 3;
BA_ "GenSigSwitchedByIgnition" SG_ 2463978609 Niveausensor_HL_verbaut 0;
BA_ "GenSigSendType" SG_ 2463978609 Niveausensor_VL_verbaut 3;
BA_ "GenSigSwitchedByIgnition" SG_ 2463978609 Niveausensor_VL_verbaut 0;
BA_ "GenSigSendType" SG_ 2463978609 SIL_Stufe_LED_li 3;
BA_ "GenSigSwitchedByIgnition" SG_ 2463978609 SIL_Stufe_LED_li 0;
BA_ "GenSigSendType" SG_ 2463978609 SIL_Stufe_LED_re 3;
BA_ "GenSigSwitchedByIgnition" SG_ 2463978609 SIL_Stufe_LED_re 0;
BA_ "GenSigSendType" SG_ 1635 BEM_Anf_KL15_schalten 0;
BA_ "GenSigSwitchedByIgnition" SG_ 1635 BEM_Anf_KL15_schalten 0;
BA_ "GenSigSendType" SG_ 1635 BEM_Batt_Ab 0;
BA_ "GenSigSwitchedByIgnition" SG_ 1635 BEM_Batt_Ab 0;
BA_ "GenSigSendType" SG_ 1635 BEM_Batteriediagnose 0;
BA_ "GenSigSwitchedByIgnition" SG_ 1635 BEM_Batteriediagnose 0;
BA_ "Fehlerwert" SG_ 1635 BEM_Batteriediagnose 7;
BA_ "GenSigSendType" SG_ 1635 BEM_DFM 0;
BA_ "GenSigSwitchedByIgnition" SG_ 1635 BEM_DFM 0;
BA_ "GenSigSendType" SG_ 1635 BEM_EMLIN_ungueltig 0;
BA_ "GenSigSwitchedByIgnition" SG_ 1635 BEM_EMLIN_ungueltig 0;
BA_ "GenSigSendType" SG_ 1635 BEM_Generatordiagnose 0;
BA_ "GenSigSwitchedByIgnition" SG_ 1635 BEM_Generatordiagnose 0;
BA_ "GenSigSendType" SG_ 1635 BEM_HL_Kontingentierung 0;
BA_ "GenSigSwitchedByIgnition" SG_ 1635 BEM_HL_Kontingentierung 0;
BA_ "GenSigSendType" SG_ 1635 BEM_HL_Regelung_Status 0;
BA_ "GenSigSwitchedByIgnition" SG_ 1635 BEM_HL_Regelung_Status 0;
BA_ "GenSigSendType" SG_ 1635 BEM_Ladezustand 0;
BA_ "GenSigStartValue" SG_ 1635 BEM_Ladezustand 14;
BA_ "GenSigSwitchedByIgnition" SG_ 1635 BEM_Ladezustand 0;
BA_ "Fehlerwert" SG_ 1635 BEM_Ladezustand 15;
BA_ "GenSigSendType" SG_ 1635 BEM_MMI_Vorwarnung 0;
BA_ "GenSigSwitchedByIgnition" SG_ 1635 BEM_MMI_Vorwarnung 0;
BA_ "GenSigSendType" SG_ 1635 BEM_Red_Innengeblaese 0;
BA_ "GenSigSwitchedByIgnition" SG_ 1635 BEM_Red_Innengeblaese 0;
BA_ "GenSigSendType" SG_ 1635 BEM_REK_aktiv 0;
BA_ "GenSigSwitchedByIgnition" SG_ 1635 BEM_REK_aktiv 0;
BA_ "GenSigSendType" SG_ 1635 BEM_STH_Einschaltverbot 0;
BA_ "GenSigSwitchedByIgnition" SG_ 1635 BEM_STH_Einschaltverbot 0;
BA_ "GenSigSendType" SG_ 1635 BEM_STH_Zielzeit 0;
BA_ "GenSigStartValue" SG_ 1635 BEM_STH_Zielzeit 14;
BA_ "GenSigSwitchedByIgnition" SG_ 1635 BEM_STH_Zielzeit 0;
BA_ "Fehlerwert" SG_ 1635 BEM_STH_Zielzeit 15;
BA_ "GenSigSendType" SG_ 1635 BEM_UBDM 0;
BA_ "GenSigSwitchedByIgnition" SG_ 1635 BEM_UBDM 0;
BA_ "Fehlerwert" SG_ 1635 BEM_UBDM 255;
BA_ "GenSigSendType" SG_ 1635 BEM_UGenSoll 0;
BA_ "GenSigSwitchedByIgnition" SG_ 1635 BEM_UGenSoll 0;
BA_ "GenSigSendType" SG_ 1635 MIB_Stromsparmodus 0;
BA_ "GenSigSwitchedByIgnition" SG_ 1635 MIB_Stromsparmodus 0;
BA_ "GenSigSendType" SG_ 1635 NVEM_Abschaltstufe 0;
BA_ "GenSigSwitchedByIgnition" SG_ 1635 NVEM_Abschaltstufe 0;
BA_ "GenSigSendType" SG_ 1635 NVEM_Anf_SD_schalten 0;
BA_ "GenSigSwitchedByIgnition" SG_ 1635 NVEM_Anf_SD_schalten 0;
BA_ "GenSigSendType" SG_ 1635 NVEM_Batterie_Service 0;
BA_ "GenSigSwitchedByIgnition" SG_ 1635 NVEM_Batterie_Service 0;
BA_ "GenSigSendType" SG_ 1635 NVEM_Freigabe_OnlineUpdate 0;
BA_ "GenSigSwitchedByIgnition" SG_ 1635 NVEM_Freigabe_OnlineUpdate 0;
BA_ "GenSigSendType" SG_ 1635 NVEM_Freigabe_ORU4 0;
BA_ "GenSigSwitchedByIgnition" SG_ 1635 NVEM_Freigabe_ORU4 0;
BA_ "GenSigSendType" SG_ 1635 NVEM_Freigabe_ZusBatt_Laden 0;
BA_ "GenSigSwitchedByIgnition" SG_ 1635 NVEM_Freigabe_ZusBatt_Laden 0;
BA_ "GenSigSendType" SG_ 1635 NVEM_Verbraucherabsch_Anz 0;
BA_ "GenSigSwitchedByIgnition" SG_ 1635 NVEM_Verbraucherabsch_Anz 0;
BA_ "GenSigSendType" SG_ 1163 BEM_06_BZ 0;
BA_ "GenSigFuncType" SG_ 1163 BEM_06_BZ 1;
BA_ "GenSigSwitchedByIgnition" SG_ 1163 BEM_06_BZ 0;
BA_ "GenSigSendType" SG_ 1163 BEM_06_CRC 0;
BA_ "GenSigFuncType" SG_ 1163 BEM_06_CRC 2;
BA_ "GenSigSwitchedByIgnition" SG_ 1163 BEM_06_CRC 0;
BA_ "GenSigSendType" SG_ 1163 HLR_PTC_linear_Freigabe 0;
BA_ "GenSigSwitchedByIgnition" SG_ 1163 HLR_PTC_linear_Freigabe 0;
BA_ "Fehlerwert" SG_ 1163 HLR_PTC_linear_Freigabe 63;
BA_ "GenSigSendType" SG_ 1163 NVEM2_Status_FuSiFahrt 0;
BA_ "GenSigSwitchedByIgnition" SG_ 1163 NVEM2_Status_FuSiFahrt 0;
BA_ "Fehlerwert" SG_ 1163 NVEM2_Status_FuSiFahrt 7;
BA_ "GenSigSendType" SG_ 1163 NVEM2_Typ_EnergieNetz 0;
BA_ "GenSigStartValue" SG_ 1163 NVEM2_Typ_EnergieNetz 15;
BA_ "GenSigSwitchedByIgnition" SG_ 1163 NVEM2_Typ_EnergieNetz 0;
BA_ "Fehlerwert" SG_ 1163 NVEM2_Typ_EnergieNetz 14;
BA_ "GenSigSendType" SG_ 1163 NVEM_Betriebsart 0;
BA_ "GenSigSwitchedByIgnition" SG_ 1163 NVEM_Betriebsart 0;
BA_ "Fehlerwert" SG_ 1163 NVEM_Betriebsart 15;
BA_ "GenSigSendType" SG_ 1163 NVEM_Bordnetzdiagnose 0;
BA_ "GenSigSwitchedByIgnition" SG_ 1163 NVEM_Bordnetzdiagnose 0;
BA_ "GenSigSendType" SG_ 1163 NVEM_Energie_Klima_Vorgabe 0;
BA_ "GenSigStartValue" SG_ 1163 NVEM_Energie_Klima_Vorgabe 254;
BA_ "GenSigSwitchedByIgnition" SG_ 1163 NVEM_Energie_Klima_Vorgabe 0;
BA_ "Fehlerwert" SG_ 1163 NVEM_Energie_Klima_Vorgabe 255;
BA_ "GenSigSendType" SG_ 1163 NVEM_Energienetz_Status 0;
BA_ "GenSigStartValue" SG_ 1163 NVEM_Energienetz_Status 6;
BA_ "GenSigSwitchedByIgnition" SG_ 1163 NVEM_Energienetz_Status 0;
BA_ "Fehlerwert" SG_ 1163 NVEM_Energienetz_Status 7;
BA_ "GenSigSendType" SG_ 1163 NVEM_Ladezustand 0;
BA_ "GenSigStartValue" SG_ 1163 NVEM_Ladezustand 126;
BA_ "GenSigSwitchedByIgnition" SG_ 1163 NVEM_Ladezustand 0;
BA_ "Fehlerwert" SG_ 1163 NVEM_Ladezustand 127;
BA_ "GenSigSendType" SG_ 1163 NVEM_Last_Anf 0;
BA_ "GenSigSwitchedByIgnition" SG_ 1163 NVEM_Last_Anf 0;
BA_ "GenSigSendType" SG_ 1163 NVEM_PTC_Sollstufe 0;
BA_ "GenSigSwitchedByIgnition" SG_ 1163 NVEM_PTC_Sollstufe 0;
BA_ "GenSigSendType" SG_ 1163 NVEM_Red_KomfortVerbrauch 0;
BA_ "GenSigSwitchedByIgnition" SG_ 1163 NVEM_Red_KomfortVerbrauch 0;
BA_ "Fehlerwert" SG_ 1163 NVEM_Red_KomfortVerbrauch 15;
BA_ "GenSigSendType" SG_ 1163 NVEM_STH_ZielzeitLang 0;
BA_ "GenSigStartValue" SG_ 1163 NVEM_STH_ZielzeitLang 14;
BA_ "GenSigSwitchedByIgnition" SG_ 1163 NVEM_STH_ZielzeitLang 0;
BA_ "Fehlerwert" SG_ 1163 NVEM_STH_ZielzeitLang 15;
BA_ "GenSigSendType" SG_ 1163 NVEM_Vorgabe_Leistungsstufe 0;
BA_ "GenSigSwitchedByIgnition" SG_ 1163 NVEM_Vorgabe_Leistungsstufe 0;
BA_ "Fehlerwert" SG_ 1163 NVEM_Vorgabe_Leistungsstufe 7;
BA_ "GenSigSendType" SG_ 2463978850 BEM_07_BZ 0;
BA_ "GenSigFuncType" SG_ 2463978850 BEM_07_BZ 1;
BA_ "GenSigSwitchedByIgnition" SG_ 2463978850 BEM_07_BZ 0;
BA_ "GenSigSendType" SG_ 2463978850 BEM_07_CRC 0;
BA_ "GenSigFuncType" SG_ 2463978850 BEM_07_CRC 2;
BA_ "GenSigSwitchedByIgnition" SG_ 2463978850 BEM_07_CRC 0;
BA_ "GenSigSendType" SG_ 2463978850 NVEM2_VerbrZustandsAnf 0;
BA_ "GenSigStartValue" SG_ 2463978850 NVEM2_VerbrZustandsAnf 14;
BA_ "GenSigSwitchedByIgnition" SG_ 2463978850 NVEM2_VerbrZustandsAnf 0;
BA_ "Fehlerwert" SG_ 2463978850 NVEM2_VerbrZustandsAnf 15;
BA_ "GenSigSendType" SG_ 2463978850 NVEM3_Absch_SCR 0;
BA_ "GenSigSwitchedByIgnition" SG_ 2463978850 NVEM3_Absch_SCR 0;
BA_ "GenSigSendType" SG_ 2463978850 NVEM_Batt_Temp_Hinweis 0;
BA_ "GenSigSwitchedByIgnition" SG_ 2463978850 NVEM_Batt_Temp_Hinweis 0;
BA_ "GenSigSendType" SG_ 2463978850 NVEM_Bordnetz_Information 0;
BA_ "GenSigStartValue" SG_ 2463978850 NVEM_Bordnetz_Information 14;
BA_ "GenSigSwitchedByIgnition" SG_ 2463978850 NVEM_Bordnetz_Information 0;
BA_ "Fehlerwert" SG_ 2463978850 NVEM_Bordnetz_Information 15;
BA_ "GenSigSendType" SG_ 2463978850 NVEM_NVStuetzungAnf 0;
BA_ "GenSigSwitchedByIgnition" SG_ 2463978850 NVEM_NVStuetzungAnf 0;
BA_ "Fehlerwert" SG_ 2463978850 NVEM_NVStuetzungAnf 3;
BA_ "GenSigSendType" SG_ 2463978850 NVEM_Verbraucher_Information 0;
BA_ "GenSigStartValue" SG_ 2463978850 NVEM_Verbraucher_Information 6;
BA_ "GenSigSwitchedByIgnition" SG_ 2463978850 NVEM_Verbraucher_Information 0;
BA_ "Fehlerwert" SG_ 2463978850 NVEM_Verbraucher_Information 7;
BA_ "GenSigSendType" SG_ 1442 BMS_04_BZ 0;
BA_ "GenSigFuncType" SG_ 1442 BMS_04_BZ 1;
BA_ "GenSigSwitchedByIgnition" SG_ 1442 BMS_04_BZ 0;
BA_ "GenSigSendType" SG_ 1442 BMS_04_CRC 0;
BA_ "GenSigFuncType" SG_ 1442 BMS_04_CRC 2;
BA_ "GenSigSwitchedByIgnition" SG_ 1442 BMS_04_CRC 0;
BA_ "GenSigSendType" SG_ 1442 BMS_Fehler_Pilot 0;
BA_ "GenSigSwitchedByIgnition" SG_ 1442 BMS_Fehler_Pilot 0;
BA_ "GenSigSendType" SG_ 1442 BMS_Fehlerlampe_Anf 0;
BA_ "GenSigSwitchedByIgnition" SG_ 1442 BMS_Fehlerlampe_Anf 0;
BA_ "GenSigSendType" SG_ 1442 BMS_Fehlerstatus 3;
BA_ "GenSigStartValue" SG_ 1442 BMS_Fehlerstatus 7;
BA_ "GenSigSwitchedByIgnition" SG_ 1442 BMS_Fehlerstatus 0;
BA_ "GenSigSendType" SG_ 1442 BMS_Kapazitaet_02 0;
BA_ "GenSigStartValue" SG_ 1442 BMS_Kapazitaet_02 2047;
BA_ "GenSigSwitchedByIgnition" SG_ 1442 BMS_Kapazitaet_02 0;
BA_ "GenSigSendType" SG_ 1442 BMS_Kl30c_Status 4;
BA_ "GenSigSwitchedByIgnition" SG_ 1442 BMS_Kl30c_Status 0;
BA_ "Fehlerwert" SG_ 1442 BMS_Kl30c_Status 3;
BA_ "GenSigSendType" SG_ 1442 BMS_OBD_Lampe_Anf 0;
BA_ "GenSigSwitchedByIgnition" SG_ 1442 BMS_OBD_Lampe_Anf 0;
BA_ "GenSigSendType" SG_ 1442 BMS_Status_ServiceDisconnect 0;
BA_ "GenSigSwitchedByIgnition" SG_ 1442 BMS_Status_ServiceDisconnect 0;
BA_ "GenSigSendType" SG_ 1442 BMS_Status_Spgfreiheit 0;
BA_ "GenSigSwitchedByIgnition" SG_ 1442 BMS_Status_Spgfreiheit 0;
BA_ "GenSigSendType" SG_ 1442 BMS_Warnlampe_Anf 0;
BA_ "GenSigSwitchedByIgnition" SG_ 1442 BMS_Warnlampe_Anf 0;
BA_ "GenSigSendType" SG_ 1450 SOK_BMS_04_Signatur 0;
BA_ "GenSigFuncType" SG_ 1450 SOK_BMS_04_Signatur 15;
BA_ "GenSigSwitchedByIgnition" SG_ 1450 SOK_BMS_04_Signatur 0;
BA_ "GenSigSendType" SG_ 687 BMC_Spannung 0;
BA_ "GenSigStartValue" SG_ 687 BMC_Spannung 16382;
BA_ "GenSigSwitchedByIgnition" SG_ 687 BMC_Spannung 0;
BA_ "Fehlerwert" SG_ 687 BMC_Spannung 16383;
BA_ "GenSigSendType" SG_ 687 BMS_As_Entladezaehler 0;
BA_ "GenSigSwitchedByIgnition" SG_ 687 BMS_As_Entladezaehler 0;
BA_ "GenSigSendType" SG_ 687 BMS_As_Entladezaehler_Ueberlauf 0;
BA_ "GenSigSwitchedByIgnition" SG_ 687 BMS_As_Entladezaehler_Ueberlauf 0;
BA_ "GenSigSendType" SG_ 687 BMS_Rekuperation 0;
BA_ "GenSigSwitchedByIgnition" SG_ 687 BMS_Rekuperation 0;
BA_ "GenSigSendType" SG_ 687 BMS_Rekuperation_Ueberlauf 0;
BA_ "GenSigSwitchedByIgnition" SG_ 687 BMS_Rekuperation_Ueberlauf 0;
BA_ "GenSigSendType" SG_ 687 BMS_Verbrauch 0;
BA_ "GenSigSwitchedByIgnition" SG_ 687 BMS_Verbrauch 0;
BA_ "GenSigSendType" SG_ 687 BMS_Verbrauch_Ueberlauf 0;
BA_ "GenSigSwitchedByIgnition" SG_ 687 BMS_Verbrauch_Ueberlauf 0;
BA_ "GenSigSendType" SG_ 1482 BMS_07_BZ 0;
BA_ "GenSigFuncType" SG_ 1482 BMS_07_BZ 1;
BA_ "GenSigSwitchedByIgnition" SG_ 1482 BMS_07_BZ 0;
BA_ "GenSigSendType" SG_ 1482 BMS_07_CRC 0;
BA_ "GenSigFuncType" SG_ 1482 BMS_07_CRC 2;
BA_ "GenSigSwitchedByIgnition" SG_ 1482 BMS_07_CRC 0;
BA_ "GenSigSendType" SG_ 1482 BMS_Ausgleichsladung_Anf 0;
BA_ "GenSigSwitchedByIgnition" SG_ 1482 BMS_Ausgleichsladung_Anf 0;
BA_ "GenSigSendType" SG_ 1482 BMS_Balancing_Aktiv 0;
BA_ "GenSigSwitchedByIgnition" SG_ 1482 BMS_Balancing_Aktiv 0;
BA_ "GenSigSendType" SG_ 1482 BMS_Batteriediagnose 3;
BA_ "GenSigStartValue" SG_ 1482 BMS_Batteriediagnose 1;
BA_ "GenSigSwitchedByIgnition" SG_ 1482 BMS_Batteriediagnose 0;
BA_ "Fehlerwert" SG_ 1482 BMS_Batteriediagnose 7;
BA_ "GenSigSendType" SG_ 1482 BMS_Energieinhalt 0;
BA_ "GenSigStartValue" SG_ 1482 BMS_Energieinhalt 2046;
BA_ "GenSigSwitchedByIgnition" SG_ 1482 BMS_Energieinhalt 0;
BA_ "Fehlerwert" SG_ 1482 BMS_Energieinhalt 2047;
BA_ "GenSigSendType" SG_ 1482 BMS_Gesamtst_Spgfreiheit 3;
BA_ "GenSigSwitchedByIgnition" SG_ 1482 BMS_Gesamtst_Spgfreiheit 0;
BA_ "GenSigSendType" SG_ 1482 BMS_KundenWarnung 3;
BA_ "GenSigSwitchedByIgnition" SG_ 1482 BMS_KundenWarnung 0;
BA_ "GenSigSendType" SG_ 1482 BMS_Ladevorgang_aktiv 0;
BA_ "GenSigSwitchedByIgnition" SG_ 1482 BMS_Ladevorgang_aktiv 0;
BA_ "GenSigSendType" SG_ 1482 BMS_MaxEnergieinhalt 0;
BA_ "GenSigStartValue" SG_ 1482 BMS_MaxEnergieinhalt 2046;
BA_ "GenSigSwitchedByIgnition" SG_ 1482 BMS_MaxEnergieinhalt 0;
BA_ "Fehlerwert" SG_ 1482 BMS_MaxEnergieinhalt 2047;
BA_ "GenSigSendType" SG_ 1482 BMS_RIso_Ext 0;
BA_ "GenSigStartValue" SG_ 1482 BMS_RIso_Ext 4094;
BA_ "GenSigSwitchedByIgnition" SG_ 1482 BMS_RIso_Ext 0;
BA_ "Fehlerwert" SG_ 1482 BMS_RIso_Ext 4095;
BA_ "GenSigSendType" SG_ 2527679654 BMS_11_BZ 0;
BA_ "GenSigFuncType" SG_ 2527679654 BMS_11_BZ 1;
BA_ "GenSigSwitchedByIgnition" SG_ 2527679654 BMS_11_BZ 0;
BA_ "GenSigSendType" SG_ 2527679654 BMS_11_CRC 0;
BA_ "GenSigFuncType" SG_ 2527679654 BMS_11_CRC 2;
BA_ "GenSigSwitchedByIgnition" SG_ 2527679654 BMS_11_CRC 0;
BA_ "GenSigSendType" SG_ 2527679654 BMS_IsoFehler 0;
BA_ "GenSigSwitchedByIgnition" SG_ 2527679654 BMS_IsoFehler 0;
BA_ "GenSigSendType" SG_ 2527679654 BMS_IsoZustand 0;
BA_ "GenSigSwitchedByIgnition" SG_ 2527679654 BMS_IsoZustand 0;
BA_ "GenSigSendType" SG_ 2527679654 BMS_IstTemperatur_hoechste 0;
BA_ "GenSigStartValue" SG_ 2527679654 BMS_IstTemperatur_hoechste 254;
BA_ "GenSigSwitchedByIgnition" SG_ 2527679654 BMS_IstTemperatur_hoechste 0;
BA_ "Fehlerwert" SG_ 2527679654 BMS_IstTemperatur_hoechste 255;
BA_ "GenSigSendType" SG_ 2527679654 BMS_IstTemperatur_niedrigste 0;
BA_ "GenSigStartValue" SG_ 2527679654 BMS_IstTemperatur_niedrigste 254;
BA_ "GenSigSwitchedByIgnition" SG_ 2527679654 BMS_IstTemperatur_niedrigste 0;
BA_ "Fehlerwert" SG_ 2527679654 BMS_IstTemperatur_niedrigste 255;
BA_ "GenSigSendType" SG_ 2527679654 BMS_IstZellspannung_hoechste 0;
BA_ "GenSigStartValue" SG_ 2527679654 BMS_IstZellspannung_hoechste 4094;
BA_ "GenSigSwitchedByIgnition" SG_ 2527679654 BMS_IstZellspannung_hoechste 0;
BA_ "Fehlerwert" SG_ 2527679654 BMS_IstZellspannung_hoechste 4095;
BA_ "GenSigSendType" SG_ 2527679654 BMS_IstZellspannung_niedrigste 0;
BA_ "GenSigStartValue" SG_ 2527679654 BMS_IstZellspannung_niedrigste 4094;
BA_ "GenSigSwitchedByIgnition" SG_ 2527679654 BMS_IstZellspannung_niedrigste 0;
BA_ "Fehlerwert" SG_ 2527679654 BMS_IstZellspannung_niedrigste 4095;
BA_ "GenSigSendType" SG_ 207 BMS_20_BZ 0;
BA_ "GenSigFuncType" SG_ 207 BMS_20_BZ 1;
BA_ "GenSigSwitchedByIgnition" SG_ 207 BMS_20_BZ 0;
BA_ "GenSigSendType" SG_ 207 BMS_20_CRC 0;
BA_ "GenSigFuncType" SG_ 207 BMS_20_CRC 2;
BA_ "GenSigSwitchedByIgnition" SG_ 207 BMS_20_CRC 0;
BA_ "GenSigSendType" SG_ 207 BMS_ErwGrenzen_aktiv 0;
BA_ "GenSigSwitchedByIgnition" SG_ 207 BMS_ErwGrenzen_aktiv 0;
BA_ "GenSigSendType" SG_ 207 BMS_Fehler_HVBattAbschaltung 0;
BA_ "GenSigSwitchedByIgnition" SG_ 207 BMS_Fehler_HVBattAbschaltung 0;
BA_ "GenSigSendType" SG_ 207 BMS_Fehler_HVBattAbschaltung_Anf 0;
BA_ "GenSigSwitchedByIgnition" SG_ 207 BMS_Fehler_HVBattAbschaltung_Anf 0;
BA_ "GenSigSendType" SG_ 207 BMS_Fehler_Leistungsred 0;
BA_ "GenSigSwitchedByIgnition" SG_ 207 BMS_Fehler_Leistungsred 0;
BA_ "GenSigSendType" SG_ 207 BMS_Fehler_Notabschaltung_Crash 0;
BA_ "GenSigSwitchedByIgnition" SG_ 207 BMS_Fehler_Notabschaltung_Crash 0;
BA_ "GenSigSendType" SG_ 207 BMS_Fehlerstatus_HV_Schuetze 0;
BA_ "GenSigSwitchedByIgnition" SG_ 207 BMS_Fehlerstatus_HV_Schuetze 0;
BA_ "GenSigSendType" SG_ 207 BMS_HVIL_Status 0;
BA_ "GenSigSwitchedByIgnition" SG_ 207 BMS_HVIL_Status 0;
BA_ "Fehlerwert" SG_ 207 BMS_HVIL_Status 3;
BA_ "GenSigSendType" SG_ 207 BMS_IstModus 0;
BA_ "GenSigStartValue" SG_ 207 BMS_IstModus 7;
BA_ "GenSigSwitchedByIgnition" SG_ 207 BMS_IstModus 0;
BA_ "GenSigSendType" SG_ 207 BMS_Spannung 0;
BA_ "GenSigStartValue" SG_ 207 BMS_Spannung 4094;
BA_ "GenSigSwitchedByIgnition" SG_ 207 BMS_Spannung 0;
BA_ "Fehlerwert" SG_ 207 BMS_Spannung 4095;
BA_ "GenSigSendType" SG_ 207 BMS_Spannung_Zwischenkreis 0;
BA_ "GenSigStartValue" SG_ 207 BMS_Spannung_Zwischenkreis 4094;
BA_ "GenSigSwitchedByIgnition" SG_ 207 BMS_Spannung_Zwischenkreis 0;
BA_ "Fehlerwert" SG_ 207 BMS_Spannung_Zwischenkreis 4095;
BA_ "GenSigSendType" SG_ 207 BMS_Strom 0;
BA_ "GenSigStartValue" SG_ 207 BMS_Strom 32766;
BA_ "GenSigSwitchedByIgnition" SG_ 207 BMS_Strom 0;
BA_ "Fehlerwert" SG_ 207 BMS_Strom 32767;
BA_ "GenSigSendType" SG_ 2463978704 BMS_Max_Entladeleistung 0;
BA_ "GenSigStartValue" SG_ 2463978704 BMS_Max_Entladeleistung 8190;
BA_ "GenSigSwitchedByIgnition" SG_ 2463978704 BMS_Max_Entladeleistung 0;
BA_ "GenSigSendType" SG_ 2463978704 BMS_Max_Entladestrom 3;
BA_ "GenSigStartValue" SG_ 2463978704 BMS_Max_Entladestrom 8190;
BA_ "GenSigSwitchedByIgnition" SG_ 2463978704 BMS_Max_Entladestrom 0;
BA_ "GenSigSendType" SG_ 2463978704 BMS_Max_Ladeleistung 0;
BA_ "GenSigStartValue" SG_ 2463978704 BMS_Max_Ladeleistung 8190;
BA_ "GenSigSwitchedByIgnition" SG_ 2463978704 BMS_Max_Ladeleistung 0;
BA_ "GenSigSendType" SG_ 2463978704 BMS_Max_Ladestrom 0;
BA_ "GenSigStartValue" SG_ 2463978704 BMS_Max_Ladestrom 8190;
BA_ "GenSigSwitchedByIgnition" SG_ 2463978704 BMS_Max_Ladestrom 0;
BA_ "GenSigSendType" SG_ 2463978705 BMS_22_BZ 0;
BA_ "GenSigFuncType" SG_ 2463978705 BMS_22_BZ 1;
BA_ "GenSigSwitchedByIgnition" SG_ 2463978705 BMS_22_BZ 0;
BA_ "GenSigSendType" SG_ 2463978705 BMS_22_CRC 0;
BA_ "GenSigFuncType" SG_ 2463978705 BMS_22_CRC 2;
BA_ "GenSigSwitchedByIgnition" SG_ 2463978705 BMS_22_CRC 0;
BA_ "GenSigSendType" SG_ 2463978705 BMS_Ladezustand 0;
BA_ "GenSigStartValue" SG_ 2463978705 BMS_Ladezustand 2046;
BA_ "GenSigSwitchedByIgnition" SG_ 2463978705 BMS_Ladezustand 0;
BA_ "Fehlerwert" SG_ 2463978705 BMS_Ladezustand 2047;
BA_ "GenSigSendType" SG_ 2463978705 BMS_Nutzbare_EntladeEnergie 0;
BA_ "GenSigStartValue" SG_ 2463978705 BMS_Nutzbare_EntladeEnergie 65534;
BA_ "GenSigSwitchedByIgnition" SG_ 2463978705 BMS_Nutzbare_EntladeEnergie 0;
BA_ "Fehlerwert" SG_ 2463978705 BMS_Nutzbare_EntladeEnergie 65535;
BA_ "GenSigSendType" SG_ 2463978705 BMS_PerfInd_Entladen 0;
BA_ "GenSigStartValue" SG_ 2463978705 BMS_PerfInd_Entladen 1022;
BA_ "GenSigSwitchedByIgnition" SG_ 2463978705 BMS_PerfInd_Entladen 0;
BA_ "GenSigSendType" SG_ 2463978705 BMS_PerfInd_Laden 0;
BA_ "GenSigStartValue" SG_ 2463978705 BMS_PerfInd_Laden 1022;
BA_ "GenSigSwitchedByIgnition" SG_ 2463978705 BMS_PerfInd_Laden 0;
BA_ "GenSigSendType" SG_ 2463978705 BMS_Status_EoHVL_Heizer 0;
BA_ "GenSigSwitchedByIgnition" SG_ 2463978705 BMS_Status_EoHVL_Heizer 0;
BA_ "Fehlerwert" SG_ 2463978705 BMS_Status_EoHVL_Heizer 3;
BA_ "GenSigSendType" SG_ 2463978705 BMS_Warnung_Stuetzung_NV 0;
BA_ "GenSigStartValue" SG_ 2463978705 BMS_Warnung_Stuetzung_NV 6;
BA_ "GenSigSwitchedByIgnition" SG_ 2463978705 BMS_Warnung_Stuetzung_NV 0;
BA_ "Fehlerwert" SG_ 2463978705 BMS_Warnung_Stuetzung_NV 7;
BA_ "GenSigSendType" SG_ 2589283664 BMS_Balancing_Aktiv 0;
BA_ "GenSigSwitchedByIgnition" SG_ 2589283664 BMS_Balancing_Aktiv 0;
BA_ "GenSigSendType" SG_ 2589283664 BMS_Ladevorgang_aktiv 0;
BA_ "GenSigSwitchedByIgnition" SG_ 2589283664 BMS_Ladevorgang_aktiv 0;
BA_ "GenSigSendType" SG_ 2589283664 BMS_Max_Energie 0;
BA_ "GenSigStartValue" SG_ 2589283664 BMS_Max_Energie 8190;
BA_ "GenSigSwitchedByIgnition" SG_ 2589283664 BMS_Max_Energie 0;
BA_ "GenSigSendType" SG_ 2589283664 BMS_Max_Ladezustand 0;
BA_ "GenSigStartValue" SG_ 2589283664 BMS_Max_Ladezustand 2046;
BA_ "GenSigSwitchedByIgnition" SG_ 2589283664 BMS_Max_Ladezustand 0;
BA_ "GenSigSendType" SG_ 2589283664 BMS_Min_Ladezustand 0;
BA_ "GenSigStartValue" SG_ 2589283664 BMS_Min_Ladezustand 2046;
BA_ "GenSigSwitchedByIgnition" SG_ 2589283664 BMS_Min_Ladezustand 0;
BA_ "GenSigSendType" SG_ 2589283664 BMS_RIso_Ext 0;
BA_ "GenSigStartValue" SG_ 2589283664 BMS_RIso_Ext 4094;
BA_ "GenSigSwitchedByIgnition" SG_ 2589283664 BMS_RIso_Ext 0;
BA_ "Fehlerwert" SG_ 2589283664 BMS_RIso_Ext 4095;
BA_ "GenSigSendType" SG_ 2589283665 BMS_BattHeizung_VerbautStatus 0;
BA_ "GenSigSwitchedByIgnition" SG_ 2589283665 BMS_BattHeizung_VerbautStatus 0;
BA_ "GenSigSendType" SG_ 2589283665 BMS_Fehler_NTKreis 0;
BA_ "GenSigSwitchedByIgnition" SG_ 2589283665 BMS_Fehler_NTKreis 0;
BA_ "Fehlerwert" SG_ 2589283665 BMS_Fehler_NTKreis 1;
BA_ "GenSigSendType" SG_ 2589283665 BMS_Pumpe1_Ansteuerung 0;
BA_ "GenSigStartValue" SG_ 2589283665 BMS_Pumpe1_Ansteuerung 14;
BA_ "GenSigSwitchedByIgnition" SG_ 2589283665 BMS_Pumpe1_Ansteuerung 0;
BA_ "Fehlerwert" SG_ 2589283665 BMS_Pumpe1_Ansteuerung 15;
BA_ "GenSigSendType" SG_ 2589283665 BMS_Pumpe2_Ansteuerung 0;
BA_ "GenSigStartValue" SG_ 2589283665 BMS_Pumpe2_Ansteuerung 14;
BA_ "GenSigSwitchedByIgnition" SG_ 2589283665 BMS_Pumpe2_Ansteuerung 0;
BA_ "Fehlerwert" SG_ 2589283665 BMS_Pumpe2_Ansteuerung 15;
BA_ "GenSigSendType" SG_ 2589283665 BMS_RuecklaufTemperatur 0;
BA_ "GenSigStartValue" SG_ 2589283665 BMS_RuecklaufTemperatur 254;
BA_ "GenSigSwitchedByIgnition" SG_ 2589283665 BMS_RuecklaufTemperatur 0;
BA_ "Fehlerwert" SG_ 2589283665 BMS_RuecklaufTemperatur 255;
BA_ "GenSigSendType" SG_ 2589283665 BMS_SollVorlauftemperatur 0;
BA_ "GenSigStartValue" SG_ 2589283665 BMS_SollVorlauftemperatur 254;
BA_ "GenSigSwitchedByIgnition" SG_ 2589283665 BMS_SollVorlauftemperatur 0;
BA_ "Fehlerwert" SG_ 2589283665 BMS_SollVorlauftemperatur 255;
BA_ "GenSigSendType" SG_ 2589283665 BMS_Status_Ventil1 0;
BA_ "GenSigStartValue" SG_ 2589283665 BMS_Status_Ventil1 6;
BA_ "GenSigSwitchedByIgnition" SG_ 2589283665 BMS_Status_Ventil1 0;
BA_ "Fehlerwert" SG_ 2589283665 BMS_Status_Ventil1 7;
BA_ "GenSigSendType" SG_ 2589283665 BMS_Status_Ventil2 0;
BA_ "GenSigStartValue" SG_ 2589283665 BMS_Status_Ventil2 6;
BA_ "GenSigSwitchedByIgnition" SG_ 2589283665 BMS_Status_Ventil2 0;
BA_ "Fehlerwert" SG_ 2589283665 BMS_Status_Ventil2 7;
BA_ "GenSigSendType" SG_ 2589283665 BMS_Temperatur 0;
BA_ "GenSigStartValue" SG_ 2589283665 BMS_Temperatur 254;
BA_ "GenSigSwitchedByIgnition" SG_ 2589283665 BMS_Temperatur 0;
BA_ "Fehlerwert" SG_ 2589283665 BMS_Temperatur 255;
BA_ "GenSigSendType" SG_ 2589283665 BMS_Temperierung_Anf 0;
BA_ "GenSigStartValue" SG_ 2589283665 BMS_Temperierung_Anf 3;
BA_ "GenSigSwitchedByIgnition" SG_ 2589283665 BMS_Temperierung_Anf 0;
BA_ "GenSigSendType" SG_ 2589283665 BMS_VorlaufTemperatur 0;
BA_ "GenSigStartValue" SG_ 2589283665 BMS_VorlaufTemperatur 254;
BA_ "GenSigSwitchedByIgnition" SG_ 2589283665 BMS_VorlaufTemperatur 0;
BA_ "Fehlerwert" SG_ 2589283665 BMS_VorlaufTemperatur 255;
BA_ "GenSigSendType" SG_ 2589283760 BMS_Dauer_Entladeleistung 0;
BA_ "GenSigStartValue" SG_ 2589283760 BMS_Dauer_Entladeleistung 4094;
BA_ "GenSigSwitchedByIgnition" SG_ 2589283760 BMS_Dauer_Entladeleistung 0;
BA_ "GenSigSendType" SG_ 2589283760 BMS_Dauer_Ladeleistung 0;
BA_ "GenSigStartValue" SG_ 2589283760 BMS_Dauer_Ladeleistung 4094;
BA_ "GenSigSwitchedByIgnition" SG_ 2589283760 BMS_Dauer_Ladeleistung 0;
BA_ "GenSigSendType" SG_ 2589283760 BMS_Max_Spannung 0;
BA_ "GenSigStartValue" SG_ 2589283760 BMS_Max_Spannung 1022;
BA_ "GenSigSwitchedByIgnition" SG_ 2589283760 BMS_Max_Spannung 0;
BA_ "GenSigSendType" SG_ 2589283760 BMS_Min_Spannung 0;
BA_ "GenSigStartValue" SG_ 2589283760 BMS_Min_Spannung 1022;
BA_ "GenSigSwitchedByIgnition" SG_ 2589283760 BMS_Min_Spannung 0;
BA_ "GenSigSendType" SG_ 2589283762 BMS_eTM_KonditionierWunsch 0;
BA_ "GenSigSendType" SG_ 2589283762 BMS_PerfInd_EntladenPeak_Temp 0;
BA_ "GenSigStartValue" SG_ 2589283762 BMS_PerfInd_EntladenPeak_Temp 510;
BA_ "GenSigSwitchedByIgnition" SG_ 2589283762 BMS_PerfInd_EntladenPeak_Temp 0;
BA_ "Fehlerwert" SG_ 2589283762 BMS_PerfInd_EntladenPeak_Temp 511;
BA_ "GenSigSendType" SG_ 2589283762 BMS_PerfInd_LadenPeak_Temp 0;
BA_ "GenSigStartValue" SG_ 2589283762 BMS_PerfInd_LadenPeak_Temp 510;
BA_ "GenSigSwitchedByIgnition" SG_ 2589283762 BMS_PerfInd_LadenPeak_Temp 0;
BA_ "Fehlerwert" SG_ 2589283762 BMS_PerfInd_LadenPeak_Temp 511;
BA_ "GenSigSendType" SG_ 2589283762 BMS_SollVolumenstrom 0;
BA_ "GenSigStartValue" SG_ 2589283762 BMS_SollVolumenstrom 62;
BA_ "GenSigSwitchedByIgnition" SG_ 2589283762 BMS_SollVolumenstrom 0;
BA_ "Fehlerwert" SG_ 2589283762 BMS_SollVolumenstrom 63;
BA_ "GenSigSendType" SG_ 2589283762 BMS_TempStatus_Entladen 0;
BA_ "GenSigSwitchedByIgnition" SG_ 2589283762 BMS_TempStatus_Entladen 0;
BA_ "Fehlerwert" SG_ 2589283762 BMS_TempStatus_Entladen 7;
BA_ "GenSigSendType" SG_ 2589283762 BMS_TempStatus_Laden 0;
BA_ "GenSigSwitchedByIgnition" SG_ 2589283762 BMS_TempStatus_Laden 0;
BA_ "Fehlerwert" SG_ 2589283762 BMS_TempStatus_Laden 7;
BA_ "GenSigSendType" SG_ 2589283762 BMS_TMA_Betriebsart 0;
BA_ "GenSigStartValue" SG_ 2589283762 BMS_TMA_Betriebsart 30;
BA_ "GenSigSwitchedByIgnition" SG_ 2589283762 BMS_TMA_Betriebsart 0;
BA_ "Fehlerwert" SG_ 2589283762 BMS_TMA_Betriebsart 31;
BA_ "GenSigSendType" SG_ 2589283762 BMS_TMA_Kuehlkreis_Status 0;
BA_ "Fehlerwert" SG_ 2589283762 BMS_TMA_Kuehlkreis_Status 15;
BA_ "GenSigSendType" SG_ 2331595856 BMS_DC_Ladeschuetze_Ist 3;
BA_ "GenSigStartValue" SG_ 2331595856 BMS_DC_Ladeschuetze_Ist 6;
BA_ "GenSigSwitchedByIgnition" SG_ 2331595856 BMS_DC_Ladeschuetze_Ist 0;
BA_ "GenSigSendType" SG_ 2331595856 BMS_EnergieVorhalt 0;
BA_ "GenSigStartValue" SG_ 2331595856 BMS_EnergieVorhalt 65534;
BA_ "GenSigSwitchedByIgnition" SG_ 2331595856 BMS_EnergieVorhalt 0;
BA_ "Fehlerwert" SG_ 2331595856 BMS_EnergieVorhalt 65535;
BA_ "GenSigSendType" SG_ 2331595856 BMS_Hauptschuetze_Ist 3;
BA_ "GenSigStartValue" SG_ 2331595856 BMS_Hauptschuetze_Ist 6;
BA_ "GenSigSwitchedByIgnition" SG_ 2331595856 BMS_Hauptschuetze_Ist 0;
BA_ "GenSigSendType" SG_ 2331595856 BMS_Last_Chg_adeq_SOCswing_Day 0;
BA_ "GenSigSwitchedByIgnition" SG_ 2331595856 BMS_Last_Chg_adeq_SOCswing_Day 0;
BA_ "GenSigSendType" SG_ 2331595856 BMS_Last_Chg_adeq_SOCswing_Month 0;
BA_ "GenSigSwitchedByIgnition" SG_ 2331595856 BMS_Last_Chg_adeq_SOCswing_Month 0;
BA_ "GenSigSendType" SG_ 2331595856 BMS_Last_Chg_adeq_SOCswing_Year 0;
BA_ "GenSigSwitchedByIgnition" SG_ 2331595856 BMS_Last_Chg_adeq_SOCswing_Year 0;
BA_ "GenSigSendType" SG_ 2331595856 BMS_Max_UBE 0;
BA_ "GenSigStartValue" SG_ 2331595856 BMS_Max_UBE 65534;
BA_ "GenSigSwitchedByIgnition" SG_ 2331595856 BMS_Max_UBE 0;
BA_ "Fehlerwert" SG_ 2331595856 BMS_Max_UBE 65535;
BA_ "GenSigSendType" SG_ 2331595856 BMS_Nennspannung 0;
BA_ "GenSigStartValue" SG_ 2331595856 BMS_Nennspannung 2046;
BA_ "GenSigSwitchedByIgnition" SG_ 2331595856 BMS_Nennspannung 0;
BA_ "GenSigSendType" SG_ 2331595856 BMS_Range_Indikator 0;
BA_ "GenSigStartValue" SG_ 2331595856 BMS_Range_Indikator 2046;
BA_ "GenSigSwitchedByIgnition" SG_ 2331595856 BMS_Range_Indikator 0;
BA_ "Fehlerwert" SG_ 2331595856 BMS_Range_Indikator 2047;
BA_ "GenSigSendType" SG_ 2331595856 BMS_UBE 0;
BA_ "GenSigStartValue" SG_ 2331595856 BMS_UBE 65534;
BA_ "GenSigSwitchedByIgnition" SG_ 2331595856 BMS_UBE 0;
BA_ "Fehlerwert" SG_ 2331595856 BMS_UBE 65535;
BA_ "GenSigSendType" SG_ 2331595856 BMS_UBE_Indik_last_update_km 0;
BA_ "GenSigStartValue" SG_ 2331595856 BMS_UBE_Indik_last_update_km 1048574;
BA_ "GenSigSwitchedByIgnition" SG_ 2331595856 BMS_UBE_Indik_last_update_km 0;
BA_ "Fehlerwert" SG_ 2331595856 BMS_UBE_Indik_last_update_km 1048575;
BA_ "GenSigSendType" SG_ 2331595856 BMS_UBE_Indikator 0;
BA_ "GenSigStartValue" SG_ 2331595856 BMS_UBE_Indikator 2046;
BA_ "GenSigSwitchedByIgnition" SG_ 2331595856 BMS_UBE_Indikator 0;
BA_ "Fehlerwert" SG_ 2331595856 BMS_UBE_Indikator 2047;
BA_ "GenSigSendType" SG_ 2331595856 BMS_UBE_T 0;
BA_ "GenSigStartValue" SG_ 2331595856 BMS_UBE_T 65534;
BA_ "GenSigSwitchedByIgnition" SG_ 2331595856 BMS_UBE_T 0;
BA_ "Fehlerwert" SG_ 2331595856 BMS_UBE_T 65535;
BA_ "GenSigSendType" SG_ 2331595856 SOK_BMS_34_Signatur 0;
BA_ "GenSigFuncType" SG_ 2331595856 SOK_BMS_34_Signatur 15;
BA_ "GenSigSwitchedByIgnition" SG_ 2331595856 SOK_BMS_34_Signatur 0;
BA_REL_ "GenSigTimeoutTime" BU_SG_REL_ Gateway_Max SG_ 1442 BMS_Kapazitaet_02 5000;
BA_REL_ "GenSigTimeoutTime" BU_SG_REL_ Gateway_Max SG_ 687 BMS_As_Entladezaehler 500;
BA_REL_ "GenSigTimeoutTime" BU_SG_REL_ Gateway_Max SG_ 687 BMS_As_Entladezaehler_Ueberlauf 500;
BA_REL_ "GenSigTimeoutTime" BU_SG_REL_ Gateway_Max SG_ 1482 BMS_KundenWarnung 5000;
BA_REL_ "GenSigTimeoutTime" BU_SG_REL_ Gateway_Max SG_ 2527679654 BMS_IsoFehler 2000;
BA_REL_ "GenSigTimeoutTime" BU_SG_REL_ Gateway_Max SG_ 2527679654 BMS_IstTemperatur_hoechste 2000;
BA_REL_ "GenSigTimeoutTime" BU_SG_REL_ Gateway_Max SG_ 2527679654 BMS_IstTemperatur_niedrigste 2000;
BA_REL_ "GenSigTimeoutTime" BU_SG_REL_ Gateway_Max SG_ 2527679654 BMS_IstZellspannung_hoechste 2000;
BA_REL_ "GenSigTimeoutTime" BU_SG_REL_ Gateway_Max SG_ 2527679654 BMS_IstZellspannung_niedrigste 2000;
BA_REL_ "GenSigTimeoutTime" BU_SG_REL_ Gateway_Max SG_ 207 BMS_IstModus 500;
BA_REL_ "GenSigTimeoutTime" BU_SG_REL_ Gateway_Max SG_ 207 BMS_HVIL_Status 500;
BA_REL_ "GenSigTimeoutTime" BU_SG_REL_ Gateway_Max SG_ 207 BMS_Strom 500;
BA_REL_ "GenSigTimeoutTime" BU_SG_REL_ Gateway_Max SG_ 207 BMS_Fehler_Notabschaltung_Crash 500;
BA_REL_ "GenSigTimeoutTime" BU_SG_REL_ Gateway_Max SG_ 207 BMS_Spannung 500;
BA_REL_ "GenSigTimeoutTime" BU_SG_REL_ Gateway_Max SG_ 2463978704 BMS_Max_Entladestrom 1000;
BA_REL_ "GenSigTimeoutTime" BU_SG_REL_ Gateway_Max SG_ 2463978704 BMS_Max_Ladestrom 1000;
BA_REL_ "GenSigTimeoutTime" BU_SG_REL_ Gateway_Max SG_ 2463978704 BMS_Max_Entladeleistung 1000;
BA_REL_ "GenSigTimeoutTime" BU_SG_REL_ Gateway_Max SG_ 2463978704 BMS_Max_Ladeleistung 1000;
BA_REL_ "GenSigTimeoutTime" BU_SG_REL_ Gateway_Max SG_ 2463978705 BMS_22_CRC 1000;
BA_REL_ "GenSigTimeoutTime" BU_SG_REL_ Gateway_Max SG_ 2463978705 BMS_22_BZ 1000;
BA_REL_ "GenSigTimeoutTime" BU_SG_REL_ Gateway_Max SG_ 2463978705 BMS_Warnung_Stuetzung_NV 1000;
BA_REL_ "GenSigTimeoutTime" BU_SG_REL_ Gateway_Max SG_ 2463978705 BMS_Ladezustand 1000;
BA_REL_ "GenSigTimeoutTime" BU_SG_REL_ Gateway_Max SG_ 2463978705 BMS_PerfInd_Entladen 1000;
BA_REL_ "GenSigTimeoutTime" BU_SG_REL_ Gateway_Max SG_ 2463978705 BMS_Nutzbare_EntladeEnergie 1000;
BA_REL_ "GenSigTimeoutTime" BU_SG_REL_ Gateway_Max SG_ 2589283664 BMS_Balancing_Aktiv 5000;
BA_REL_ "GenSigTimeoutTime" BU_SG_REL_ Gateway_Max SG_ 2589283664 BMS_Ladevorgang_aktiv 5000;
BA_REL_ "GenSigTimeoutTime" BU_SG_REL_ Gateway_Max SG_ 2589283664 BMS_RIso_Ext 5000;
BA_REL_ "GenSigTimeoutTime" BU_SG_REL_ Gateway_Max SG_ 2589283664 BMS_Min_Ladezustand 5000;
BA_REL_ "GenSigTimeoutTime" BU_SG_REL_ Gateway_Max SG_ 2589283664 BMS_Max_Energie 5000;
BA_REL_ "GenSigTimeoutTime" BU_SG_REL_ Gateway_Max SG_ 2589283664 BMS_Max_Ladezustand 5000;
BA_REL_ "GenSigTimeoutTime" BU_SG_REL_ Gateway_Max SG_ 2589283665 BMS_Temperatur 5000;
BA_REL_ "GenSigTimeoutTime" BU_SG_REL_ Gateway_Max SG_ 2589283760 BMS_Max_Spannung 5000;
BA_REL_ "GenSigTimeoutTime" BU_SG_REL_ Gateway_Max SG_ 2589283760 BMS_Min_Spannung 5000;
BA_REL_ "GenSigTimeoutTime" BU_SG_REL_ Gateway_Max SG_ 2589283760 BMS_Dauer_Entladeleistung 5000;
BA_REL_ "GenSigTimeoutTime" BU_SG_REL_ Gateway_Max SG_ 2589283760 BMS_Dauer_Ladeleistung 5000;
BA_REL_ "GenSigTimeoutTime" BU_SG_REL_ Gateway_Max SG_ 2589283762 BMS_TMA_Betriebsart 5000;
BA_REL_ "GenSigTimeoutTime" BU_SG_REL_ Gateway_Max SG_ 2331595856 BMS_UBE 1000;
BA_REL_ "GenSigTimeoutTime" BU_SG_REL_ Gateway_Max SG_ 2331595856 BMS_UBE_T 1000;
BA_REL_ "GenSigTimeoutTime" BU_SG_REL_ Gateway_Max SG_ 2331595856 BMS_Max_UBE 1000;
BA_REL_ "GenSigTimeoutTime" BU_SG_REL_ Gateway_Max SG_ 2331595856 BMS_UBE_Indikator 1000;
BA_REL_ "GenSigTimeoutTime" BU_SG_REL_ Gateway_Max SG_ 2331595856 BMS_UBE_Indik_last_update_km 1000;
BA_REL_ "GenSigTimeoutTime" BU_SG_REL_ Gateway_Max SG_ 2331595856 BMS_Last_Chg_adeq_SOCswing_Day 1000;
BA_REL_ "GenSigTimeoutTime" BU_SG_REL_ Gateway_Max SG_ 2331595856 BMS_Last_Chg_adeq_SOCswing_Month 1000;
BA_REL_ "GenSigTimeoutTime" BU_SG_REL_ Gateway_Max SG_ 2331595856 BMS_Last_Chg_adeq_SOCswing_Year 1000;
BA_REL_ "GenSigTimeoutTime" BU_SG_REL_ Gateway_Max SG_ 2331595856 BMS_EnergieVorhalt 1000;
BA_REL_ "GenSigTimeoutTime" BU_SG_REL_ Gateway_Max SG_ 2331595856 BMS_Range_Indikator 1000;
BA_REL_ "GenSigTimeoutTime" BU_SG_REL_ Gateway_Max SG_ 2331595856 SOK_BMS_34_Signatur 1000;
BA_REL_ "GenSigTimeoutTime" BU_SG_REL_ Klima SG_ 64 Airbag_01_CRC 500;
BA_REL_ "GenSigTimeoutTime" BU_SG_REL_ Klima SG_ 64 Airbag_01_BZ 500;
BA_REL_ "GenSigTimeoutTime" BU_SG_REL_ Klima SG_ 64 AB_Crash_Int 500;
BA_REL_ "GenSigTimeoutTime" BU_SG_REL_ Klima SG_ 64 AB_Stellgliedtest 500;
BA_REL_ "GenSigTimeoutTime" BU_SG_REL_ Klima SG_ 64 AB_Deaktivierung_HV 500;
BA_REL_ "GenSigTimeoutTime" BU_SG_REL_ Klima SG_ 64 AB_Belegung_VF 500;
BA_REL_ "GenSigTimeoutTime" BU_SG_REL_ Klima SG_ 1312 AB_Belegung_VB 2000;
BA_REL_ "GenSigTimeoutTime" BU_SG_REL_ Klima SG_ 1312 AB_Abschaltanf_SIH_BF 2000;
BA_REL_ "GenSigTimeoutTime" BU_SG_REL_ Klima SG_ 1312 AB_Gurtschloss_FA 2000;
BA_REL_ "GenSigTimeoutTime" BU_SG_REL_ Klima SG_ 1312 AB_Gurtschloss_BF 2000;
BA_REL_ "GenSigTimeoutTime" BU_SG_REL_ Klima SG_ 1312 AB_Gurtschloss_Reihe2_FA 2000;
BA_REL_ "GenSigTimeoutTime" BU_SG_REL_ Klima SG_ 1312 AB_Gurtschloss_Reihe2_MI 2000;
BA_REL_ "GenSigTimeoutTime" BU_SG_REL_ Klima SG_ 1312 AB_Gurtschloss_Reihe2_BF 2000;
BA_REL_ "GenSigTimeoutTime" BU_SG_REL_ Klima SG_ 1312 AB_Gurtschloss_Reihe3_FA 2000;
BA_REL_ "GenSigTimeoutTime" BU_SG_REL_ Klima SG_ 1312 AB_Gurtschloss_Reihe3_MI 2000;
BA_REL_ "GenSigTimeoutTime" BU_SG_REL_ Klima SG_ 1312 AB_Gurtschloss_Reihe3_BF 2000;
BA_REL_ "GenSigTimeoutTime" BU_SG_REL_ Klima SG_ 1349 AB_Gurtwarn_Reihe2_FA 2000;
BA_REL_ "GenSigTimeoutTime" BU_SG_REL_ Klima SG_ 1349 AB_Gurtwarn_Reihe2_BF 2000;
BA_REL_ "GenSigTimeoutTime" BU_SG_REL_ Klima SG_ 1349 AB_Gurtwarn_Reihe2_MI 2000;
BA_REL_ "GenSigTimeoutTime" BU_SG_REL_ Klima SG_ 1349 AB_Belegung_VF_ext 2000;
BA_REL_ "GenSigTimeoutTime" BU_SG_REL_ Klima SG_ 1349 AB_SBR_hinten_verbau 2000;
BA_REL_ "GenSigTimeoutTime" BU_SG_REL_ Klima SG_ 2536726528 BAP_ClimateDiag_ASG_01_Header 800;
BA_REL_ "GenSigTimeoutTime" BU_SG_REL_ Klima SG_ 2536702208 BAP_Klima1_ASG_01_Header 800;
BA_REL_ "GenSigTimeoutTime" BU_SG_REL_ Klima SG_ 2536702464 BAP_Klima2_ASG_01_Header 800;
BA_REL_ "GenSigTimeoutTime" BU_SG_REL_ Klima SG_ 2536702466 BAP_Klima2_ASG_03_Header 800;
BA_REL_ "GenSigTimeoutTime" BU_SG_REL_ Klima SG_ 2536702468 BAP_Klima2_ASG_05_Header 800;
BA_REL_ "GenSigTimeoutTime" BU_SG_REL_ Klima SG_ 2536718848 BAP_KlimaMaster_ASG_01_Header 800;
BA_REL_ "GenSigTimeoutTime" BU_SG_REL_ Klima SG_ 2536718849 BAP_KlimaMaster_ASG_02_Header 800;
BA_REL_ "GenSigTimeoutTime" BU_SG_REL_ Klima SG_ 2536718850 BAP_KlimaMaster_ASG_03_Header 800;
BA_REL_ "GenSigTimeoutTime" BU_SG_REL_ Klima SG_ 2536718851 BAP_KlimaMaster_ASG_04_Header 800;
BA_REL_ "GenSigTimeoutTime" BU_SG_REL_ Klima SG_ 1626 BCM1_Rueckfahrlicht_Schalter 5000;
BA_REL_ "GenSigTimeoutTime" BU_SG_REL_ Klima SG_ 2527679637 BCM_Defrost_Taste 5000;
BA_REL_ "GenSigTimeoutTime" BU_SG_REL_ Klima SG_ 2527679637 BCM_HSH_Taste 5000;
BA_REL_ "GenSigTimeoutTime" BU_SG_REL_ Klima SG_ 2527679637 BCM_FSH_Taste 5000;
BA_REL_ "GenSigTimeoutTime" BU_SG_REL_ Klima SG_ 2527679637 LTMs_01_alt 5000;
BA_REL_ "GenSigTimeoutTime" BU_SG_REL_ Klima SG_ 2463978609 HSH_Status 2000;
BA_REL_ "GenSigTimeoutTime" BU_SG_REL_ Klima SG_ 2463978609 KRH_Stufe_LED_re 2000;
BA_REL_ "GenSigTimeoutTime" BU_SG_REL_ Klima SG_ 2463978609 KRH_Stufe_LED_li 2000;
BA_REL_ "GenSigTimeoutTime" BU_SG_REL_ Klima SG_ 2463978609 SIL_Stufe_LED_re 2000;
BA_REL_ "GenSigTimeoutTime" BU_SG_REL_ Klima SG_ 2463978609 SIL_Stufe_LED_li 2000;
BA_REL_ "GenSigTimeoutTime" BU_SG_REL_ Klima SG_ 1163 NVEM_Last_Anf 1000;
BA_REL_ "GenSigTimeoutTime" BU_SG_REL_ Klima SG_ 1163 NVEM_STH_ZielzeitLang 1000;
BA_REL_ "GenSigTimeoutTime" BU_SG_REL_ Klima SG_ 2463978850 NVEM2_VerbrZustandsAnf 1000;
BA_REL_ "GenSigTimeoutTime" BU_SG_REL_ Klima SG_ 1635 NVEM_Abschaltstufe 1000;
BA_REL_ "GenSigTimeoutTime" BU_SG_REL_ Klima SG_ 1635 BEM_STH_Zielzeit 1000;
BA_REL_ "GenSigTimeoutTime" BU_SG_REL_ Klima SG_ 1635 BEM_Red_Innengeblaese 1000;
BA_REL_ "GenSigTimeoutTime" BU_SG_REL_ Klima SG_ 1635 BEM_STH_Einschaltverbot 1000;
BA_REL_ "GenSigTimeoutTime" BU_SG_REL_ Klima SG_ 1482 BMS_KundenWarnung 5000;
BA_REL_ "GenSigTimeoutTime" BU_SG_REL_ Klima SG_ 207 BMS_Spannung 500;
BA_REL_ "GenSigTimeoutTime" BU_SG_REL_ Klima SG_ 2589283665 BMS_Temperierung_Anf 5000;
BA_REL_ "GenSigTimeoutTime" BU_SG_REL_ Klima SG_ 2589283665 BMS_Status_Ventil1 5000;
BA_REL_ "GenSigTimeoutTime" BU_SG_REL_ Klima SG_ 2589283665 BMS_Status_Ventil2 5000;
BA_REL_ "GenSigTimeoutTime" BU_SG_REL_ Klima SG_ 2589283665 BMS_Pumpe1_Ansteuerung 5000;
BA_REL_ "GenSigTimeoutTime" BU_SG_REL_ Klima SG_ 2589283665 BMS_Pumpe2_Ansteuerung 5000;
BA_REL_ "GenSigTimeoutTime" BU_SG_REL_ Klima SG_ 2589283665 BMS_VorlaufTemperatur 5000;
BA_REL_ "GenSigTimeoutTime" BU_SG_REL_ Klima SG_ 2589283665 BMS_Temperatur 5000;
BA_REL_ "GenSigTimeoutTime" BU_SG_REL_ Klima SG_ 2589283665 BMS_SollVorlauftemperatur 5000;
BA_REL_ "GenSigTimeoutTime" BU_SG_REL_ Klima SG_ 2589283665 BMS_RuecklaufTemperatur 5000;
VAL_ 64 AB_RGS_Anst 4 "aktiv_Niveau_1" 5 "aktiv_Niveau_2" 6 "aktiv_Niveau_3" 7 "aktiv_Niveau_4" 8 "deaktiviert" ;
VAL_ 64 AB_Front_Crash 0 "kein_Front_Crash" 1 "Front_Crash" ;
VAL_ 64 AB_Heck_Crash 0 "kein_Heck_Crash" 1 "Heck_Crash" ;
VAL_ 64 AB_SF_Crash 0 "kein_Seiten_Crash_Fahrer" 1 "Seiten_Crash_Fahrer" ;
VAL_ 64 AB_SB_Crash 0 "kein_Seiten_Crash_Beifahrer" 1 "Seiten_Crash_Beifahrer" ;
VAL_ 64 AB_Rollover_Crash 0 "kein_Rollover" 1 "Rollover" ;
VAL_ 64 AB_Crash_Int 0 "kein_Crash" 1 "Crash_Intensitaet_1" 2 "Crash_Intensitaet_2_(nur_Stellgliedtest_MLB_B8)" 3 "Crash_Intensitaet_2_(nur_D4_C7_Colorado_NF_PAG__Crash_im_MLB_B8)" 4 "Crash_Intensitaet_3_(alt_VW/AUDI__Stellgliedtest_MLB_B8)" 5 "Crash_Intensitaet_3_(alt_PAG)" 7 "Crash_Intensitaet_3" ;
VAL_ 64 AB_Lampe 0 "Aus" 1 "Ein" ;
VAL_ 64 AB_Deaktiviert 0 "aktiv" 1 "deaktiviert" ;
VAL_ 64 AB_VB_deaktiviert 0 "Beifahrerairbag_aktiv" 1 "Beifahrerairbag_deaktiviert" ;
VAL_ 64 AB_Systemfehler 0 "kein_Fehler" 1 "Airbag_Systemfehler" ;
VAL_ 64 AB_Diagnose 0 "nicht_in_Diagnose" 1 "in_Diagnose" ;
VAL_ 64 AB_Stellgliedtest 0 "nicht_im_Stellgliedtest" 1 "Airbag_im_Stellgliedtest" ;
VAL_ 64 AB_Erh_Auf_VB 0 "keine_Anzeige" 1 "Beifahrerairbag_deaktiviert" 2 "Beifahrerairbag_aktiviert" 3 "nicht_definiert" ;
VAL_ 64 AB_Gurtwarn_VF 0 "keine_Warnung" 1 "Gurtwarnung_ausloesen" ;
VAL_ 64 AB_Gurtwarn_VB 0 "keine_Warnung" 1 "Gurtwarnung_ausloesen" ;
VAL_ 64 AB_Anzeige_Fussg 0 "keine_FSG_Aktion_ausgeloest" 1 "Motorhaube_offen" 2 "Systemfehler" ;
VAL_ 64 AB_Texte_AKS 0 "keine_AKS_Ausloesung" 1 "AKS_ausgeloest" 2 "AKS_Systemfehler" ;
VAL_ 64 AB_PAO_Leuchte_Anf 0 "Leuchte_ausschalten" 1 "Leuchte_einschalten" ;
VAL_ 64 AB_MKB_gueltig 0 "Multikollisionsbremsung_nicht_freigeschaltet" 1 "Multikollisionsbremsung_freigeschaltet" ;
VAL_ 64 AB_MKB_Anforderung 0 "Multikollisionsbremsung_nicht_angefordert" 1 "Multikollisionsbremsung_angefordert" ;
VAL_ 64 AB_Versorgungsspannung 0 "plausibel" 1 "unplausibel" ;
VAL_ 64 AB_Deaktivierung_HV 0 "keine_Deaktivierung" 1 "Deaktivierung_1" 2 "Deaktivierung_2" 3 "Deaktivierung_3" 4 "Deaktivierung_4" 5 "Deaktivierung_5" 6 "Deaktivierung_6" 7 "Fehler" ;
VAL_ 64 AB_EDR_Trigger 0 "No_Event" 1 "Start_Event" 2 "NonDeployment_Event" 3 "Deployment_Event" ;
VAL_ 64 AB_Belegung_VF 0 "nicht_verfuegbar" 1 "Fehler" 2 "nicht_belegt" 3 "belegt" ;
VAL_ 64 AB_Gurtschloss_FA_ext 0 "nicht_verbaut" 1 "reserviert" 2 "nicht_gesteckt" 3 "gesteckt" 4 "dauerhaft_nicht_gesteckt" 5 "dauerhaft_gesteckt" 6 "Init" 7 "Fehler" ;
VAL_ 64 AB_Gurtschloss_FA_ext_aktiv 0 "inaktiv" 1 "aktiv" ;
VAL_ 64 AB_eCS_Error 0 "keine_Anzeige" 1 "Anzeige_anfordern" ;
VAL_ 64 ASM_Masterzeit_02 255 "Init" ;
VAL_ 1312 LoGeWa_Event_Kombiwarnung 0 "Init" 1 "Unfall" 2 "Traktionsverlust" 3 "Panne" 4 "Sichtbehinderung" 5 "Aquaplaning" ;
VAL_ 1312 AB_Anforderung_eCall 0 "keine_Anforderung" 1 "Anforderung" ;
VAL_ 1312 AB_Anprall_Seite_Beifahrer 0 "kein_Anprall" 1 "Anprall_erkannt" ;
VAL_ 1312 AB_Anprall_Rollover 0 "kein_Anprall" 1 "Anprall_erkannt" ;
VAL_ 1312 AB_Anprall_FGS 0 "kein_Anprall" 1 "Anprall_erkannt" ;
VAL_ 1312 AB_Anprall_Front_Beifahrer 0 "kein_Anprall" 1 "Anprall_erkannt" ;
VAL_ 1312 AB_Anprall_Front_Fahrer 0 "kein_Anprall" 1 "Anprall_erkannt" ;
VAL_ 1312 AB_Anprall_Heck_Beifahrer 0 "kein_Anprall" 1 "Anprall_erkannt" ;
VAL_ 1312 AB_Anprall_Heck_Fahrer 0 "kein_Anprall" 1 "Anprall_erkannt" ;
VAL_ 1312 AB_Wickelklappung_Reihe2_MI 0 "nicht_verbaut" 1 "nicht_verfuegbar__Fehler_oder_Init" 2 "nicht_verriegelt" 3 "verriegelt" ;
VAL_ 1312 AB_Belegung_VB 0 "nicht_verfuegbar" 1 "Fehler" 2 "nicht_belegt" 3 "belegt" ;
VAL_ 1312 AB_Abschaltanf_SIH_BF 0 "Normalbetrieb" 1 "Abschaltung_angefordert" ;
VAL_ 1312 AB_Anprall_Seite_Fahrer 0 "kein_Anprall" 1 "Anprall_erkannt" ;
VAL_ 1312 SC_PAO_Schriftzug_Anf 0 "LED aus" 1 "LED an" 2 "LED blinken" 3 "reserviert" ;
VAL_ 1312 SC_PAO_ON_Anf 0 "LED aus" 1 "LED an" 2 "LED blinken" 3 "reserviert" ;
VAL_ 1312 SC_PAO_OFF_Anf 0 "LED aus" 1 "LED an" 2 "LED blinken" 3 "reserviert" ;
VAL_ 1312 AB_Crashschwere 0 "kein_Ereignis" 1 "Crashschwere_1" 2 "Crashschwere_2" 3 "Crashschwere_3" 4 "Crashschwere_4" 5 "Crashschwere_5" 6 "Crashschwere_2_bis_5" 7 "Fehler" ;
VAL_ 1312 AB_Anforderung_USM 0 "keine_Anforderung" 1 "Anforderung" ;
VAL_ 1312 AB_Gurtschloss_FA 0 "nicht_verbaut" 1 "nicht_verfügbar (Fehler oder Init)" 2 "nicht_gesteckt" 3 "gesteckt" ;
VAL_ 1312 AB_Gurtschloss_BF 0 "nicht_verbaut" 1 "nicht_verfügbar (Fehler oder Init)" 2 "nicht_gesteckt" 3 "gesteckt" ;
VAL_ 1312 AB_Gurtschloss_Reihe2_FA 0 "nicht_verbaut" 1 "nicht_verfügbar (Fehler oder Init)" 2 "nicht_gesteckt" 3 "gesteckt" ;
VAL_ 1312 AB_Gurtschloss_Reihe2_MI 0 "nicht_verbaut" 1 "nicht_verfügbar (Fehler oder Init)" 2 "nicht_gesteckt" 3 "gesteckt" ;
VAL_ 1312 AB_Gurtschloss_Reihe2_BF 0 "nicht_verbaut" 1 "nicht_verfügbar (Fehler oder Init)" 2 "nicht_gesteckt" 3 "gesteckt" ;
VAL_ 1312 AB_Gurtschloss_Reihe3_FA 0 "nicht_verbaut" 1 "nicht_verfügbar (Fehler oder Init)" 2 "nicht_gesteckt" 3 "gesteckt" ;
VAL_ 1312 AB_Gurtschloss_Reihe3_MI 0 "nicht_verbaut" 1 "nicht_verfügbar (Fehler oder Init)" 2 "nicht_gesteckt" 3 "gesteckt" ;
VAL_ 1312 AB_Gurtschloss_Reihe3_BF 0 "nicht_verbaut" 1 "nicht_verfügbar (Fehler oder Init)" 2 "nicht_gesteckt" 3 "gesteckt" ;
VAL_ 1312 AB_Sitzpos_Sens_FA 0 "nicht verfügbar" 1 "Fehler" 2 "Sitz nicht vorne" 3 "Sitz vorne" ;
VAL_ 1312 AB_Sitzpos_Sens_BF 0 "nicht verfügbar" 1 "Fehler" 2 "Sitz nicht vorne" 3 "Sitz vorne" ;
VAL_ 1312 AB_Wickelklappung_Reihe2_BF 0 "nicht_verbaut" 1 "nicht_verfuegbar__Fehler_oder_Init" 2 "nicht_verriegelt" 3 "verriegelt" ;
VAL_ 1312 AB_Wickelklappung_Reihe2_FA 0 "nicht_verbaut" 1 "nicht_verfuegbar__Fehler_oder_Init" 2 "nicht_verriegelt" 3 "verriegelt" ;
VAL_ 1349 AB_Anprall_Front 0 "kein_Anprall" 1 "Anprall_erkannt" ;
VAL_ 1349 AB_Anprall_Heck 0 "kein_Anprall" 1 "Anprall_erkannt" ;
VAL_ 1349 AB_Gurtwarn_Reihe4_FA 0 "nicht_verbaut" 1 "keine_Gurtwarnung_Sitz_leer" 2 "keine_Gurtwarnung_Sitz_belegt" 3 "Gurtwarnung_Sitz_belegt" ;
VAL_ 1349 AB_Gurtwarn_Reihe4_BF 0 "nicht_verbaut" 1 "keine_Gurtwarnung_Sitz_leer" 2 "keine_Gurtwarnung_Sitz_belegt" 3 "Gurtwarnung_Sitz_belegt" ;
VAL_ 1349 AB_Gurtwarn_Reihe4_MI 0 "nicht_verbaut" 1 "keine_Gurtwarnung_Sitz_leer" 2 "keine_Gurtwarnung_Sitz_belegt" 3 "Gurtwarnung_Sitz_belegt" ;
VAL_ 1349 AB_Gurtwarn_Reihe2_FA 0 "nicht_verbaut" 1 "keine_Gurtwarnung_Sitz_leer" 2 "keine_Gurtwarnung_Sitz_belegt" 3 "Gurtwarnung_Sitz_belegt" ;
VAL_ 1349 AB_Gurtwarn_Reihe2_BF 0 "nicht_verbaut" 1 "keine_Gurtwarnung_Sitz_leer" 2 "keine_Gurtwarnung_Sitz_belegt" 3 "Gurtwarnung_Sitz_belegt" ;
VAL_ 1349 AbstWarn_MV_FAS_Fkt_Status 0 "Init" 1 "Funktion_Ist_Ein" 2 "Funktion_Ist_Aus" 3 "Fehler" ;
VAL_ 1349 WarnBrems_Charisma_Status 0 "Init" 1 "verfügbar" 2 "nicht verfügbar" 3 "asynchron durch Fahrerwunsch" ;
VAL_ 1349 WarnBrems_Charisma_FahrPr 0 "keine_Funktion" 1 "Programm_1" 2 "Programm_2" 3 "Programm_3" 4 "Programm_4" 5 "Programm_5" 6 "Programm_6" 7 "Programm_7" 8 "Programm_8" 9 "Programm_9" 10 "Programm_10" 11 "Programm_11" 12 "Programm_12" 13 "Programm_13" 14 "Programm_14" 15 "Programm_15" ;
VAL_ 1349 AB_Gurtwarn_Reihe2_MI 0 "nicht_verbaut" 1 "keine_Gurtwarnung_Sitz_leer" 2 "keine_Gurtwarnung_Sitz_belegt" 3 "Gurtwarnung_Sitz_belegt" ;
VAL_ 1349 AB_Gurtwarn_Reihe3_FA 0 "nicht_verbaut" 1 "keine_Gurtwarnung_Sitz_leer" 2 "keine_Gurtwarnung_Sitz_belegt" 3 "Gurtwarnung_Sitz_belegt" ;
VAL_ 1349 AB_Gurtwarn_Reihe3_MI 0 "nicht_verbaut" 1 "keine_Gurtwarnung_Sitz_leer" 2 "keine_Gurtwarnung_Sitz_belegt" 3 "Gurtwarnung_Sitz_belegt" ;
VAL_ 1349 AB_Gurtwarn_Reihe3_BF 0 "nicht_verbaut" 1 "keine_Gurtwarnung_Sitz_leer" 2 "keine_Gurtwarnung_Sitz_belegt" 3 "Gurtwarnung_Sitz_belegt" ;
VAL_ 1349 LGI_FAS_Fkt_Status 0 "Init" 1 "Funktion_Ist_Ein" 2 "Funktion_Ist_Aus" 3 "Fehler" ;
VAL_ 1349 PreCrash_FAS_Fkt_Status 0 "Init" 1 "Funktion_Ist_Ein" 2 "Funktion_Ist_Aus" 3 "Fehler" ;
VAL_ 1349 AB_Belegung_VF_ext 0 "nicht_verbaut" 1 "reserviert" 2 "nicht_belegt" 3 "belegt" 4 "dauerhaft_nicht_belegt" 5 "dauerhaft_belegt" 6 "Init" 7 "Fehler" ;
VAL_ 1349 AB_SBR_hinten_verbau 0 "ohne_SBR_hinten" 1 "mit_SBR_hinten" 2 "nicht_definiert" 3 "Init" ;
VAL_ 1349 AB_Belegung_VF_ext_aktiv 0 "inaktiv" 1 "aktiv" ;
VAL_ 1349 AWV_Einstellung_System_ASG 0 "deaktiviert" 1 "aktiviert" ;
VAL_ 1349 AWV_Einstellung_Warnung_ASG 0 "Aus" 1 "Setting_2" 2 "Setting_3" 3 "Setting_4" 4 "Setting_5" 5 "Ein" ;
VAL_ 1349 SC_PreSense_Modus_Warnung_NV 0 "Aus" 1 "Setting_2" 2 "Setting_3" 3 "Setting_4" 4 "Setting_5" 5 "Ein" ;
VAL_ 1349 SC_PreSense_Modus_Warnung_MV 0 "Aus" 1 "Setting_2" 2 "Setting_3" 3 "Setting_4" 4 "Setting_5" 5 "Ein" ;
VAL_ 1349 SC_PreSense_Modus_System_MV 0 "deaktiviert" 1 "aktiviert" ;
VAL_ 1349 SC_PreSense_Modus_System_NV 0 "deaktiviert" 1 "aktiviert" ;
VAL_ 1349 SC_PreSense_Modus_System_KAS 0 "deaktiviert" 1 "aktiviert" ;
VAL_ 1626 BCM_Bremsbelag_Sensor 0 "OK" 1 "Bremsbelag_unter_min" ;
VAL_ 1626 BCM_Bremsfluessigkeit_Sensor 0 "OK" 1 "Bremsfluessigkeit_unter_min" ;
VAL_ 1626 BCM1_Licht_Warn 0 "OK" 1 "Lichtwarnung_aktiv" ;
VAL_ 1626 BCM_Waschwasser_Sensor 0 "OK" 1 "Waschwasser_unter_min" ;
VAL_ 1626 BCM_Kuehlmittel_Sensor 0 "OK" 1 "Kuehlmittel_unter_min" ;
VAL_ 1626 BCM1_Kl_15_HW_erkannt 1 "Klemme 15 erkannt" ;
VAL_ 1626 BCM1_Kl_15_Sig_HW_erkannt 0 "KL15_HW_Signal_von_BCM1_nicht_erkannt" 1 "KL15_HW_Signal_von_BCM1_erkannt" ;
VAL_ 1626 BCM_Kuehlmittel_Sensor_02 0 "OK" 1 "Kuehlmittel_unter_min" ;
VAL_ 1626 BCM1_Hinweis_Lichtnachlauf 0 "inaktiv" 1 "aktiv" ;
VAL_ 1626 BCM_Offroad_Taste 0 "Taster_nicht_betaetigt" 1 "Taster_betaetigt" ;
VAL_ 1626 BCM_Charisma_Taste2 0 "nicht_betaetigt" 1 "betaetigt" ;
VAL_ 1626 BCM_Hybrid_StSt_Taste_Fehler 0 "kein_Fehler_StSt_Taster" 1 "Fehler_StSt_Taster" ;
VAL_ 1626 BCM_Hybrid_StartStopp_Taste 0 "nicht_betaetigt" 1 "betaetigt" ;
VAL_ 1626 BCM1_Warnblink_Taster 0 "nicht_betaetigt" 1 "betaetigt" ;
VAL_ 1626 BCM1_Valet_Parking_Taster 0 "nicht_betaetigt" 1 "betaetigt" ;
VAL_ 1626 BCM1_LDS_Stellung 0 "Init" 1 "Stellung_0" 2 "Auto" 3 "Standlicht" 4 "Abblendlicht" 7 "Fehler" ;
VAL_ 1626 BCM1_Rueckfahrlicht_Schalter 0 "nicht_betaetigt" 1 "betaetigt" ;
VAL_ 1626 BCM1_MH_Schalter 0 "MH_geschlossen" 1 "MH_offen" ;
VAL_ 1626 BCM1_MH_WIV_Schalter 0 "MH_geschlossen" 1 "MH_offen" ;
VAL_ 1626 BCM_Eco_Charisma_Taste 0 "nicht_betaetigt" 1 "betaetigt" ;
VAL_ 1626 BCM1_NV_Taster 0 "Taster_nicht_betaetigt" 1 "Taster_betaetigt" ;
VAL_ 1626 BCM1_AFS_Lampe 0 "Aus" 1 "Ein" ;
VAL_ 1626 BCM1_Reisemodus_Texte 0 "keine_Anzeige" 1 "Umschaltung_auf_Linksverkehr_aktiv" 2 "Umschaltung_auf_Rechtsverkehr_aktiv" ;
VAL_ 1626 BCM1_Lichtwarn_Texte 0 "keine_Warnung" 1 "Standlichtwarnung" 2 "Parklichtwarnung" 3 "Nebelschlusslichtwarnung" ;
VAL_ 1626 Gong_TFL_Umschaltung 0 "kein_Gong" 1 "Gong_einmalig" ;
VAL_ 1626 BCM_ValetTaster_Fkts_LED 0 "LED_aus" 1 "LED_ein" ;
VAL_ 1626 LRH_Taster 0 "nicht_betaetigt" 1 "betaetigt" ;
VAL_ 1626 APS_Tongeber_defekt 0 "iO" 1 "defekt" ;
VAL_ 1626 BCM1_EasyEntry_Status 0 "Aus" 1 "Ein" ;
VAL_ 1626 BCM1_Lenksaeule_aktiv 0 "Lenksaeulenverstellung nicht aktiv" 1 "Lenksaeulenverstellung aktiv" ;
VAL_ 1626 BCM1_Spannungs_Anf 0 "keine_Anforderung" 1 "Anforderung_Stufe_1" 2 "Anforderung_Stufe_2" 3 "Anforderung_Stufe_3" ;
VAL_ 1626 DWA_Alarmquelle 0 "kein_Ausloesegrund" 1 "Tuerkontakt_Fahrertuer" 2 "Tuerkontakt_Beifahrertuer" 3 "Tuerkontakt_hinten_links" 4 "Tuerkontakt_hinten_rechts" 5 "Motorhaubenkontakt_vorne" 6 "Kofferraum_hinten" 7 "Masseschleife_der_Heckscheibe" 8 "Innenraumueberwachung" 9 "Alarm_durch_Noteinstieg" 10 "Sounder" 11 "Neigungssensor" 12 "TSG_FT_am_CAN_Bus" 13 "TSG_BT_am_CAN_Bus" 14 "TSG_HFS_am_CAN_Bus" 15 "TSG_HBFS_am_CAN_Bus" 16 "Klemme_15" 17 "Klemme_15sig" 18 "frei" 19 "Anhaengerueberwachung" 20 "Scheinwerferueberwachung_links" 21 "Scheinwerferueberwachung_rechts" 22 "Handschuhkasten" 23 "Verdeckueberwachung" 24 "OBD_Alarm" 25 "Power_on_Reset" 30 "Init" 31 "Fehler" ;
VAL_ 1626 DWA_Einschraenkung 0 "Init" 1 "Fehler" ;
VAL_ 1626 BCM_HBFS_EOE_aktiv 0 "EOE_inaktiv" 1 "EOE_aktiv" ;
VAL_ 1626 BCM_HFS_EOE_aktiv 0 "EOE_inaktiv" 1 "EOE_aktiv" ;
VAL_ 1626 BCM_Anf_AAW_MoLaWa 0 "Init" 1 "AAW_angefordert" 2 "MoLaWa_angefordert" ;
VAL_ 1626 BCM_Handbremse_Hinweis 0 "inaktiv" 1 "aktiv" ;
VAL_ 1626 BCM_Waehlhebel_P_Hinweis 0 "inaktiv" 1 "aktiv" ;
VAL_ 1626 BCM1_Fahrlicht_Hinweis 0 "kein_Fahrlicht_Hinweis" 1 "Fahrlicht_Hinweis" ;
VAL_ 1626 BCM_HDF_betaetigt 0 "nicht_betaetigt" 1 "betaetigt" ;
VAL_ 2527679637 BCM_FAS_Taster 0 "nicht_betaetigt" 1 "betaetigt" ;
VAL_ 2527679637 CPD_Warnung 0 "keine_Warnung" 1 "Warnung_mit_Ton" 2 "Warnung_ohne_Ton" ;
VAL_ 2527679637 MiKo_Tisch_Positionswarnung 0 "keine_Anzeige_Tisch_unten" 1 "Warnung_Tisch_oben" ;
VAL_ 2527679637 LiSi_Touch_Event 0 "nicht_betaetigt" 1 "Tippen" 2 "Wischen_Slide" 3 "Geste" 4 "Doppeltippen" 5 "Longpress_1" 6 "Longpress_2" 7 "Longpress_3" 8 "Press" 9 "Strongpress" 10 "reserviert" 11 "reserviert" 12 "reserviert" 13 "reserviert" 14 "Taktgeber_Inkrement" 15 "Fehler" ;
VAL_ 2527679637 BCM_anf_VLW 0 "Init" 1 "VLW_angefordert_VLK2_1" 2 "deg_VLW_FT_angefordert" 3 "deg_VLW_Werkstatt_angefordert" 4 "VLW_angefordert_VLK2_2" 5 "Wegrollwarnung_angefordert" 6 "Rollfaehigkeit_ohne_Akustik" 7 "Rollfaehigkeit_mit_Akustik" ;
VAL_ 2527679637 BCM_Defrost_Taste 0 "Taste_nicht_betaetigt" 1 "Taste_betaetigt" 2 "Fehler" 3 "Init_oder_nicht_verbaut" ;
VAL_ 2527679637 BCM_HSH_Taste 0 "Taste_nicht_betaetigt" 1 "Taste_betaetigt" 2 "Fehler" 3 "Init_oder_nicht_verbaut" ;
VAL_ 2527679637 BCM_FSH_Taste 0 "Taste_nicht_betaetigt" 1 "Taste_betaetigt" 2 "Fehler" 3 "Init_oder_nicht_verbaut" ;
VAL_ 2527679637 LTMs_01_alt 0 "aktuell" 1 "veraltet" ;
VAL_ 2527679637 BCM_LTM_Nebelschluss_Status 0 "nicht_aktiv" 1 "aktiv" ;
VAL_ 2527679637 BCM_LTM_PopUp_Texte 0 "keine_Anzeige" 1 "Ausschalt_Hinweis" 2 "Ausschalt_Quittierung" ;
VAL_ 2527679637 BCM_LTM_Allwetterl_Status 0 "nicht_aktiv" 1 "aktiv" ;
VAL_ 2527679637 BCM_LTM_PopUp_Status 0 "Init" 1 "AUTO" 2 "Abblendlicht" 3 "Standlicht" 4 "OFF" ;
VAL_ 2527679637 BCM_LTM_Nebell_Status 0 "nicht_aktiv" 1 "aktiv" ;
VAL_ 2527679637 BCM_LTM_PopUp_Anf 0 "keine_Anforderung" 1 "Licht_PopUp" 2 "Nebellicht_PopUp" 3 "Allwetterlicht_PopUp" 4 "Nebelschlusslicht_PopUp" ;
VAL_ 2527679637 BCM_LTM_PopUp_Inhalt 0 "Init" 1 "AUTO" 2 "Abblendlicht" 4 "Standlicht" 8 "OFF" ;
VAL_ 2463978609 HSH_LED 0 "Aus" 1 "Ein" ;
VAL_ 2463978609 HSH_Status 0 "aus" 1 "ein" 2 "tbd" 3 "Fehler" ;
VAL_ 2463978609 BCM_Relais_2_Batterie 0 "nicht_betaetigt" 1 "betaetigt" ;
VAL_ 2463978609 Niveausensor_HL_verbaut 0 "nicht_verbaut" 1 "verbaut" ;
VAL_ 2463978609 Niveausensor_VL_verbaut 0 "nicht_verbaut" 1 "verbaut" ;
VAL_ 2463978609 KRH_Stufe_LED_re 0 "Aus" 1 "Stufe_1" 2 "Stufe_2" 3 "Stufe_3" ;
VAL_ 2463978609 KRH_Stufe_LED_li 0 "Aus" 1 "Stufe_1" 2 "Stufe_2" 3 "Stufe_3" ;
VAL_ 2463978609 SIL_Stufe_LED_re 0 "Aus" 1 "Stufe_1" 2 "Stufe_2" 3 "Stufe_3" 4 "Stufe_4" 5 "Stufe_5" 6 "Stufe_6" ;
VAL_ 2463978609 SIL_Stufe_LED_li 0 "Aus" 1 "Stufe_1" 2 "Stufe_2" 3 "Stufe_3" 4 "Stufe_4" 5 "Stufe_5" 6 "Stufe_6" ;
VAL_ 2463978609 FA_Hoehenwert_VL_01 254 "nicht initialisiert" 255 "Fehler" ;
VAL_ 2463978609 FA_Hoehenwert_HL_01 254 "nicht initialisiert" 255 "Fehler" ;
VAL_ 1635 NVEM_Abschaltstufe 0 "Stufe_0_keine_Einschraenkung" 1 "Stufe_1" 2 "Stufe_2" 3 "Stufe_3" ;
VAL_ 1635 BEM_STH_Zielzeit 14 "Init" 15 "Fehler" ;
VAL_ 1635 BEM_MMI_Vorwarnung 0 "keine Anzeige" 1 "Anzeige MMI-Vorwarnung" ;
VAL_ 1635 NVEM_Freigabe_ZusBatt_Laden 0 "keine_Freigabe_Laderelais" 1 "Freigabe_Laderelais_schliessen" ;
VAL_ 1635 NVEM_Anf_SD_schalten 0 "Anf_SD_Nachlauf_nicht_aktiv" 1 "Anf_SD_Nachlauf_aktiv" ;
VAL_ 1635 BEM_Generatordiagnose 0 "keine Anzeige" 1 "Ladekontrollanzeige ein (Vorhalt)" 2 "rotes Batteriesymbol und Text (Generator defekt)" 3 "Hybrid_DCDC_Wandler_defekt" ;
VAL_ 1635 BEM_Red_Innengeblaese 0 "keine Reduzierung" 1 "Reduzierung Stufe 1" 2 "Reduzierung Stufe 2" 3 "Reduzierung Stufe 2 und Abschaltung Kompressor" ;
VAL_ 1635 BEM_STH_Einschaltverbot 0 "volle Verfuegbarkeit Standheizung/-lueftung" 1 "Standheizung/-lueftung nicht aktivierbar" ;
VAL_ 1635 BEM_HL_Regelung_Status 0 "HL_Regelung_inaktiv_(vor_und_waehrend_Motorstart)" 1 "HL_Regelung_Stufe_1" 2 "HL_Regelung_Stufe_2" 3 "HL_Regelung_Stufe_3" 4 "Verbrauchernotabschaltung_(VNA)" 5 "HL_Regelung_Stufe_5" 7 "Default" ;
VAL_ 1635 BEM_Ladezustand 14 "Init" 15 "Fehler" ;
VAL_ 1635 BEM_Batteriediagnose 0 "keine_Anzeige" 1 "nicht_belegt" 2 "Anzeige_aberkannte_Batterie" 3 "Anzeige_schwache_Batterie" 4 "Anzeige_Batterie_OK" 5 "Anzeige_Batterie_Laden" 6 "Anzeige_Batterie_Pruefen" 7 "Fehler" ;
VAL_ 1635 MIB_Stromsparmodus 0 "inaktiv" 1 "aktiv" ;
VAL_ 1635 BEM_REK_aktiv 0 "keine_Rekuperationsfreigabe" 1 "Rekuperationsfreigabe" ;
VAL_ 1635 BEM_EMLIN_ungueltig 0 "Signale_gueltig" 1 "Signale_ungueltig" ;
VAL_ 1635 BEM_Batt_Ab 0 "verbunden" 1 "nicht_verbunden" ;
VAL_ 1635 BEM_UBDM 0 "Init" 255 "Fehler" ;
VAL_ 1635 BEM_Anf_KL15_schalten 0 "Keine_Einschraenkung_Kl15" 1 "Empfehlung_auto_Abschaltung_Kl15" 2 "Veto_auto_Abschaltung_Kl15" 3 "Veto_auto_Abschaltung_Fahrtbetrieb" ;
VAL_ 1635 NVEM_Batterie_Service 0 "kein_Service" 1 "Service_Information1" 2 "Service_Information2" 3 "Service_Information3" ;
VAL_ 1635 NVEM_Freigabe_OnlineUpdate 0 "keine_Freigabe" 1 "Freigabe" ;
VAL_ 1635 NVEM_Freigabe_ORU4 0 "Init" 1 "keine_Freigabe" 2 "Freigabe_erteilt" 3 "Veto_Freigabe" ;
VAL_ 1635 NVEM_Verbraucherabsch_Anz 0 "keine_Anzeige" 1 "Anzeige_aktiv" ;
VAL_ 1163 NVEM_Betriebsart 0 "oKl15_Sing_oVerbr" 1 "oKl15_Red_RedKontingent_oVerbr" 2 "oKl15_Red_HohKontingent_oVerbr" 3 "oKl15_Red_mVerbr" 4 "reserved" 5 "reserved" 6 "reserved" 7 "reserved" 8 "mKl15_Sing_oVerbr" 9 "mKl15_Red_RedKontingent_oVerbr" 10 "mKl15_Red_HohKontingent_oVerbr" 11 "mKl15_Red_mVerbr" 12 "Fahrbereitschaft_mVerbr" 13 "reserved" 14 "reserved" 15 "Fehler" ;
VAL_ 1163 NVEM_Ladezustand 126 "INIT" 127 "Fehler" ;
VAL_ 1163 NVEM2_Status_FuSiFahrt 0 "Init" 1 "Keine_FuSi_Fahrt" 2 "Qualifikation_FuSi_Fahrt" 3 "FuSi_Fahrt_Aktiv" 4 "Qualifikation_Ende_FuSi_Fahrt" 5 "FuSi_Stand" 6 "FuSi_Nachlauf" 7 "Fehler" ;
VAL_ 1163 NVEM_Energienetz_Status 0 "QM" 1 "ASIL_A" 2 "ASIL_B" 3 "ASIL_C" 6 "InitWert" 7 "Fehler" ;
VAL_ 1163 NVEM_Vorgabe_Leistungsstufe 0 "Init" 1 "Leistungsstufe_0" 2 "Leistungsstufe_1" 3 "Leistungsstufe_2" 4 "Leistungsstufe_3" 5 "Leistungsstufe_4" 6 "Leistungsstufe_5" 7 "Fehler" ;
VAL_ 1163 NVEM2_Typ_EnergieNetz 0 "Sp12V_Gen_ICE" 1 "Sp12V_BEV" 2 "Sp12V_PHEV" 3 "Sp12V_MHEV" 4 "Sp12V_HEV" 5 "Sp12V_Sp48V_Gen_Insel" 6 "Sp12V_Sp12V_RSG_MHEV12V" 7 "Sp12V_BEV_ASILC" 14 "Fehler" 15 "Init" ;
VAL_ 1163 NVEM_Energie_Klima_Vorgabe 254 "Init" 255 "Fehler" ;
VAL_ 1163 NVEM_Last_Anf 0 "keine Anforderung" 1 "Verbraucher_Anforderung_Stufe_1" 2 "Verbraucher_Anforderung_Stufe_2" 3 "Verbraucher_Anforderung_Stufe_3" ;
VAL_ 1163 NVEM_STH_ZielzeitLang 14 "Init" 15 "Fehler" ;
VAL_ 1163 NVEM_Red_KomfortVerbrauch 0 "keine_Einschraenkung" 1 "Einschraenkung_Stufe_1" 2 "Einschraenkung_Stufe_2" 3 "Einschraenkung_Stufe_3" 4 "Einschraenkung_Stufe_4" 5 "Einschraenkung_Stufe_5" 6 "Einschraenkung_Stufe_6" 7 "Einschraenkung_Stufe_7" 8 "Einschraenkung_Stufe_8" 15 "Fehler" ;
VAL_ 1163 NVEM_PTC_Sollstufe 0 "Aus" 1 "Stufe_1" 2 "Stufe_2" 3 "Stufe_3" ;
VAL_ 1163 NVEM_Bordnetzdiagnose 0 "kein_Fehler" 1 "Warnung_1" 2 "Warnung_2" 3 "Warnung_3" ;
VAL_ 1163 HLR_PTC_linear_Freigabe 63 "Fehler" ;
VAL_ 2463978850 NVEM_Bordnetz_Information 0 "keine_Anzeige" 1 "NV_Batterie_iO" 2 "NV_Batterie_laden" 3 "NV_Batterie_pruefen" 4 "NV_Batterie_schwach" 5 "NV_Batterie_Ab" 6 "NV_Batterie_Service" 7 "NV_Energiesystem_unplausibel" 8 "Ladekontrollleuchte" 9 "Generator_defekt" 10 "reserviert" 11 "reserviert" 12 "reserviert" 13 "reserviert" 14 "Init" 15 "Fehler" ;
VAL_ 2463978850 NVEM_Verbraucher_Information 0 "Keine_Anzeige" 1 "MMI_Vorwarnung" 2 "Anzeige_Verbraucherabschaltung" 3 "reserviert" 4 "reserviert" 5 "reserviert" 6 "Init" 7 "Fehler" ;
VAL_ 2463978850 NVEM2_VerbrZustandsAnf 0 "Freigabe" 1 "Verbraucher_Sperren" 2 "Verbr_Sperren_KL_Red" 3 "reserved" 4 "reserved" 5 "reserved" 6 "Verbr_Sperren_KL_Anf" 7 "Teilweise_Anschalt_Anf" 8 "Anschalt_Anf" 9 "reserved" 10 "reserved" 11 "Abschaltstufe_1" 12 "Abschaltstufe_2" 13 "Abschaltstufe_3" 14 "Init" 15 "Fehler" ;
VAL_ 2463978850 NVEM_NVStuetzungAnf 0 "keine_Anforderung" 1 "Anforderung_sichere_Versorgung" 2 "Anforderung_Abschaltung" 3 "Fehler" ;
VAL_ 2463978850 NVEM3_Absch_SCR 0 "Init" 1 "Abschaltung_SCR" ;
VAL_ 2463978850 NVEM_Batt_Temp_Hinweis 0 "Keine_Anzeige" 1 "Hinweis_Aussenhuelle_zu" 2 "Hinweis_Klima_ein" 3 "Wunsch_Aussenhuelle_zu" 4 "Wunsch_Klima_ein" ;
VAL_ 1442 BMS_Fehler_Pilot 0 "geschlossen" 1 "Unterbrechung" ;
VAL_ 1442 BMS_Status_ServiceDisconnect 0 "gesteckt" 1 "gezogen" ;
VAL_ 1442 BMS_Status_Spgfreiheit 0 "Init" 1 "HV_Komponente_spannungsfrei" 2 "HV_Komp_nicht_spannungsfrei" 3 "Fehler_nicht_spannungsfrei" ;
VAL_ 1442 BMS_OBD_Lampe_Anf 0 "kein_MIL_Request" 1 "MIL_Request" ;
VAL_ 1442 BMS_Fehlerstatus 0 "Komponente_IO" 1 "Eingeschr_KompFkt_Isofehler_I" 2 "Eingeschr_KompFkt_Isofehler_II" 3 "Eingeschr_KompFkt_Interlock" 4 "Eingeschr_KompFkt_SD" 5 "Eingeschr_KompFkt_Leistungsred" 6 "Keine_Komponentenfunktion" 7 "Init" ;
VAL_ 1442 BMS_Kapazitaet_02 2047 "Init" ;
VAL_ 1442 BMS_Fehlerlampe_Anf 1 "RedLED_Request" ;
VAL_ 1442 BMS_Warnlampe_Anf 1 "YellowLED_Request" ;
VAL_ 1442 BMS_Kl30c_Status 0 "Init" 1 "geschlossen" 2 "offen" 3 "Fehler" ;
VAL_ 687 BMC_Spannung 16381 "Null_Bank" 16382 "Init" 16383 "Fehler" ;
VAL_ 687 BMS_As_Entladezaehler_Ueberlauf 0 "kein_Ueberlauf" 1 "Ueberlauf" ;
VAL_ 687 BMS_Rekuperation_Ueberlauf 0 "kein_Ueberlauf" 1 "Ueberlauf" ;
VAL_ 687 BMS_Verbrauch_Ueberlauf 0 "kein_Ueberlauf" 1 "Ueberlauf" ;
VAL_ 1482 BMS_Energieinhalt 2046 "Init" 2047 "Fehler" ;
VAL_ 1482 BMS_Ladevorgang_aktiv 0 "inaktiv" 1 "aktiv" ;
VAL_ 1482 BMS_Batteriediagnose 1 "Anzeige_Batterie" 4 "Anzeige_Batterie_OK" 5 "Anzeige_Batterie_Laden" 6 "Anzeige_Batterie_Pruefen" 7 "Fehler" ;
VAL_ 1482 BMS_Balancing_Aktiv 0 "Init" 1 "aktiv" 2 "nicht_aktiv" ;
VAL_ 1482 BMS_MaxEnergieinhalt 2046 "Init" 2047 "Fehler" ;
VAL_ 1482 BMS_Ausgleichsladung_Anf 1 "Balancing_Request" ;
VAL_ 1482 BMS_Gesamtst_Spgfreiheit 0 "Funktion_nicht_aktiviert" 1 "HV_System_spannungsfrei" 2 "HV_System_nicht_spannungsfrei" 3 "Fehler_nicht_spannungsfrei" ;
VAL_ 1482 BMS_RIso_Ext 4094 "Init" 4095 "Fehler" ;
VAL_ 1482 BMS_KundenWarnung 0 "keine_Warnung" 1 "Warnung_Temperatur_Level1" 2 "Warnung_Temperatur_Level2" ;
VAL_ 2527679654 BMS_IsoZustand 0 "Init_kein_Diagnoseergebnis" 1 "groesser_Schwelle_1" 2 "kleiner_Schwelle_1_gesamt" 3 "kleiner_Schwelle_1_intern" 4 "kleiner_Schwelle_2_gesamt" 5 "kleiner_Schwelle_2_intern" 6 "kein_Messwert" 7 "Messung_aktiv" ;
VAL_ 2527679654 BMS_IsoFehler 0 "Init" 1 "kein_IsoFehler" 2 "IsoFehler_Schwelle_1" 3 "IsoFehler_Schwelle_2" 4 "IWU_defekt" 5 "reserviert" 6 "reserviert" 7 "reserviert" ;
VAL_ 2527679654 BMS_IstTemperatur_hoechste 253 "reserviert" 254 "Init" 255 "Fehler" ;
VAL_ 2527679654 BMS_IstTemperatur_niedrigste 253 "reserviert" 254 "Init" 255 "Fehler" ;
VAL_ 2527679654 BMS_IstZellspannung_hoechste 4092 "reserviert" 4093 "reserviert" 4094 "Init" 4095 "Fehler" ;
VAL_ 2527679654 BMS_IstZellspannung_niedrigste 4092 "reserviert" 4093 "reserviert" 4094 "Init" 4095 "Fehler" ;
VAL_ 207 BMS_Fehlerstatus_HV_Schuetze 0 "Init_kein_Diagnoseergebnis" 1 "kein_Schuetz_verschweisst" 2 "mind_1_Schuetz_verschweisst" 3 "Fehler_Schuetzstatuserkennung" ;
VAL_ 207 BMS_ErwGrenzen_aktiv 0 "Init" 1 "extended_Range" ;
VAL_ 207 BMS_IstModus 0 "HV_inaktiv" 1 "Fahren_HV_aktiv" 2 "stBalancing" 3 "externes_Laden" 4 "AC_Laden" 5 "Error_Batt" 6 "DC_Laden" 7 "Init" ;
VAL_ 207 BMS_HVIL_Status 0 "Init" 1 "geschlossen" 2 "offen" 3 "Fehler" ;
VAL_ 207 BMS_Fehler_HVBattAbschaltung 1 "Err_ShutOff" ;
VAL_ 207 BMS_Fehler_HVBattAbschaltung_Anf 1 "Err_ShutOffRequest" ;
VAL_ 207 BMS_Fehler_Leistungsred 0 "keine_Leistungseinschraenkung" 1 "Leistungseinschraenkung" ;
VAL_ 207 BMS_Strom 32765 "nicht_messbar" 32766 "Init" 32767 "Fehler" ;
VAL_ 207 BMS_Fehler_Notabschaltung_Crash 1 "Err_EmergcyShtOffCrash" ;
VAL_ 207 BMS_Spannung_Zwischenkreis 4093 "nicht_messbar" 4094 "Init" 4095 "Fehler" ;
VAL_ 207 BMS_Spannung 4093 "nicht_messbar" 4094 "Init" 4095 "Fehler" ;
VAL_ 2463978704 BMS_Max_Entladestrom 8190 "Init" ;
VAL_ 2463978704 BMS_Max_Ladestrom 8190 "Init" ;
VAL_ 2463978704 BMS_Max_Entladeleistung 8190 "Init" ;
VAL_ 2463978704 BMS_Max_Ladeleistung 8190 "Init" ;
VAL_ 2463978705 BMS_Warnung_Stuetzung_NV 0 "Stuetzung_iO" 1 "Stuetzung_niO" 6 "Init" 7 "Fehler" ;
VAL_ 2463978705 BMS_Status_EoHVL_Heizer 0 "Init" 1 "Keine_offene_HV_Leitung_erkannt" 2 "offene_HV_Leitung_erkannt" 3 "Fehler" ;
VAL_ 2463978705 BMS_Ladezustand 2046 "Init" 2047 "Fehler" ;
VAL_ 2463978705 BMS_PerfInd_Entladen 1022 "Init" ;
VAL_ 2463978705 BMS_PerfInd_Laden 1022 "Init" ;
VAL_ 2463978705 BMS_Nutzbare_EntladeEnergie 65534 "Init" 65535 "Fehler" ;
VAL_ 2589283664 BMS_Balancing_Aktiv 0 "Init" 1 "aktiv" 2 "nicht_aktiv" ;
VAL_ 2589283664 BMS_Ladevorgang_aktiv 0 "inaktiv" 1 "aktiv" ;
VAL_ 2589283664 BMS_RIso_Ext 4094 "Init" 4095 "Fehler" ;
VAL_ 2589283664 BMS_Min_Ladezustand 2046 "Init" ;
VAL_ 2589283664 BMS_Max_Energie 8190 "Init" ;
VAL_ 2589283664 BMS_Max_Ladezustand 2046 "Init" ;
VAL_ 2589283665 BMS_BattHeizung_VerbautStatus 0 "nicht_verbaut" 1 "verbaut" ;
VAL_ 2589283665 BMS_Fehler_NTKreis 0 "kein_Fehler" 1 "Fehler" ;
VAL_ 2589283665 BMS_Temperierung_Anf 0 "hoher_Kuehlbedarf" 1 "mittlerer_Kuehlbedarf" 2 "niedriger_Kuehlbedarf" 3 "kein_Temperierungsbedarf_Init" 4 "niedriger_Heizbedarf" 5 "mittlerer_Heizbedarf" 6 "hoher_Heizbedarf" 7 "Umwaelzungsbedarf" ;
VAL_ 2589283665 BMS_Status_Ventil1 0 "Ventil_nicht_angesteuert" 1 "Ventil_angesteuert" 2 "reserviert" 3 "reserviert" 4 "reserviert" 5 "Ventil_nicht_verbaut" 6 "Init" 7 "Fehler" ;
VAL_ 2589283665 BMS_Status_Ventil2 0 "Ventil_nicht_angesteuert" 1 "Ventil_angesteuert" 2 "reserviert" 3 "reserviert" 4 "reserviert" 5 "Ventil_nicht_verbaut" 6 "Init" 7 "Fehler" ;
VAL_ 2589283665 BMS_Pumpe1_Ansteuerung 13 "nicht_verbaut" 14 "Init" 15 "Fehler" ;
VAL_ 2589283665 BMS_Pumpe2_Ansteuerung 13 "nicht_verbaut" 14 "Init" 15 "Fehler" ;
VAL_ 2589283665 BMS_VorlaufTemperatur 253 "nicht_verbaut" 254 "Init" 255 "Fehler" ;
VAL_ 2589283665 BMS_Temperatur 254 "Init" 255 "Fehler" ;
VAL_ 2589283665 BMS_SollVorlauftemperatur 254 "Init" 255 "Fehler" ;
VAL_ 2589283665 BMS_RuecklaufTemperatur 253 "nicht_verbaut" 254 "Init" 255 "Fehler" ;
VAL_ 2589283760 BMS_Max_Spannung 1022 "Init" ;
VAL_ 2589283760 BMS_Min_Spannung 1022 "Init" ;
VAL_ 2589283760 BMS_Dauer_Entladeleistung 4094 "Init" ;
VAL_ 2589283760 BMS_Dauer_Ladeleistung 4094 "Init" ;
VAL_ 2589283762 BMS_TempStatus_Entladen 0 "Init" 1 "Temperatur_kleiner_optimal" 2 "Temperatur_optimal" 3 "Temperatur_groesser_optimal" 7 "Fehler" ;
VAL_ 2589283762 BMS_TempStatus_Laden 0 "Init" 1 "Temperatur_kleiner_optimal" 2 "Temperatur_optimal" 3 "Temperatur_groesser_optimal" 7 "Fehler" ;
VAL_ 2589283762 BMS_PerfInd_EntladenPeak_Temp 510 "Init" 511 "Fehler" ;
VAL_ 2589283762 BMS_PerfInd_LadenPeak_Temp 510 "Init" 511 "Fehler" ;
VAL_ 2589283762 BMS_TMA_Kuehlkreis_Status 0 "Off" 1 "Umwaelzbetrieb" 2 "Kuehlung_1_Kreis_Betrieb" 3 "Heizung_1_Kreis_Betrieb" 4 "Aktive_Kuehlung_2_Kreis_Betrieb" 5 "Aktive_Heizung_2_Kreis_Betrieb" 15 "Fehler" ;
VAL_ 2589283762 BMS_TMA_Betriebsart 0 "BA_TMA_Off" 1 "BA_TMA_Drv" 2 "BA_TMA_DrvLadVoKo" 3 "BA_TMA_AC" 4 "BA_TMA_DC" 5 "BA_TMA_BiDi" 6 "BA_TMA_HeatTransferWP" 7 "BA_TMA_VoKo" 8 "BA_TMA_Nachlauf" 9 "BA_TMA_OffgridAuto" 10 "BA_TMA_OffgridBCCM" 11 "BA_TMA_KonservierungBCCM" 12 "BA_TMA_NachlaufBCCM" 26 "BA_TMA_Transport" 27 "BA_TMA_BremsReku" 28 "BA_TMA_Befuellung" 29 "BA_TMA_RoutineControl" 30 "Init" 31 "Fehler" ;
VAL_ 2589283762 BMS_eTM_KonditionierWunsch 0 "kein_Temperierwunsch" 1 "Kuehlwunsch" 2 "Heizwunsch" ;
VAL_ 2589283762 BMS_SollVolumenstrom 62 "Init" 63 "Fehler" ;
VAL_ 2331595856 BMS_UBE 65534 "Init" 65535 "Fehler" ;
VAL_ 2331595856 BMS_UBE_T 65534 "Init" 65535 "Fehler" ;
VAL_ 2331595856 BMS_Max_UBE 65534 "Init" 65535 "Fehler" ;
VAL_ 2331595856 BMS_Nennspannung 2046 "Init" ;
VAL_ 2331595856 BMS_DC_Ladeschuetze_Ist 0 "geoeffnet" 1 "geschlossen" 2 "reserviert" 3 "reserviert" 4 "reserviert" 5 "nicht_verbaut" 6 "Init" 7 "Schuetzfehler" ;
VAL_ 2331595856 BMS_Hauptschuetze_Ist 0 "geoeffnet" 1 "geschlossen" 2 "reserviert" 3 "reserviert" 4 "reserviert" 5 "nicht_verbaut" 6 "Init" 7 "Schuetzfehler" ;
VAL_ 2331595856 BMS_UBE_Indikator 2042 "Funktion_nicht_vorhanden" 2043 "kleiner_0" 2044 "groesser_100" 2045 "nicht_angelernt" 2046 "Init" 2047 "Fehler" ;
VAL_ 2331595856 BMS_UBE_Indik_last_update_km 1048573 "Funktion_nicht_umgesetzt" 1048574 "Init" 1048575 "Fehler" ;
VAL_ 2331595856 BMS_Last_Chg_adeq_SOCswing_Day 0 "Funktion_nicht_verwendet" ;
VAL_ 2331595856 BMS_Last_Chg_adeq_SOCswing_Month 0 "Funktion_nicht_verwendet" ;
VAL_ 2331595856 BMS_Last_Chg_adeq_SOCswing_Year 0 "Funktion_nicht_verwendet" ;
VAL_ 2331595856 BMS_EnergieVorhalt 65533 "Funktion_nicht_umgesetzt" 65534 "Init" 65535 "Fehler" ;
VAL_ 2331595856 BMS_Range_Indikator 2042 "Funktion_nicht_vorhanden" 2043 "kleiner_0" 2044 "groesser_100" 2045 "nicht_angelernt" 2046 "Init" 2047 "Fehler" ;
